VERSION "HNPBNNNYNNNNNNNNNNNNNNNNNNNNNNNNYNYYYYYYYY>4>%%%/4>'%**4YYY///"

NS_ :

BS_:

BU_: TESTER TCU BMU2 CSM CMU_TEST CMU_12 CMU_11 CMU_10 CMU_09 CMU_08 CMU_07 CMU_06 CMU_05 CMU_04 CMU_03 CMU_02 CMU_01 CMU_00 BMU

BO_ 1151 NM_TCU: 8 TCU
 SG_ NM_TCU : 7|64@0+ (1,0) [0|0] "" Vector__XXX

BO_ 1847 D_RS_DAS_TCU: 8 TCU
 SG_ D_RS_DAS_TCU : 7|64@0+ (1,0) [0|0] ""  TESTER

BO_ 1846 D_RQ_DAS_TCU: 8 TESTER
 SG_ D_RQ_DAS_TCU : 7|64@0+ (1,0) [0|0] ""  TCU

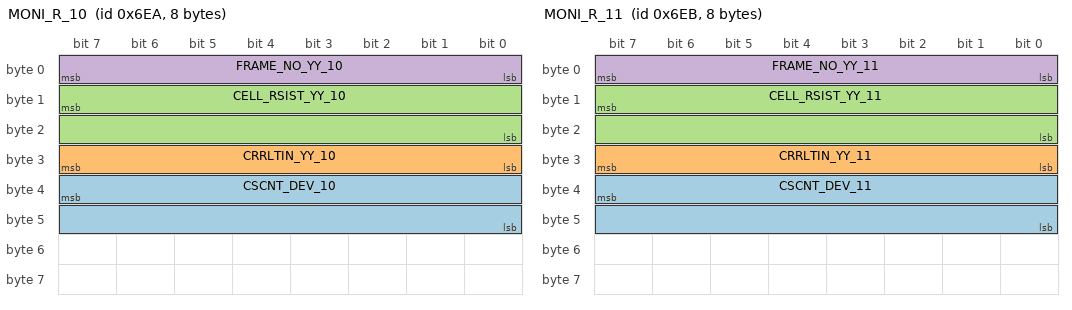
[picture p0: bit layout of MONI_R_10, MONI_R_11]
BO_ 1770 MONI_R_10: 8 BMU2
 SG_ CSCNT_DEV_10 : 39|16@0+ (0.1,0) [0|800] "A"  TCU,CMU_TEST
 SG_ CRRLTIN_YY_10 : 24|8@1+ (0.01,-1) [-1|1] ""  TCU,CMU_TEST
 SG_ CELL_RSIST_YY_10 : 15|16@0+ (0.01,0) [0|655.34] "mohm"  TCU,CMU_TEST
 SG_ FRAME_NO_YY_10 : 0|8@1+ (1,0) [0|8] ""  CMU_TEST

BO_ 1771 MONI_R_11: 8 BMU2
 SG_ CSCNT_DEV_11 : 39|16@0+ (0.1,0) [0|800] "A"  TCU,CMU_TEST
 SG_ CRRLTIN_YY_11 : 24|8@1+ (0.01,-1) [-1|1] ""  TCU,CMU_TEST
 SG_ CELL_RSIST_YY_11 : 15|16@0+ (0.01,0) [0|655.34] "mohm"  TCU,CMU_TEST
 SG_ FRAME_NO_YY_11 : 0|8@1+ (1,0) [0|8] ""  CMU_TEST

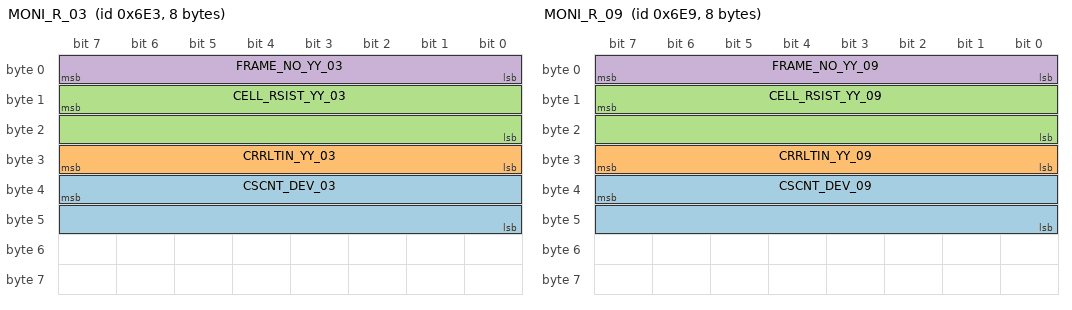
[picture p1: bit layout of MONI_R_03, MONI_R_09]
BO_ 1763 MONI_R_03: 8 BMU2
 SG_ CSCNT_DEV_03 : 39|16@0+ (0.1,0) [0|800] "A"  TCU,CMU_TEST
 SG_ CRRLTIN_YY_03 : 24|8@1+ (0.01,-1) [-1|1] ""  TCU,CMU_TEST
 SG_ CELL_RSIST_YY_03 : 15|16@0+ (0.01,0) [0|655.34] "mohm"  TCU,CMU_TEST
 SG_ FRAME_NO_YY_03 : 0|8@1+ (1,0) [0|8] ""  CMU_TEST

BO_ 1769 MONI_R_09: 8 BMU2
 SG_ CSCNT_DEV_09 : 39|16@0+ (0.1,0) [0|800] "A"  TCU,CMU_TEST
 SG_ CRRLTIN_YY_09 : 24|8@1+ (0.01,-1) [-1|1] ""  TCU,CMU_TEST
 SG_ CELL_RSIST_YY_09 : 15|16@0+ (0.01,0) [0|655.34] "mohm"  TCU,CMU_TEST
 SG_ FRAME_NO_YY_09 : 0|8@1+ (1,0) [0|8] ""  CMU_TEST

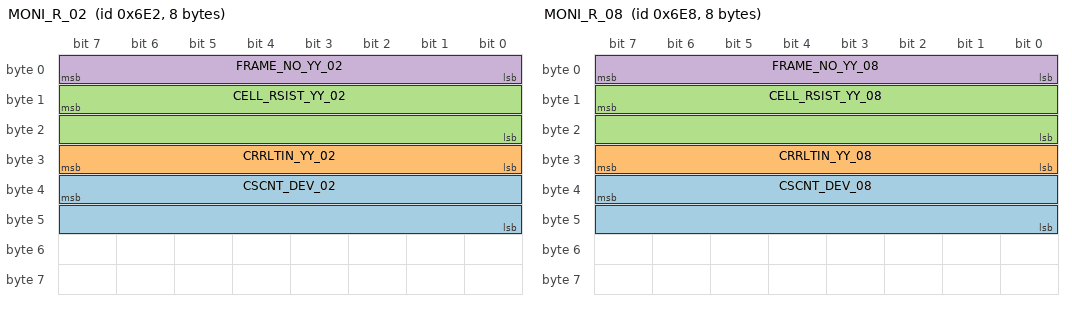
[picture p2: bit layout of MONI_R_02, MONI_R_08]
BO_ 1762 MONI_R_02: 8 BMU2
 SG_ CSCNT_DEV_02 : 39|16@0+ (0.1,0) [0|800] "A"  TCU,CMU_TEST
 SG_ CRRLTIN_YY_02 : 24|8@1+ (0.01,-1) [-1|1] ""  TCU,CMU_TEST
 SG_ CELL_RSIST_YY_02 : 15|16@0+ (0.01,0) [0|655.34] "mohm"  TCU,CMU_TEST
 SG_ FRAME_NO_YY_02 : 0|8@1+ (1,0) [0|8] ""  CMU_TEST

BO_ 1768 MONI_R_08: 8 BMU2
 SG_ CSCNT_DEV_08 : 39|16@0+ (0.1,0) [0|800] "A"  TCU,CMU_TEST
 SG_ CRRLTIN_YY_08 : 24|8@1+ (0.01,-1) [-1|1] ""  TCU,CMU_TEST
 SG_ CELL_RSIST_YY_08 : 15|16@0+ (0.01,0) [0|655.34] "mohm"  TCU,CMU_TEST
 SG_ FRAME_NO_YY_08 : 0|8@1+ (1,0) [0|8] ""  CMU_TEST

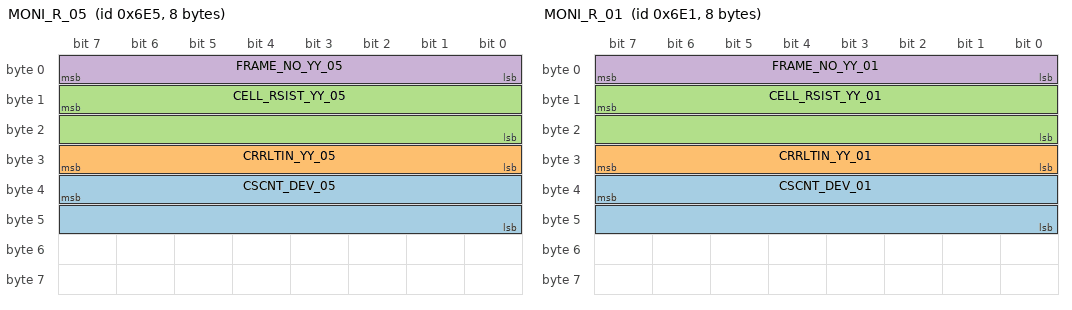
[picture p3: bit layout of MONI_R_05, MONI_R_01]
BO_ 1765 MONI_R_05: 8 BMU2
 SG_ CSCNT_DEV_05 : 39|16@0+ (0.1,0) [0|800] "A"  TCU,CMU_TEST
 SG_ CRRLTIN_YY_05 : 24|8@1+ (0.01,-1) [-1|1] ""  TCU,CMU_TEST
 SG_ CELL_RSIST_YY_05 : 15|16@0+ (0.01,0) [0|655.34] "mohm"  TCU,CMU_TEST
 SG_ FRAME_NO_YY_05 : 0|8@1+ (1,0) [0|8] ""  CMU_TEST

BO_ 1761 MONI_R_01: 8 BMU2
 SG_ CSCNT_DEV_01 : 39|16@0+ (0.1,0) [0|800] "A"  TCU,CMU_TEST
 SG_ CRRLTIN_YY_01 : 24|8@1+ (0.01,-1) [-1|1] ""  TCU,CMU_TEST
 SG_ CELL_RSIST_YY_01 : 15|16@0+ (0.01,0) [0|655.34] "mohm"  TCU,CMU_TEST
 SG_ FRAME_NO_YY_01 : 0|8@1+ (1,0) [0|8] ""  CMU_TEST

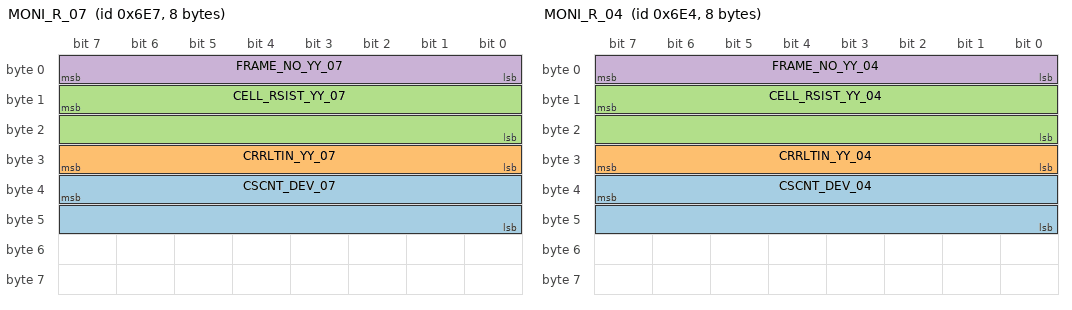
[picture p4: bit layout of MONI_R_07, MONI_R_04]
BO_ 1767 MONI_R_07: 8 BMU2
 SG_ CSCNT_DEV_07 : 39|16@0+ (0.1,0) [0|800] "A"  TCU,CMU_TEST
 SG_ CRRLTIN_YY_07 : 24|8@1+ (0.01,-1) [-1|1] ""  TCU,CMU_TEST
 SG_ CELL_RSIST_YY_07 : 15|16@0+ (0.01,0) [0|655.34] "mohm"  TCU,CMU_TEST
 SG_ FRAME_NO_YY_07 : 0|8@1+ (1,0) [0|8] ""  CMU_TEST

BO_ 1764 MONI_R_04: 8 BMU2
 SG_ CSCNT_DEV_04 : 39|16@0+ (0.1,0) [0|800] "A"  TCU,CMU_TEST
 SG_ CRRLTIN_YY_04 : 24|8@1+ (0.01,-1) [-1|1] ""  TCU,CMU_TEST
 SG_ CELL_RSIST_YY_04 : 15|16@0+ (0.01,0) [0|655.34] "mohm"  TCU,CMU_TEST
 SG_ FRAME_NO_YY_04 : 0|8@1+ (1,0) [0|8] ""  CMU_TEST

BO_ 962 CSM_OUT1: 8 CSM
 SG_ CSM_FAIL : 32|1@1+ (1,0) [0|0] ""  TCU,BMU2,BMU
 SG_ CSM_BATT_CURRENT : 7|32@0+ (0.001,-2147483.648) [-400|400] "A"  TCU,BMU2,BMU

BO_ 1733 CMU_RS5_12: 8 CMU_12
 SG_ BLC_DSTAT_HARN_12 : 0|1@1+ (1,0) [0|0] ""  TCU,BMU

BO_ 1717 CMU_RS5_11: 8 CMU_11
 SG_ BLC_DSTAT_HARN_11 : 0|1@1+ (1,0) [0|0] ""  TCU,BMU

BO_ 1701 CMU_RS5_10: 8 CMU_10
 SG_ BLC_DSTAT_HARN_10 : 0|1@1+ (1,0) [0|0] ""  TCU,BMU

BO_ 1685 CMU_RS5_09: 8 CMU_09
 SG_ BLC_DSTAT_HARN_09 : 0|1@1+ (1,0) [0|0] ""  TCU,BMU

BO_ 1669 CMU_RS5_08: 8 CMU_08
 SG_ BLC_DSTAT_HARN_08 : 0|1@1+ (1,0) [0|0] ""  TCU,BMU

BO_ 1653 CMU_RS5_07: 8 CMU_07
 SG_ BLC_DSTAT_HARN_07 : 0|1@1+ (1,0) [0|0] ""  TCU,BMU

BO_ 1637 CMU_RS5_06: 8 CMU_06
 SG_ BLC_DSTAT_HARN_06 : 0|1@1+ (1,0) [0|0] ""  TCU,BMU

BO_ 1621 CMU_RS5_05: 8 CMU_05
 SG_ BLC_DSTAT_HARN_05 : 0|1@1+ (1,0) [0|0] ""  TCU,BMU

BO_ 1605 CMU_RS5_04: 8 CMU_04
 SG_ BLC_DSTAT_HARN_04 : 0|1@1+ (1,0) [0|0] ""  TCU,BMU

BO_ 1589 CMU_RS5_03: 8 CMU_03
 SG_ BLC_DSTAT_HARN_03 : 0|1@1+ (1,0) [0|0] ""  TCU,BMU

BO_ 1573 CMU_RS5_02: 8 CMU_02
 SG_ BLC_DSTAT_HARN_02 : 0|1@1+ (1,0) [0|0] ""  TCU,BMU

BO_ 1557 CMU_RS5_01: 8 CMU_01
 SG_ BLC_DSTAT_HARN_01 : 0|1@1+ (1,0) [0|0] ""  TCU,BMU

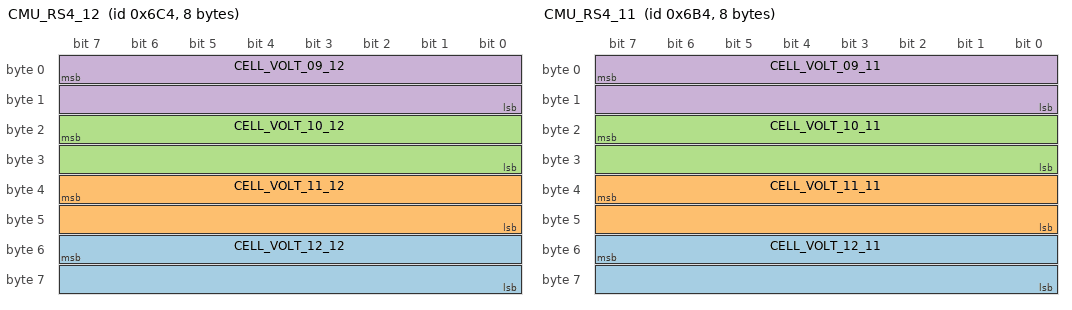
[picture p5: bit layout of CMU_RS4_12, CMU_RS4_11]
BO_ 1732 CMU_RS4_12: 8 CMU_12
 SG_ CELL_VOLT_12_12 : 55|16@0+ (0.001,0) [0|5] "V"  TCU,BMU
 SG_ CELL_VOLT_11_12 : 39|16@0+ (0.001,0) [0|5] "V"  TCU,BMU
 SG_ CELL_VOLT_10_12 : 23|16@0+ (0.001,0) [0|5] "V"  TCU,BMU
 SG_ CELL_VOLT_09_12 : 7|16@0+ (0.001,0) [0|5] "V"  TCU,BMU

BO_ 1716 CMU_RS4_11: 8 CMU_11
 SG_ CELL_VOLT_12_11 : 55|16@0+ (0.001,0) [0|5] "V"  TCU,BMU
 SG_ CELL_VOLT_11_11 : 39|16@0+ (0.001,0) [0|5] "V"  TCU,BMU
 SG_ CELL_VOLT_10_11 : 23|16@0+ (0.001,0) [0|5] "V"  TCU,BMU
 SG_ CELL_VOLT_09_11 : 7|16@0+ (0.001,0) [0|5] "V"  TCU,BMU

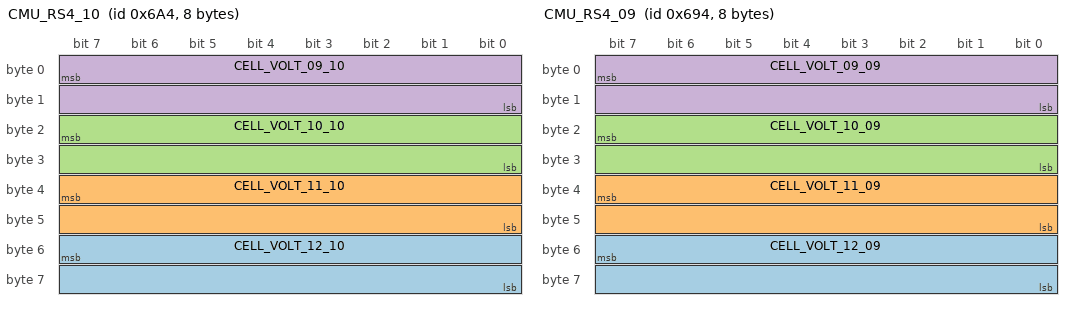
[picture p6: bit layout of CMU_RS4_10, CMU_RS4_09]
BO_ 1700 CMU_RS4_10: 8 CMU_10
 SG_ CELL_VOLT_12_10 : 55|16@0+ (0.001,0) [0|5] "V"  TCU,BMU
 SG_ CELL_VOLT_11_10 : 39|16@0+ (0.001,0) [0|5] "V"  TCU,BMU
 SG_ CELL_VOLT_10_10 : 23|16@0+ (0.001,0) [0|5] "V"  TCU,BMU
 SG_ CELL_VOLT_09_10 : 7|16@0+ (0.001,0) [0|5] "V"  TCU,BMU

BO_ 1684 CMU_RS4_09: 8 CMU_09
 SG_ CELL_VOLT_12_09 : 55|16@0+ (0.001,0) [0|5] "V"  TCU,BMU
 SG_ CELL_VOLT_11_09 : 39|16@0+ (0.001,0) [0|5] "V"  TCU,BMU
 SG_ CELL_VOLT_10_09 : 23|16@0+ (0.001,0) [0|5] "V"  TCU,BMU
 SG_ CELL_VOLT_09_09 : 7|16@0+ (0.001,0) [0|5] "V"  TCU,BMU

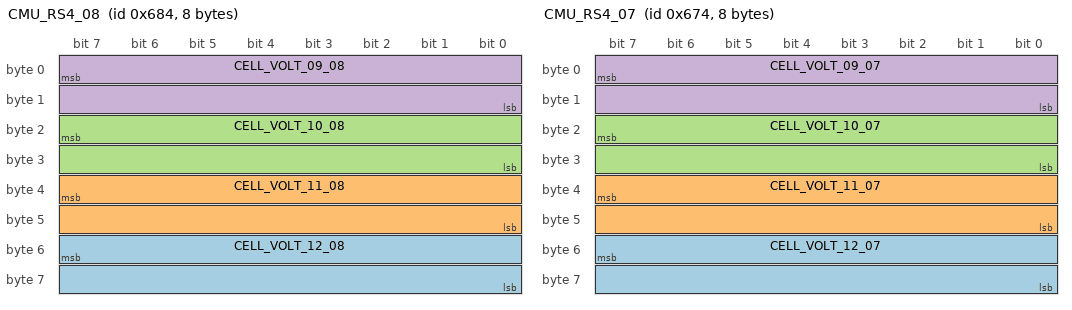
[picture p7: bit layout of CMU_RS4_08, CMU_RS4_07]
BO_ 1668 CMU_RS4_08: 8 CMU_08
 SG_ CELL_VOLT_12_08 : 55|16@0+ (0.001,0) [0|5] "V"  TCU,BMU
 SG_ CELL_VOLT_11_08 : 39|16@0+ (0.001,0) [0|5] "V"  TCU,BMU
 SG_ CELL_VOLT_10_08 : 23|16@0+ (0.001,0) [0|5] "V"  TCU,BMU
 SG_ CELL_VOLT_09_08 : 7|16@0+ (0.001,0) [0|5] "V"  TCU,BMU

BO_ 1652 CMU_RS4_07: 8 CMU_07
 SG_ CELL_VOLT_12_07 : 55|16@0+ (0.001,0) [0|5] "V"  TCU,BMU
 SG_ CELL_VOLT_11_07 : 39|16@0+ (0.001,0) [0|5] "V"  TCU,BMU
 SG_ CELL_VOLT_10_07 : 23|16@0+ (0.001,0) [0|5] "V"  TCU,BMU
 SG_ CELL_VOLT_09_07 : 7|16@0+ (0.001,0) [0|5] "V"  TCU,BMU

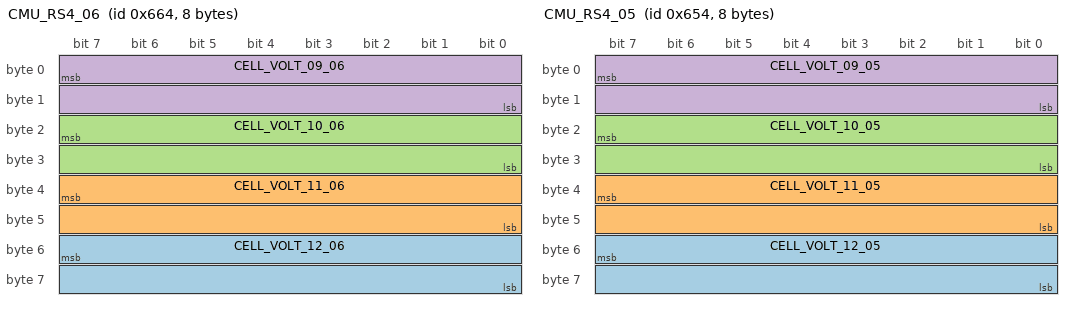
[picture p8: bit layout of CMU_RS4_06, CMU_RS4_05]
BO_ 1636 CMU_RS4_06: 8 CMU_06
 SG_ CELL_VOLT_12_06 : 55|16@0+ (0.001,0) [0|5] "V"  TCU,BMU
 SG_ CELL_VOLT_11_06 : 39|16@0+ (0.001,0) [0|5] "V"  TCU,BMU
 SG_ CELL_VOLT_10_06 : 23|16@0+ (0.001,0) [0|5] "V"  TCU,BMU
 SG_ CELL_VOLT_09_06 : 7|16@0+ (0.001,0) [0|5] "V"  TCU,BMU

BO_ 1620 CMU_RS4_05: 8 CMU_05
 SG_ CELL_VOLT_12_05 : 55|16@0+ (0.001,0) [0|5] "V"  TCU,BMU
 SG_ CELL_VOLT_11_05 : 39|16@0+ (0.001,0) [0|5] "V"  TCU,BMU
 SG_ CELL_VOLT_10_05 : 23|16@0+ (0.001,0) [0|5] "V"  TCU,BMU
 SG_ CELL_VOLT_09_05 : 7|16@0+ (0.001,0) [0|5] "V"  TCU,BMU

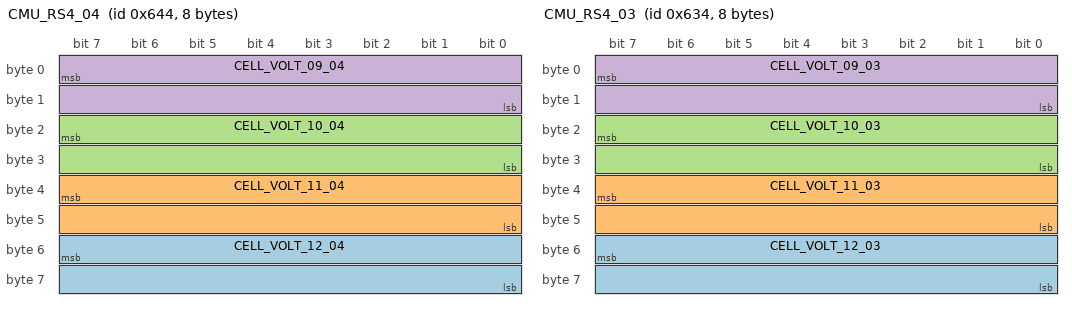
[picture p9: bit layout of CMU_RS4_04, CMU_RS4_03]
BO_ 1604 CMU_RS4_04: 8 CMU_04
 SG_ CELL_VOLT_12_04 : 55|16@0+ (0.001,0) [0|5] "V"  TCU,BMU
 SG_ CELL_VOLT_11_04 : 39|16@0+ (0.001,0) [0|5] "V"  TCU,BMU
 SG_ CELL_VOLT_10_04 : 23|16@0+ (0.001,0) [0|5] "V"  TCU,BMU
 SG_ CELL_VOLT_09_04 : 7|16@0+ (0.001,0) [0|5] "V"  TCU,BMU

BO_ 1588 CMU_RS4_03: 8 CMU_03
 SG_ CELL_VOLT_12_03 : 55|16@0+ (0.001,0) [0|5] "V"  TCU,BMU
 SG_ CELL_VOLT_11_03 : 39|16@0+ (0.001,0) [0|5] "V"  TCU,BMU
 SG_ CELL_VOLT_10_03 : 23|16@0+ (0.001,0) [0|5] "V"  TCU,BMU
 SG_ CELL_VOLT_09_03 : 7|16@0+ (0.001,0) [0|5] "V"  TCU,BMU

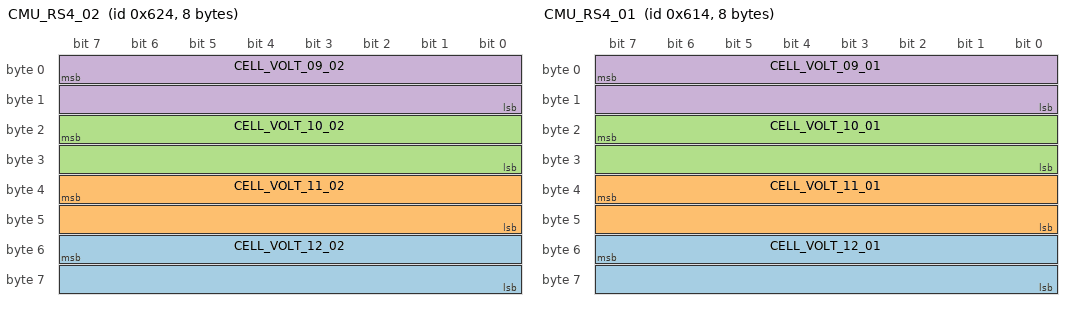
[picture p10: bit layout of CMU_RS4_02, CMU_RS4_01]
BO_ 1572 CMU_RS4_02: 8 CMU_02
 SG_ CELL_VOLT_12_02 : 55|16@0+ (0.001,0) [0|5] "V"  TCU,BMU
 SG_ CELL_VOLT_11_02 : 39|16@0+ (0.001,0) [0|5] "V"  TCU,BMU
 SG_ CELL_VOLT_10_02 : 23|16@0+ (0.001,0) [0|5] "V"  TCU,BMU
 SG_ CELL_VOLT_09_02 : 7|16@0+ (0.001,0) [0|5] "V"  TCU,BMU

BO_ 1556 CMU_RS4_01: 8 CMU_01
 SG_ CELL_VOLT_12_01 : 55|16@0+ (0.001,0) [0|5] "V"  TCU,BMU
 SG_ CELL_VOLT_11_01 : 39|16@0+ (0.001,0) [0|5] "V"  TCU,BMU
 SG_ CELL_VOLT_10_01 : 23|16@0+ (0.001,0) [0|5] "V"  TCU,BMU
 SG_ CELL_VOLT_09_01 : 7|16@0+ (0.001,0) [0|5] "V"  TCU,BMU

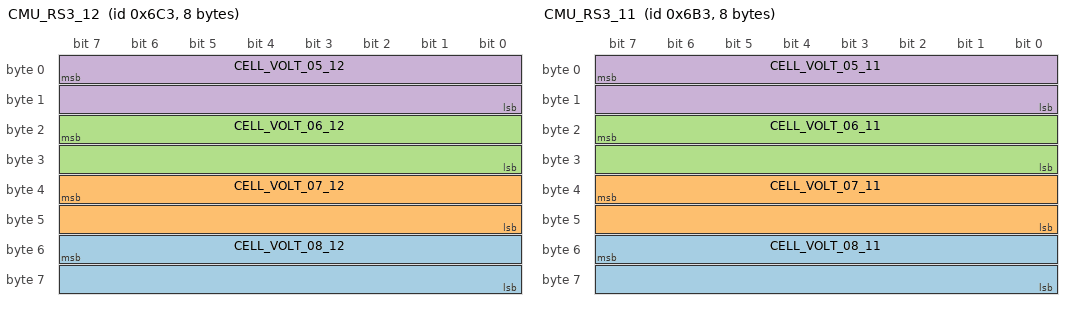
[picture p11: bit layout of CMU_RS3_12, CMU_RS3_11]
BO_ 1731 CMU_RS3_12: 8 CMU_12
 SG_ CELL_VOLT_08_12 : 55|16@0+ (0.001,0) [0|5] "V"  TCU,BMU
 SG_ CELL_VOLT_07_12 : 39|16@0+ (0.001,0) [0|5] "V"  TCU,BMU
 SG_ CELL_VOLT_06_12 : 23|16@0+ (0.001,0) [0|5] "V"  TCU,BMU
 SG_ CELL_VOLT_05_12 : 7|16@0+ (0.001,0) [0|5] "V"  TCU,BMU

BO_ 1715 CMU_RS3_11: 8 CMU_11
 SG_ CELL_VOLT_08_11 : 55|16@0+ (0.001,0) [0|5] "V"  TCU,BMU2,BMU
 SG_ CELL_VOLT_07_11 : 39|16@0+ (0.001,0) [0|5] "V"  TCU,BMU2,BMU
 SG_ CELL_VOLT_06_11 : 23|16@0+ (0.001,0) [0|5] "V"  TCU,BMU2,BMU
 SG_ CELL_VOLT_05_11 : 7|16@0+ (0.001,0) [0|5] "V"  TCU,BMU2,BMU

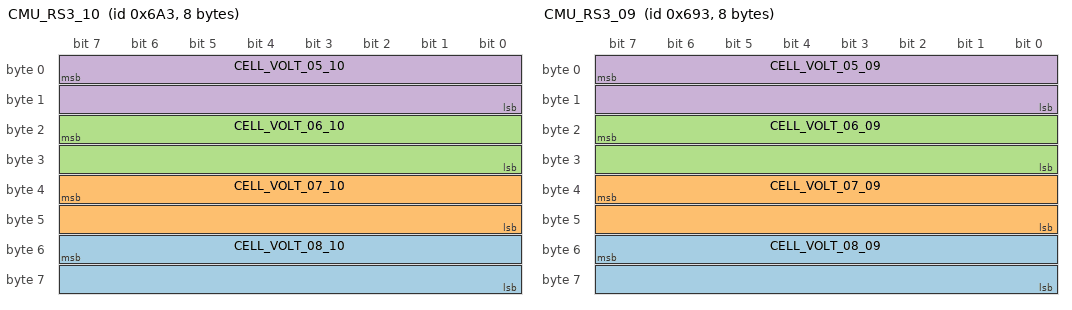
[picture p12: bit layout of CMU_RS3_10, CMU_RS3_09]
BO_ 1699 CMU_RS3_10: 8 CMU_10
 SG_ CELL_VOLT_08_10 : 55|16@0+ (0.001,0) [0|5] "V"  TCU,BMU2,BMU
 SG_ CELL_VOLT_07_10 : 39|16@0+ (0.001,0) [0|5] "V"  TCU,BMU2,BMU
 SG_ CELL_VOLT_06_10 : 23|16@0+ (0.001,0) [0|5] "V"  TCU,BMU2,BMU
 SG_ CELL_VOLT_05_10 : 7|16@0+ (0.001,0) [0|5] "V"  TCU,BMU2,BMU

BO_ 1683 CMU_RS3_09: 8 CMU_09
 SG_ CELL_VOLT_08_09 : 55|16@0+ (0.001,0) [0|5] "V"  TCU,BMU2,BMU
 SG_ CELL_VOLT_07_09 : 39|16@0+ (0.001,0) [0|5] "V"  TCU,BMU2,BMU
 SG_ CELL_VOLT_06_09 : 23|16@0+ (0.001,0) [0|5] "V"  TCU,BMU2,BMU
 SG_ CELL_VOLT_05_09 : 7|16@0+ (0.001,0) [0|5] "V"  TCU,BMU2,BMU

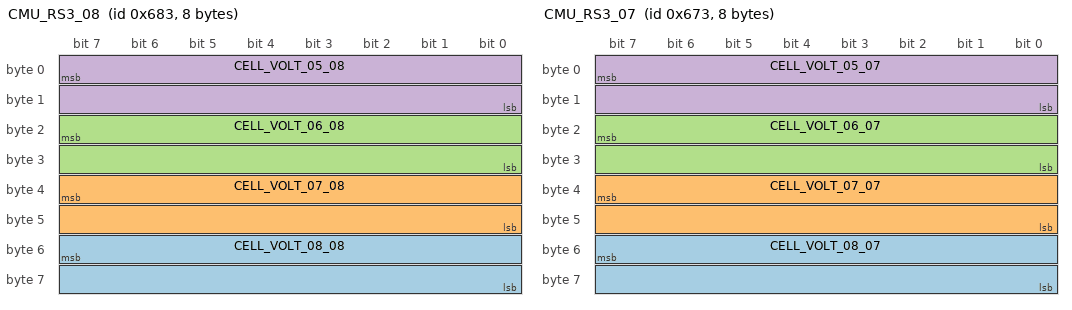
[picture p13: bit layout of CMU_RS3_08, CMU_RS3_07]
BO_ 1667 CMU_RS3_08: 8 CMU_08
 SG_ CELL_VOLT_08_08 : 55|16@0+ (0.001,0) [0|5] "V"  TCU,BMU2,BMU
 SG_ CELL_VOLT_07_08 : 39|16@0+ (0.001,0) [0|5] "V"  TCU,BMU2,BMU
 SG_ CELL_VOLT_06_08 : 23|16@0+ (0.001,0) [0|5] "V"  TCU,BMU2,BMU
 SG_ CELL_VOLT_05_08 : 7|16@0+ (0.001,0) [0|5] "V"  TCU,BMU2,BMU

BO_ 1651 CMU_RS3_07: 8 CMU_07
 SG_ CELL_VOLT_08_07 : 55|16@0+ (0.001,0) [0|5] "V"  TCU,BMU2,BMU
 SG_ CELL_VOLT_07_07 : 39|16@0+ (0.001,0) [0|5] "V"  TCU,BMU2,BMU
 SG_ CELL_VOLT_06_07 : 23|16@0+ (0.001,0) [0|5] "V"  TCU,BMU2,BMU
 SG_ CELL_VOLT_05_07 : 7|16@0+ (0.001,0) [0|5] "V"  TCU,BMU2,BMU

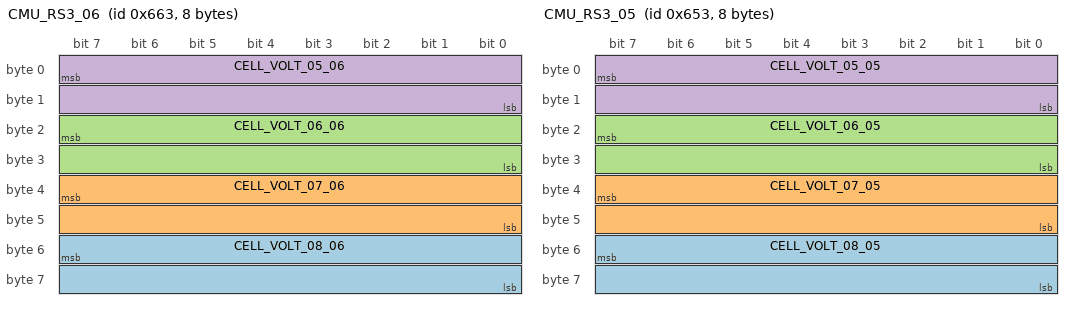
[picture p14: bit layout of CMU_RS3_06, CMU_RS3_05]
BO_ 1635 CMU_RS3_06: 8 CMU_06
 SG_ CELL_VOLT_08_06 : 55|16@0+ (0.001,0) [0|5] "V"  TCU,BMU
 SG_ CELL_VOLT_07_06 : 39|16@0+ (0.001,0) [0|5] "V"  TCU,BMU
 SG_ CELL_VOLT_06_06 : 23|16@0+ (0.001,0) [0|5] "V"  TCU,BMU
 SG_ CELL_VOLT_05_06 : 7|16@0+ (0.001,0) [0|5] "V"  TCU,BMU

BO_ 1619 CMU_RS3_05: 8 CMU_05
 SG_ CELL_VOLT_08_05 : 55|16@0+ (0.001,0) [0|5] "V"  TCU,BMU2,BMU
 SG_ CELL_VOLT_07_05 : 39|16@0+ (0.001,0) [0|5] "V"  TCU,BMU2,BMU
 SG_ CELL_VOLT_06_05 : 23|16@0+ (0.001,0) [0|5] "V"  TCU,BMU2,BMU
 SG_ CELL_VOLT_05_05 : 7|16@0+ (0.001,0) [0|5] "V"  TCU,BMU2,BMU

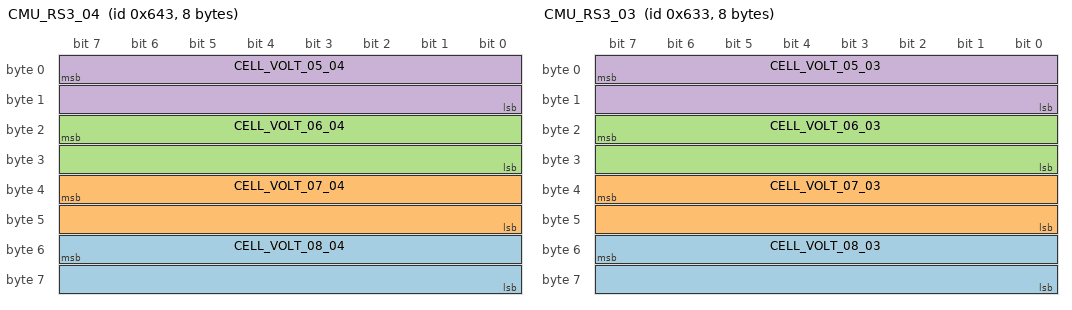
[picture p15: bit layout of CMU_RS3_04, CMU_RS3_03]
BO_ 1603 CMU_RS3_04: 8 CMU_04
 SG_ CELL_VOLT_08_04 : 55|16@0+ (0.001,0) [0|5] "V"  TCU,BMU2,BMU
 SG_ CELL_VOLT_07_04 : 39|16@0+ (0.001,0) [0|5] "V"  TCU,BMU2,BMU
 SG_ CELL_VOLT_06_04 : 23|16@0+ (0.001,0) [0|5] "V"  TCU,BMU2,BMU
 SG_ CELL_VOLT_05_04 : 7|16@0+ (0.001,0) [0|5] "V"  TCU,BMU2,BMU

BO_ 1587 CMU_RS3_03: 8 CMU_03
 SG_ CELL_VOLT_08_03 : 55|16@0+ (0.001,0) [0|5] "V"  TCU,BMU2,BMU
 SG_ CELL_VOLT_07_03 : 39|16@0+ (0.001,0) [0|5] "V"  TCU,BMU2,BMU
 SG_ CELL_VOLT_06_03 : 23|16@0+ (0.001,0) [0|5] "V"  TCU,BMU2,BMU
 SG_ CELL_VOLT_05_03 : 7|16@0+ (0.001,0) [0|5] "V"  TCU,BMU2,BMU

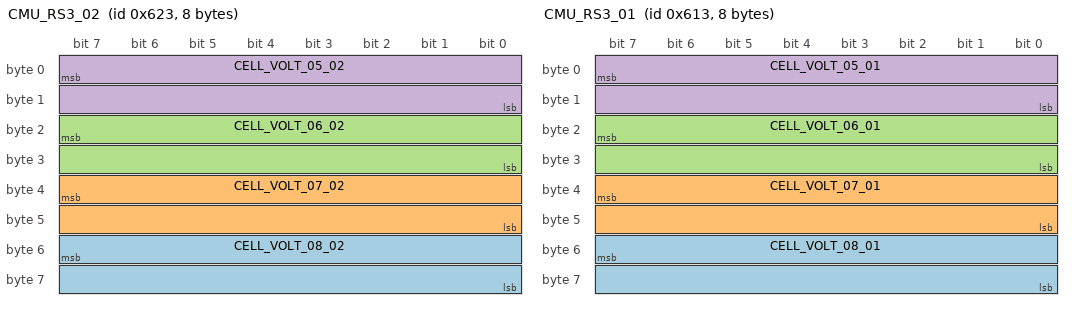
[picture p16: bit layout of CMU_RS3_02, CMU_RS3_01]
BO_ 1571 CMU_RS3_02: 8 CMU_02
 SG_ CELL_VOLT_08_02 : 55|16@0+ (0.001,0) [0|5] "V"  TCU,BMU2,BMU
 SG_ CELL_VOLT_07_02 : 39|16@0+ (0.001,0) [0|5] "V"  TCU,BMU2,BMU
 SG_ CELL_VOLT_06_02 : 23|16@0+ (0.001,0) [0|5] "V"  TCU,BMU2,BMU
 SG_ CELL_VOLT_05_02 : 7|16@0+ (0.001,0) [0|5] "V"  TCU,BMU2,BMU

BO_ 1555 CMU_RS3_01: 8 CMU_01
 SG_ CELL_VOLT_08_01 : 55|16@0+ (0.001,0) [0|5] "V"  TCU,BMU2,BMU
 SG_ CELL_VOLT_07_01 : 39|16@0+ (0.001,0) [0|5] "V"  TCU,BMU2,BMU
 SG_ CELL_VOLT_06_01 : 23|16@0+ (0.001,0) [0|5] "V"  TCU,BMU2,BMU
 SG_ CELL_VOLT_05_01 : 7|16@0+ (0.001,0) [0|5] "V"  TCU,BMU2,BMU

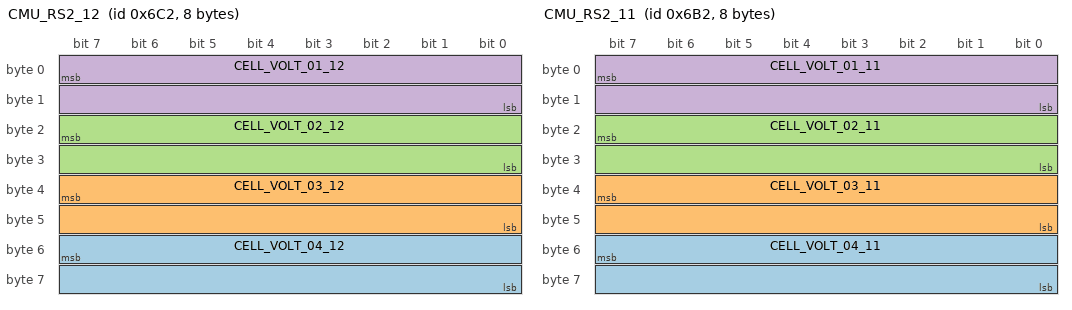
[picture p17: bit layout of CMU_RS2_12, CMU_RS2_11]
BO_ 1730 CMU_RS2_12: 8 CMU_12
 SG_ CELL_VOLT_04_12 : 55|16@0+ (0.001,0) [0|5] "V"  TCU,BMU
 SG_ CELL_VOLT_03_12 : 39|16@0+ (0.001,0) [0|5] "V"  TCU,BMU
 SG_ CELL_VOLT_02_12 : 23|16@0+ (0.001,0) [0|5] "V"  TCU,BMU
 SG_ CELL_VOLT_01_12 : 7|16@0+ (0.001,0) [0|5] "V"  TCU,BMU

BO_ 1714 CMU_RS2_11: 8 CMU_11
 SG_ CELL_VOLT_04_11 : 55|16@0+ (0.001,0) [0|5] "V"  TCU,BMU2,BMU
 SG_ CELL_VOLT_03_11 : 39|16@0+ (0.001,0) [0|5] "V"  TCU,BMU2,BMU
 SG_ CELL_VOLT_02_11 : 23|16@0+ (0.001,0) [0|5] "V"  TCU,BMU2,BMU
 SG_ CELL_VOLT_01_11 : 7|16@0+ (0.001,0) [0|5] "V"  TCU,BMU2,BMU

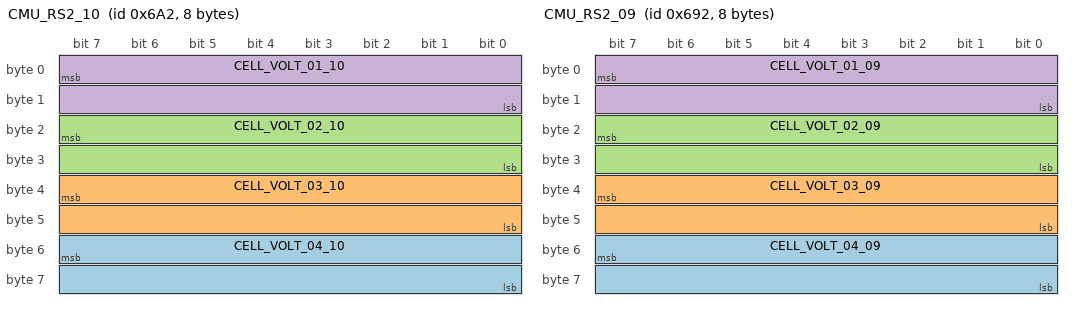
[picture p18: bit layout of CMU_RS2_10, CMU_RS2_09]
BO_ 1698 CMU_RS2_10: 8 CMU_10
 SG_ CELL_VOLT_04_10 : 55|16@0+ (0.001,0) [0|5] "V"  TCU,BMU2,BMU
 SG_ CELL_VOLT_03_10 : 39|16@0+ (0.001,0) [0|5] "V"  TCU,BMU2,BMU
 SG_ CELL_VOLT_02_10 : 23|16@0+ (0.001,0) [0|5] "V"  TCU,BMU2,BMU
 SG_ CELL_VOLT_01_10 : 7|16@0+ (0.001,0) [0|5] "V"  TCU,BMU2,BMU

BO_ 1682 CMU_RS2_09: 8 CMU_09
 SG_ CELL_VOLT_04_09 : 55|16@0+ (0.001,0) [0|5] "V"  TCU,BMU2,BMU
 SG_ CELL_VOLT_03_09 : 39|16@0+ (0.001,0) [0|5] "V"  TCU,BMU2,BMU
 SG_ CELL_VOLT_02_09 : 23|16@0+ (0.001,0) [0|5] "V"  TCU,BMU2,BMU
 SG_ CELL_VOLT_01_09 : 7|16@0+ (0.001,0) [0|5] "V"  TCU,BMU2,BMU

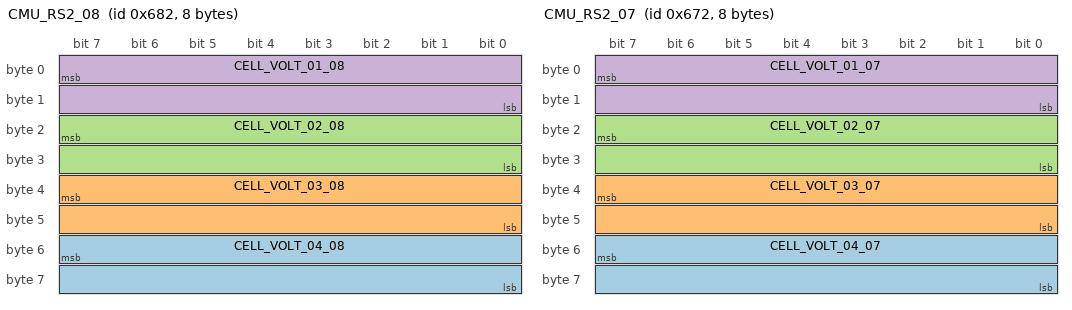
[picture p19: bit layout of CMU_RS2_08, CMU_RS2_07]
BO_ 1666 CMU_RS2_08: 8 CMU_08
 SG_ CELL_VOLT_04_08 : 55|16@0+ (0.001,0) [0|5] "V"  TCU,BMU2,BMU
 SG_ CELL_VOLT_03_08 : 39|16@0+ (0.001,0) [0|5] "V"  TCU,BMU2,BMU
 SG_ CELL_VOLT_02_08 : 23|16@0+ (0.001,0) [0|5] "V"  TCU,BMU2,BMU
 SG_ CELL_VOLT_01_08 : 7|16@0+ (0.001,0) [0|5] "V"  TCU,BMU2,BMU

BO_ 1650 CMU_RS2_07: 8 CMU_07
 SG_ CELL_VOLT_04_07 : 55|16@0+ (0.001,0) [0|5] "V"  TCU,BMU2,BMU
 SG_ CELL_VOLT_03_07 : 39|16@0+ (0.001,0) [0|5] "V"  TCU,BMU2,BMU
 SG_ CELL_VOLT_02_07 : 23|16@0+ (0.001,0) [0|5] "V"  TCU,BMU2,BMU
 SG_ CELL_VOLT_01_07 : 7|16@0+ (0.001,0) [0|5] "V"  TCU,BMU2,BMU

BO_ 1634 CMU_RS2_06: 8 CMU_06
 SG_ CELL_VOLT_04_06 : 55|16@0+ (0.001,0) [0|5] "V"  TCU,BMU
 SG_ CELL_VOLT_03_06 : 39|16@0+ (0.001,0) [0|5] "V"  TCU,BMU
 SG_ CELL_VOLT_02_06 : 23|16@0+ (0.001,0) [0|5] "V"  TCU,BMU
 SG_ CELL_VOLT_01_06 : 7|16@0+ (0.001,0) [0|5] "V"  TCU,BMU

BO_ 1618 CMU_RS2_05: 8 CMU_05
 SG_ CELL_VOLT_04_05 : 55|16@0+ (0.001,0) [0|5] "V"  TCU,BMU2,BMU
 SG_ CELL_VOLT_03_05 : 39|16@0+ (0.001,0) [0|5] "V"  TCU,BMU2,BMU
 SG_ CELL_VOLT_02_05 : 23|16@0+ (0.001,0) [0|5] "V"  TCU,BMU2,BMU
 SG_ CELL_VOLT_01_05 : 7|16@0+ (0.001,0) [0|5] "V"  TCU,BMU2,BMU

BO_ 1602 CMU_RS2_04: 8 CMU_04
 SG_ CELL_VOLT_04_04 : 55|16@0+ (0.001,0) [0|5] "V"  TCU,BMU2,BMU
 SG_ CELL_VOLT_03_04 : 39|16@0+ (0.001,0) [0|5] "V"  TCU,BMU2,BMU
 SG_ CELL_VOLT_02_04 : 23|16@0+ (0.001,0) [0|5] "V"  TCU,BMU2,BMU
 SG_ CELL_VOLT_01_04 : 7|16@0+ (0.001,0) [0|5] "V"  TCU,BMU2,BMU

BO_ 1586 CMU_RS2_03: 8 CMU_03
 SG_ CELL_VOLT_04_03 : 55|16@0+ (0.001,0) [0|5] "V"  TCU,BMU2,BMU
 SG_ CELL_VOLT_03_03 : 39|16@0+ (0.001,0) [0|5] "V"  TCU,BMU2,BMU
 SG_ CELL_VOLT_02_03 : 23|16@0+ (0.001,0) [0|5] "V"  TCU,BMU2,BMU
 SG_ CELL_VOLT_01_03 : 7|16@0+ (0.001,0) [0|5] "V"  TCU,BMU2,BMU

BO_ 1570 CMU_RS2_02: 8 CMU_02
 SG_ CELL_VOLT_04_02 : 55|16@0+ (0.001,0) [0|5] "V"  TCU,BMU2,BMU
 SG_ CELL_VOLT_03_02 : 39|16@0+ (0.001,0) [0|5] "V"  TCU,BMU2,BMU
 SG_ CELL_VOLT_02_02 : 23|16@0+ (0.001,0) [0|5] "V"  TCU,BMU2,BMU
 SG_ CELL_VOLT_01_02 : 7|16@0+ (0.001,0) [0|5] "V"  TCU,BMU2,BMU

BO_ 1554 CMU_RS2_01: 8 CMU_01
 SG_ CELL_VOLT_04_01 : 55|16@0+ (0.001,0) [0|5] "V"  TCU,BMU2,BMU
 SG_ CELL_VOLT_03_01 : 39|16@0+ (0.001,0) [0|5] "V"  TCU,BMU2,BMU
 SG_ CELL_VOLT_02_01 : 23|16@0+ (0.001,0) [0|5] "V"  TCU,BMU2,BMU
 SG_ CELL_VOLT_01_01 : 7|16@0+ (0.001,0) [0|5] "V"  TCU,BMU2,BMU

BO_ 1729 CMU_RS1_12: 8 CMU_12
 SG_ MODULE_TEMP_06_12 : 56|8@1+ (1,-70) [-70|130] "°C"  TCU,BMU
 SG_ MODULE_TEMP_05_12 : 48|8@1+ (1,-70) [-70|130] "°C"  TCU,BMU
 SG_ MODULE_TEMP_04_12 : 40|8@1+ (1,-70) [-70|130] "°C"  TCU,BMU
 SG_ MODULE_TEMP_03_12 : 32|8@1+ (1,-70) [-70|130] "°C"  TCU,BMU
 SG_ MODULE_TEMP_02_12 : 24|8@1+ (1,-70) [-70|130] "°C"  TCU,BMU
 SG_ MODULE_TEMP_01_12 : 16|8@1+ (1,-70) [-70|130] "°C"  TCU,BMU
 SG_ NUM_TABLE_VALUE_12 : 12|4@1+ (1,0) [0|0] ""  BMU
 SG_ BLC_DRV_STAT_12_12 : 11|1@1+ (1,0) [0|0] ""  TCU,BMU
 SG_ BLC_DRV_STAT_11_12 : 10|1@1+ (1,0) [0|0] ""  TCU,BMU
 SG_ BLC_DRV_STAT_10_12 : 9|1@1+ (1,0) [0|0] ""  TCU,BMU
 SG_ BLC_DRV_STAT_09_12 : 8|1@1+ (1,0) [0|0] ""  TCU,BMU
 SG_ BLC_DRV_STAT_08_12 : 7|1@1+ (1,0) [0|0] ""  TCU,BMU
 SG_ BLC_DRV_STAT_07_12 : 6|1@1+ (1,0) [0|0] ""  TCU,BMU
 SG_ BLC_DRV_STAT_06_12 : 5|1@1+ (1,0) [0|0] ""  TCU,BMU
 SG_ BLC_DRV_STAT_05_12 : 4|1@1+ (1,0) [0|0] ""  TCU,BMU
 SG_ BLC_DRV_STAT_04_12 : 3|1@1+ (1,0) [0|0] ""  TCU,BMU
 SG_ BLC_DRV_STAT_03_12 : 2|1@1+ (1,0) [0|0] ""  TCU,BMU
 SG_ BLC_DRV_STAT_02_12 : 1|1@1+ (1,0) [0|0] ""  TCU,BMU
 SG_ BLC_DRV_STAT_01_12 : 0|1@1+ (1,0) [0|0] ""  TCU,BMU

CM_ SG_ 1770 CSCNT_DEV_10 "CMU_10 CSCNT_DEV";
CM_ SG_ 1770 CRRLTIN_YY_10 "CELL_08 CRRLTIN";
CM_ SG_ 1770 CELL_RSIST_YY_10 "CELL_yy INT_RESIST";
CM_ SG_ 1770 FRAME_NO_YY_10 "Automatic numbering table";
CM_ SG_ 1771 CSCNT_DEV_11 "CMU_11 CSCNT_DEV";
CM_ SG_ 1771 CRRLTIN_YY_11 "CELL_08 CRRLTIN";
CM_ SG_ 1771 CELL_RSIST_YY_11 "CELL_yy INT_RESIST";
CM_ SG_ 1771 FRAME_NO_YY_11 "Automatic numbering table";
CM_ SG_ 1763 CSCNT_DEV_03 "CMU_03 CSCNT_DEV";
CM_ SG_ 1763 CRRLTIN_YY_03 "CELL_08 CRRLTIN";
CM_ SG_ 1763 CELL_RSIST_YY_03 "CELL_yy INT_RESIST";
CM_ SG_ 1763 FRAME_NO_YY_03 "Automatic numbering table";
CM_ SG_ 1769 CSCNT_DEV_09 "CMU_09 CSCNT_DEV";
CM_ SG_ 1769 CRRLTIN_YY_09 "CELL_08 CRRLTIN";
CM_ SG_ 1769 CELL_RSIST_YY_09 "CELL_yy INT_RESIST";
CM_ SG_ 1769 FRAME_NO_YY_09 "Automatic numbering table";
CM_ SG_ 1762 CSCNT_DEV_02 "CMU_02 CSCNT_DEV";
CM_ SG_ 1762 CRRLTIN_YY_02 "CELL_08 CRRLTIN";
CM_ SG_ 1762 CELL_RSIST_YY_02 "CELL_yy INT_RESIST";
CM_ SG_ 1762 FRAME_NO_YY_02 "Automatic numbering table";
CM_ SG_ 1768 CSCNT_DEV_08 "CMU_08 CSCNT_DEV";
CM_ SG_ 1768 CRRLTIN_YY_08 "CELL_08 CRRLTIN";
CM_ SG_ 1768 CELL_RSIST_YY_08 "CELL_yy INT_RESIST";
CM_ SG_ 1768 FRAME_NO_YY_08 "Automatic numbering table";
CM_ SG_ 1765 CSCNT_DEV_05 "CMU_05 CSCNT_DEV";
CM_ SG_ 1765 CRRLTIN_YY_05 "CELL_08 CRRLTIN";
CM_ SG_ 1765 CELL_RSIST_YY_05 "CELL_yy INT_RESIST";
CM_ SG_ 1765 FRAME_NO_YY_05 "Automatic numbering table";
CM_ SG_ 1761 CSCNT_DEV_01 "CMU_01 CSCNT_DEV";
CM_ SG_ 1761 CRRLTIN_YY_01 "CELL_08 CRRLTIN";
CM_ SG_ 1761 CELL_RSIST_YY_01 "CELL_yy INT_RESIST";
CM_ SG_ 1761 FRAME_NO_YY_01 "Automatic numbering table";
CM_ SG_ 1767 CSCNT_DEV_07 "CMU_07 CSCNT_DEV";
CM_ SG_ 1767 CRRLTIN_YY_07 "CELL_08 CRRLTIN";
CM_ SG_ 1767 CELL_RSIST_YY_07 "CELL_yy INT_RESIST";
CM_ SG_ 1767 FRAME_NO_YY_07 "Automatic numbering table";
CM_ SG_ 1764 CSCNT_DEV_04 "CMU_04 CSCNT_DEV";
CM_ SG_ 1764 CRRLTIN_YY_04 "CELL_08 CRRLTIN";
CM_ SG_ 1764 CELL_RSIST_YY_04 "CELL_yy INT_RESIST";
CM_ SG_ 1764 FRAME_NO_YY_04 "Automatic numbering table";
CM_ SG_ 962 CSM_FAIL "Current sensor fail  0:normal 1:fail";
CM_ SG_ 962 CSM_BATT_CURRENT "Battery current value detected by current sensor";
CM_ SG_ 1733 BLC_DSTAT_HARN_12 "Balancer drive status to detect open circuit12";
CM_ SG_ 1717 BLC_DSTAT_HARN_11 "Balancer drive status to detect open circuit11";
CM_ SG_ 1701 BLC_DSTAT_HARN_10 "Balancer drive status to detect open circuit10";
CM_ SG_ 1685 BLC_DSTAT_HARN_09 "Balancer drive status to detect open circuit09";
CM_ SG_ 1669 BLC_DSTAT_HARN_08 "Balancer drive status to detect open circuit08";
CM_ SG_ 1653 BLC_DSTAT_HARN_07 "Balancer drive status to detect open circuit07";
CM_ SG_ 1637 BLC_DSTAT_HARN_06 "Balancer drive status to detect open circuit06";
CM_ SG_ 1621 BLC_DSTAT_HARN_05 "Balancer drive status to detect open circuit05";
CM_ SG_ 1605 BLC_DSTAT_HARN_04 "Balancer drive status to detect open circuit04";
CM_ SG_ 1589 BLC_DSTAT_HARN_03 "Balancer drive status to detect open circuit03";
CM_ SG_ 1573 BLC_DSTAT_HARN_02 "Balancer drive status to detect open circuit02";
CM_ SG_ 1557 BLC_DSTAT_HARN_01 "Balancer drive status to detect open circuit01";
CM_ SG_ 1732 CELL_VOLT_12_12 "CELL_12 Voltage";
CM_ SG_ 1732 CELL_VOLT_11_12 "CELL_11 Voltage";
CM_ SG_ 1732 CELL_VOLT_10_12 "CELL_10 Voltage";
CM_ SG_ 1732 CELL_VOLT_09_12 "CELL_09 Voltage";
CM_ SG_ 1716 CELL_VOLT_12_11 "CELL_12 Voltage";
CM_ SG_ 1716 CELL_VOLT_11_11 "CELL_11 Voltage";
CM_ SG_ 1716 CELL_VOLT_10_11 "CELL_10 Voltage";
CM_ SG_ 1716 CELL_VOLT_09_11 "CELL_09 Voltage";
CM_ SG_ 1700 CELL_VOLT_12_10 "CELL_12 Voltage";
CM_ SG_ 1700 CELL_VOLT_11_10 "CELL_11 Voltage";
CM_ SG_ 1700 CELL_VOLT_10_10 "CELL_10 Voltage";
CM_ SG_ 1700 CELL_VOLT_09_10 "CELL_09 Voltage";
CM_ SG_ 1684 CELL_VOLT_12_09 "CELL_12 Voltage";
CM_ SG_ 1684 CELL_VOLT_11_09 "CELL_11 Voltage";
CM_ SG_ 1684 CELL_VOLT_10_09 "CELL_10 Voltage";
CM_ SG_ 1684 CELL_VOLT_09_09 "CELL_09 Voltage";
CM_ SG_ 1668 CELL_VOLT_12_08 "CELL_12 Voltage";
CM_ SG_ 1668 CELL_VOLT_11_08 "CELL_11 Voltage";
CM_ SG_ 1668 CELL_VOLT_10_08 "CELL_10 Voltage";
CM_ SG_ 1668 CELL_VOLT_09_08 "CELL_09 Voltage";
CM_ SG_ 1652 CELL_VOLT_12_07 "CELL_12 Voltage";
CM_ SG_ 1652 CELL_VOLT_11_07 "CELL_11 Voltage";
CM_ SG_ 1652 CELL_VOLT_10_07 "CELL_10 Voltage";
CM_ SG_ 1652 CELL_VOLT_09_07 "CELL_09 Voltage";
CM_ SG_ 1636 CELL_VOLT_12_06 "CELL_12 Voltage";
CM_ SG_ 1636 CELL_VOLT_11_06 "CELL_11 Voltage";
CM_ SG_ 1636 CELL_VOLT_10_06 "CELL_10 Voltage";
CM_ SG_ 1636 CELL_VOLT_09_06 "CELL_09 Voltage";
CM_ SG_ 1620 CELL_VOLT_12_05 "CELL_12 Voltage";
CM_ SG_ 1620 CELL_VOLT_11_05 "CELL_11 Voltage";
CM_ SG_ 1620 CELL_VOLT_10_05 "CELL_10 Voltage";
CM_ SG_ 1620 CELL_VOLT_09_05 "CELL_09 Voltage";
CM_ SG_ 1604 CELL_VOLT_12_04 "CELL_12 Voltage";
CM_ SG_ 1604 CELL_VOLT_11_04 "CELL_11 Voltage";
CM_ SG_ 1604 CELL_VOLT_10_04 "CELL_10 Voltage";
CM_ SG_ 1604 CELL_VOLT_09_04 "CELL_09 Voltage";
CM_ SG_ 1588 CELL_VOLT_12_03 "CELL_12 Voltage";
CM_ SG_ 1588 CELL_VOLT_11_03 "CELL_11 Voltage";
CM_ SG_ 1588 CELL_VOLT_10_03 "CELL_10 Voltage";
CM_ SG_ 1588 CELL_VOLT_09_03 "CELL_09 Voltage";
CM_ SG_ 1572 CELL_VOLT_12_02 "CELL_12 Voltage";
CM_ SG_ 1572 CELL_VOLT_11_02 "CELL_11 Voltage";
CM_ SG_ 1572 CELL_VOLT_10_02 "CELL_10 Voltage";
CM_ SG_ 1572 CELL_VOLT_09_02 "CELL_09 Voltage";
CM_ SG_ 1556 CELL_VOLT_12_01 "CELL_12 Voltage";
CM_ SG_ 1556 CELL_VOLT_11_01 "CELL_11 Voltage";
CM_ SG_ 1556 CELL_VOLT_10_01 "CELL_10 Voltage";
CM_ SG_ 1556 CELL_VOLT_09_01 "CELL_09 Voltage";
CM_ SG_ 1731 CELL_VOLT_08_12 "CELL_08 Voltage";
CM_ SG_ 1731 CELL_VOLT_07_12 "CELL_07 Voltage";
CM_ SG_ 1731 CELL_VOLT_06_12 "CELL_06 Voltage";
CM_ SG_ 1731 CELL_VOLT_05_12 "CELL_05 Voltage";
CM_ SG_ 1715 CELL_VOLT_08_11 "CELL_08 Voltage";
CM_ SG_ 1715 CELL_VOLT_07_11 "CELL_07 Voltage";
CM_ SG_ 1715 CELL_VOLT_06_11 "CELL_06 Voltage";
CM_ SG_ 1715 CELL_VOLT_05_11 "CELL_05 Voltage";
CM_ SG_ 1699 CELL_VOLT_08_10 "CELL_08 Voltage";
CM_ SG_ 1699 CELL_VOLT_07_10 "CELL_07 Voltage";
CM_ SG_ 1699 CELL_VOLT_06_10 "CELL_06 Voltage";
CM_ SG_ 1699 CELL_VOLT_05_10 "CELL_05 Voltage";
CM_ SG_ 1683 CELL_VOLT_08_09 "CELL_08 Voltage";
CM_ SG_ 1683 CELL_VOLT_07_09 "CELL_07 Voltage";
CM_ SG_ 1683 CELL_VOLT_06_09 "CELL_06 Voltage";
CM_ SG_ 1683 CELL_VOLT_05_09 "CELL_05 Voltage";
CM_ SG_ 1667 CELL_VOLT_08_08 "CELL_08 Voltage";
CM_ SG_ 1667 CELL_VOLT_07_08 "CELL_07 Voltage";
CM_ SG_ 1667 CELL_VOLT_06_08 "CELL_06 Voltage";
CM_ SG_ 1667 CELL_VOLT_05_08 "CELL_05 Voltage";
CM_ SG_ 1651 CELL_VOLT_08_07 "CELL_08 Voltage";
CM_ SG_ 1651 CELL_VOLT_07_07 "CELL_07 Voltage";
CM_ SG_ 1651 CELL_VOLT_06_07 "CELL_06 Voltage";
CM_ SG_ 1651 CELL_VOLT_05_07 "CELL_05 Voltage";
CM_ SG_ 1635 CELL_VOLT_08_06 "CELL_08 Voltage";
CM_ SG_ 1635 CELL_VOLT_07_06 "CELL_07 Voltage";
CM_ SG_ 1635 CELL_VOLT_06_06 "CELL_06 Voltage";
CM_ SG_ 1635 CELL_VOLT_05_06 "CELL_05 Voltage";
CM_ SG_ 1619 CELL_VOLT_08_05 "CELL_08 Voltage";
CM_ SG_ 1619 CELL_VOLT_07_05 "CELL_07 Voltage";
CM_ SG_ 1619 CELL_VOLT_06_05 "CELL_06 Voltage";
CM_ SG_ 1619 CELL_VOLT_05_05 "CELL_05 Voltage";
CM_ SG_ 1603 CELL_VOLT_08_04 "CELL_08 Voltage";
CM_ SG_ 1603 CELL_VOLT_07_04 "CELL_07 Voltage";
CM_ SG_ 1603 CELL_VOLT_06_04 "CELL_06 Voltage";
CM_ SG_ 1603 CELL_VOLT_05_04 "CELL_05 Voltage";
CM_ SG_ 1587 CELL_VOLT_08_03 "CELL_08 Voltage";
CM_ SG_ 1587 CELL_VOLT_07_03 "CELL_07 Voltage";
CM_ SG_ 1587 CELL_VOLT_06_03 "CELL_06 Voltage";
CM_ SG_ 1587 CELL_VOLT_05_03 "CELL_05 Voltage";
CM_ SG_ 1571 CELL_VOLT_08_02 "CELL_08 Voltage";
CM_ SG_ 1571 CELL_VOLT_07_02 "CELL_07 Voltage";
CM_ SG_ 1571 CELL_VOLT_06_02 "CELL_06 Voltage";
CM_ SG_ 1571 CELL_VOLT_05_02 "CELL_05 Voltage";
CM_ SG_ 1555 CELL_VOLT_08_01 "CELL_08 Voltage";
CM_ SG_ 1555 CELL_VOLT_07_01 "CELL_07 Voltage";
CM_ SG_ 1555 CELL_VOLT_06_01 "CELL_06 Voltage";
CM_ SG_ 1555 CELL_VOLT_05_01 "CELL_05 Voltage";
CM_ SG_ 1730 CELL_VOLT_04_12 "CELL_04 Voltage";
CM_ SG_ 1730 CELL_VOLT_03_12 "CELL_03 Voltage";
CM_ SG_ 1730 CELL_VOLT_02_12 "CELL_02 Voltage";
CM_ SG_ 1730 CELL_VOLT_01_12 "CELL_01 Voltage";
CM_ SG_ 1714 CELL_VOLT_04_11 "CELL_04 Voltage";
CM_ SG_ 1714 CELL_VOLT_03_11 "CELL_03 Voltage";
CM_ SG_ 1714 CELL_VOLT_02_11 "CELL_02 Voltage";
CM_ SG_ 1714 CELL_VOLT_01_11 "CELL_01 Voltage";
CM_ SG_ 1698 CELL_VOLT_04_10 "CELL_04 Voltage";
CM_ SG_ 1698 CELL_VOLT_03_10 "CELL_03 Voltage";
CM_ SG_ 1698 CELL_VOLT_02_10 "CELL_02 Voltage";
CM_ SG_ 1698 CELL_VOLT_01_10 "CELL_01 Voltage";
CM_ SG_ 1682 CELL_VOLT_04_09 "CELL_04 Voltage";
CM_ SG_ 1682 CELL_VOLT_03_09 "CELL_03 Voltage";
CM_ SG_ 1682 CELL_VOLT_02_09 "CELL_02 Voltage";
CM_ SG_ 1682 CELL_VOLT_01_09 "CELL_01 Voltage";
CM_ SG_ 1666 CELL_VOLT_04_08 "CELL_04 Voltage";
CM_ SG_ 1666 CELL_VOLT_03_08 "CELL_03 Voltage";
CM_ SG_ 1666 CELL_VOLT_02_08 "CELL_02 Voltage";
CM_ SG_ 1666 CELL_VOLT_01_08 "CELL_01 Voltage";
CM_ SG_ 1650 CELL_VOLT_04_07 "CELL_04 Voltage";
CM_ SG_ 1650 CELL_VOLT_03_07 "CELL_03 Voltage";
CM_ SG_ 1650 CELL_VOLT_02_07 "CELL_02 Voltage";
CM_ SG_ 1650 CELL_VOLT_01_07 "CELL_01 Voltage";
CM_ SG_ 1634 CELL_VOLT_04_06 "CELL_04 Voltage";
CM_ SG_ 1634 CELL_VOLT_03_06 "CELL_03 Voltage";
CM_ SG_ 1634 CELL_VOLT_02_06 "CELL_02 Voltage";
CM_ SG_ 1634 CELL_VOLT_01_06 "CELL_01 Voltage";
CM_ SG_ 1618 CELL_VOLT_04_05 "CELL_04 Voltage";
CM_ SG_ 1618 CELL_VOLT_03_05 "CELL_03 Voltage";
CM_ SG_ 1618 CELL_VOLT_02_05 "CELL_02 Voltage";
CM_ SG_ 1618 CELL_VOLT_01_05 "CELL_01 Voltage";
CM_ SG_ 1602 CELL_VOLT_04_04 "CELL_04 Voltage";
CM_ SG_ 1602 CELL_VOLT_03_04 "CELL_03 Voltage";
CM_ SG_ 1602 CELL_VOLT_02_04 "CELL_02 Voltage";
CM_ SG_ 1602 CELL_VOLT_01_04 "CELL_01 Voltage";
CM_ SG_ 1586 CELL_VOLT_04_03 "CELL_04 Voltage";
CM_ SG_ 1586 CELL_VOLT_03_03 "CELL_03 Voltage";
CM_ SG_ 1586 CELL_VOLT_02_03 "CELL_02 Voltage";
CM_ SG_ 1586 CELL_VOLT_01_03 "CELL_01 Voltage";
CM_ SG_ 1570 CELL_VOLT_04_02 "CELL_04 Voltage";
CM_ SG_ 1570 CELL_VOLT_03_02 "CELL_03 Voltage";
CM_ SG_ 1570 CELL_VOLT_02_02 "CELL_02 Voltage";
CM_ SG_ 1570 CELL_VOLT_01_02 "CELL_01 Voltage";
CM_ SG_ 1554 CELL_VOLT_04_01 "CELL_04 Voltage";
CM_ SG_ 1554 CELL_VOLT_03_01 "CELL_03 Voltage";
CM_ SG_ 1554 CELL_VOLT_02_01 "CELL_02 Voltage";
CM_ SG_ 1554 CELL_VOLT_01_01 "CELL_01 Voltage";
CM_ SG_ 1729 MODULE_TEMP_06_12 "Module temperature06";
CM_ SG_ 1729 MODULE_TEMP_05_12 "Module temperature05";
CM_ SG_ 1729 MODULE_TEMP_04_12 "Module temperature04";
CM_ SG_ 1729 MODULE_TEMP_03_12 "Module temperature03";
CM_ SG_ 1729 MODULE_TEMP_02_12 "Module temperature02";
CM_ SG_ 1729 MODULE_TEMP_01_12 "Module temperature01";
CM_ SG_ 1729 NUM_TABLE_VALUE_12 "Stored Automatic numbering table";
CM_ SG_ 1729 BLC_DRV_STAT_12_12 "CELL_12 Balancer drive status";
CM_ SG_ 1729 BLC_DRV_STAT_11_12 "CELL_11 Balancer drive status";
CM_ SG_ 1729 BLC_DRV_STAT_10_12 "CELL_10 Balancer drive status";
CM_ SG_ 1729 BLC_DRV_STAT_09_12 "CELL_09 Balancer drive status";
CM_ SG_ 1729 BLC_DRV_STAT_08_12 "CELL_08 Balancer drive status";
CM_ SG_ 1729 BLC_DRV_STAT_07_12 "CELL_07 Balancer drive status";
CM_ SG_ 1729 BLC_DRV_STAT_06_12 "CELL_06 Balancer drive status";
CM_ SG_ 1729 BLC_DRV_STAT_05_12 "CELL_05 Balancer drive status";
CM_ SG_ 1729 BLC_DRV_STAT_04_12 "CELL_04 Balancer drive status";
CM_ SG_ 1729 BLC_DRV_STAT_03_12 "CELL_03 Balancer drive status";
CM_ SG_ 1729 BLC_DRV_STAT_02_12 "CELL_02 Balancer drive status";
CM_ SG_ 1729 BLC_DRV_STAT_01_12 "CELL_01 Balancer drive status";
BA_DEF_ SG_  "GenSigTimeout_CMU_00" INT 0 65535;
BA_DEF_ SG_  "GenSigTimeout_CMU_12" INT 0 65535;
BA_DEF_ SG_  "GenSigTimeout_CMU_11" INT 0 65535;
BA_DEF_ SG_  "GenSigTimeout_CMU_10" INT 0 65535;
BA_DEF_ SG_  "GenSigTimeout_CMU_09" INT 0 65535;
BA_DEF_ SG_  "GenSigTimeout_CMU_08" INT 0 65535;
BA_DEF_ SG_  "GenSigTimeout_CMU_07" INT 0 65535;
BA_DEF_ SG_  "GenSigTimeout_CMU_06" INT 0 65535;
BA_DEF_ SG_  "GenSigTimeout_CMU_05" INT 0 65535;
BA_DEF_ SG_  "GenSigTimeout_CMU_04" INT 0 65535;
BA_DEF_ SG_  "GenSigTimeout_CMU_03" INT 0 65535;
BA_DEF_ SG_  "GenSigTimeout_CMU_02" INT 0 65535;
BA_DEF_ SG_  "GenSigTimeout_CMU_01" INT 0 65535;
BA_DEF_ SG_  "GenSigTimeout_BMU" INT 0 65535;
BA_DEF_  "NWID" HEX 0 255;
BA_DEF_  "NBTMax" INT 0 255;
BA_DEF_  "NBTMin" INT 0 255;
BA_DEF_  "SamplePointMax" FLOAT 0 100;
BA_DEF_  "SamplePointMin" FLOAT 0 100;
BA_DEF_  "NWM-Basisadresse" HEX 0 536870911;
BA_DEF_  "NWM-Typ" ENUM  "zentral (MB-W210)","dezentral (MB-OSAN)","keines","VAG-OSEK","BMW-OSEK","PAG-OSEK","DBAG-OSEK";
BA_DEF_ BU_  "NWM-Knoten" ENUM  "nein","ja";
BA_DEF_ BU_  "NWM-Stationsadresse" HEX 0 63;
BA_DEF_ SG_  "FlexKomIsMotorola" ENUM  "nein","ja";
BA_DEF_ SG_  "FlexKomSigLaenge" INT 0 64;
BA_DEF_ SG_  "FlexKomSigStartPos" INT 0 63;
BA_DEF_ SG_  "FlexKomComment" STRING ;
BA_DEF_ SG_  "FlexKomSigName" STRING ;
BA_DEF_ SG_  "FlexKomSID" INT 0 65535;
BA_DEF_ SG_  "GenSigStartValue" HEX 0 4294967295;
BA_DEF_ SG_  "FlexKomSigStartValue" STRING ;
BA_DEF_ SG_  "GenSigCycleTime" INT 0 65535;
BA_DEF_ SG_  "GenSigSendType" ENUM  "cyclicX","spontanX","cyclicIfActiveX","spontanWithDelay","cyclicAndSpontanX","cyclicAndSpontanWithDelay","spontanWithRepitition","cyclicIfActiveAndSpontanWD","cyclicIfActiveFast","cyclicWithRepeatOnDemand","none";
BA_DEF_ BO_  "GenMsgNrOfRepetitions" INT 0 65535;
BA_DEF_ BO_  "GenMsgDelayTime" INT 0 65535;
BA_DEF_ BO_  "GenMsgCycleTime" INT 0 65535;
BA_DEF_ BO_  "GenMsgSendType" ENUM  "cyclicX","spontanX","cyclicIfActiveX","spontanWithDelay","cyclicAndSpontanX","cyclicAndSpontanWithDelay","spontanWithRepitition","cyclicIfActiveAndSpontanWD","cyclicIfActiveFast","cyclicWithRepeatOnDemand","none";
BA_DEF_  "Baudrate" INT 0 1000000;
BA_DEF_  "VersionWeek" INT 0 53;
BA_DEF_  "VersionYear" INT 0 99;
BA_DEF_ BO_  "DiagResponse" ENUM  "nein","ja";
BA_DEF_ BO_  "DiagRequest" ENUM  "nein","ja";
BA_DEF_ BO_  "DiagState" ENUM  "nein","ja";
BA_DEF_ BO_  "App-Botschaft" ENUM  "nein","ja";
BA_DEF_ BO_  "NWM-Botschaft" ENUM  "nein","ja";
BA_DEF_  "Manufacturer" STRING ;
BA_DEF_DEF_  "GenSigTimeout_CMU_00" 0;
BA_DEF_DEF_  "GenSigTimeout_CMU_12" 0;
BA_DEF_DEF_  "GenSigTimeout_CMU_11" 0;
BA_DEF_DEF_  "GenSigTimeout_CMU_10" 0;
BA_DEF_DEF_  "GenSigTimeout_CMU_09" 0;
BA_DEF_DEF_  "GenSigTimeout_CMU_08" 0;
BA_DEF_DEF_  "GenSigTimeout_CMU_07" 0;
BA_DEF_DEF_  "GenSigTimeout_CMU_06" 0;
BA_DEF_DEF_  "GenSigTimeout_CMU_05" 0;
BA_DEF_DEF_  "GenSigTimeout_CMU_04" 0;
BA_DEF_DEF_  "GenSigTimeout_CMU_03" 0;
BA_DEF_DEF_  "GenSigTimeout_CMU_02" 0;
BA_DEF_DEF_  "GenSigTimeout_CMU_01" 0;
BA_DEF_DEF_  "GenSigTimeout_BMU" 0;
BA_DEF_DEF_  "NWID" 0;
BA_DEF_DEF_  "NBTMax" 20;
BA_DEF_DEF_  "NBTMin" 10;
BA_DEF_DEF_  "SamplePointMax" 81.25;
BA_DEF_DEF_  "SamplePointMin" 75;
BA_DEF_DEF_  "NWM-Basisadresse" 0;
BA_DEF_DEF_  "NWM-Typ" "";
BA_DEF_DEF_  "NWM-Knoten" "";
BA_DEF_DEF_  "NWM-Stationsadresse" 0;
BA_DEF_DEF_  "FlexKomIsMotorola" "";
BA_DEF_DEF_  "FlexKomSigLaenge" 0;
BA_DEF_DEF_  "FlexKomSigStartPos" 0;
BA_DEF_DEF_  "FlexKomComment" "";
BA_DEF_DEF_  "FlexKomSigName" "";
BA_DEF_DEF_  "FlexKomSID" 0;
BA_DEF_DEF_  "GenSigStartValue" 0;
BA_DEF_DEF_  "FlexKomSigStartValue" "";
BA_DEF_DEF_  "GenSigCycleTime" 0;
BA_DEF_DEF_  "GenSigSendType" "";
BA_DEF_DEF_  "GenMsgNrOfRepetitions" 0;
BA_DEF_DEF_  "GenMsgDelayTime" 0;
BA_DEF_DEF_  "GenMsgCycleTime" 0;
BA_DEF_DEF_  "GenMsgSendType" "";
BA_DEF_DEF_  "Baudrate" 500000;
BA_DEF_DEF_  "VersionWeek" 22;
BA_DEF_DEF_  "VersionYear" 12;
BA_DEF_DEF_  "DiagResponse" "";
BA_DEF_DEF_  "DiagRequest" "";
BA_DEF_DEF_  "DiagState" "";
BA_DEF_DEF_  "App-Botschaft" "";
BA_DEF_DEF_  "NWM-Botschaft" "";
BA_DEF_DEF_  "Manufacturer" "MMC";
BA_ "NWM-Typ" 6;
BA_ "NWM-Basisadresse" 1088;
BA_ "NWID" 1;
BA_ "NWM-Knoten" BU_ TESTER 0;
BA_ "NWM-Knoten" BU_ TCU 1;
BA_ "NWM-Stationsadresse" BU_ TCU 63;
BA_ "NWM-Knoten" BU_ BMU2 0;
BA_ "NWM-Knoten" BU_ CSM 0;
BA_ "NWM-Knoten" BU_ CMU_TEST 0;
BA_ "NWM-Knoten" BU_ CMU_12 0;
BA_ "NWM-Knoten" BU_ CMU_11 0;
BA_ "NWM-Knoten" BU_ CMU_10 0;
BA_ "NWM-Knoten" BU_ CMU_09 0;
BA_ "NWM-Knoten" BU_ CMU_08 0;
BA_ "NWM-Knoten" BU_ CMU_07 0;
BA_ "NWM-Knoten" BU_ CMU_06 0;
BA_ "NWM-Knoten" BU_ CMU_05 0;
BA_ "NWM-Knoten" BU_ CMU_04 0;
BA_ "NWM-Knoten" BU_ CMU_03 0;
BA_ "NWM-Knoten" BU_ CMU_02 0;
BA_ "NWM-Knoten" BU_ CMU_01 0;
BA_ "NWM-Knoten" BU_ CMU_00 0;
BA_ "NWM-Knoten" BU_ BMU 0;
BA_ "GenMsgNrOfRepetitions" BO_ 1151 1;
BA_ "GenMsgDelayTime" BO_ 1151 5;
BA_ "GenMsgSendType" BO_ 1151 1;
BA_ "DiagResponse" BO_ 1151 0;
BA_ "DiagRequest" BO_ 1151 0;
BA_ "DiagState" BO_ 1151 0;
BA_ "App-Botschaft" BO_ 1151 0;
BA_ "NWM-Botschaft" BO_ 1151 1;
BA_ "GenMsgDelayTime" BO_ 1847 5;
BA_ "GenMsgSendType" BO_ 1847 1;
BA_ "DiagResponse" BO_ 1847 1;
BA_ "DiagRequest" BO_ 1847 0;
BA_ "DiagState" BO_ 1847 0;
BA_ "App-Botschaft" BO_ 1847 0;
BA_ "NWM-Botschaft" BO_ 1847 0;
BA_ "GenMsgDelayTime" BO_ 1846 5;
BA_ "GenMsgSendType" BO_ 1846 1;
BA_ "DiagResponse" BO_ 1846 0;
BA_ "DiagRequest" BO_ 1846 1;
BA_ "DiagState" BO_ 1846 0;
BA_ "App-Botschaft" BO_ 1846 0;
BA_ "NWM-Botschaft" BO_ 1846 0;
BA_ "NWM-Botschaft" BO_ 1770 0;
BA_ "App-Botschaft" BO_ 1770 0;
BA_ "DiagState" BO_ 1770 0;
BA_ "DiagRequest" BO_ 1770 0;
BA_ "DiagResponse" BO_ 1770 0;
BA_ "GenMsgSendType" BO_ 1770 0;
BA_ "GenMsgCycleTime" BO_ 1770 100;
BA_ "GenMsgDelayTime" BO_ 1770 20;
BA_ "NWM-Botschaft" BO_ 1771 0;
BA_ "App-Botschaft" BO_ 1771 0;
BA_ "DiagState" BO_ 1771 0;
BA_ "DiagRequest" BO_ 1771 0;
BA_ "DiagResponse" BO_ 1771 0;
BA_ "GenMsgSendType" BO_ 1771 0;
BA_ "GenMsgCycleTime" BO_ 1771 100;
BA_ "GenMsgDelayTime" BO_ 1771 20;
BA_ "NWM-Botschaft" BO_ 1763 0;
BA_ "App-Botschaft" BO_ 1763 0;
BA_ "DiagState" BO_ 1763 0;
BA_ "DiagRequest" BO_ 1763 0;
BA_ "DiagResponse" BO_ 1763 0;
BA_ "GenMsgSendType" BO_ 1763 0;
BA_ "GenMsgCycleTime" BO_ 1763 100;
BA_ "GenMsgDelayTime" BO_ 1763 20;
BA_ "NWM-Botschaft" BO_ 1769 0;
BA_ "App-Botschaft" BO_ 1769 0;
BA_ "DiagState" BO_ 1769 0;
BA_ "DiagRequest" BO_ 1769 0;
BA_ "DiagResponse" BO_ 1769 0;
BA_ "GenMsgSendType" BO_ 1769 0;
BA_ "GenMsgCycleTime" BO_ 1769 100;
BA_ "GenMsgDelayTime" BO_ 1769 20;
BA_ "NWM-Botschaft" BO_ 1762 0;
BA_ "App-Botschaft" BO_ 1762 0;
BA_ "DiagState" BO_ 1762 0;
BA_ "DiagRequest" BO_ 1762 0;
BA_ "DiagResponse" BO_ 1762 0;
BA_ "GenMsgSendType" BO_ 1762 0;
BA_ "GenMsgCycleTime" BO_ 1762 100;
BA_ "GenMsgDelayTime" BO_ 1762 20;
BA_ "NWM-Botschaft" BO_ 1768 0;
BA_ "App-Botschaft" BO_ 1768 0;
BA_ "DiagState" BO_ 1768 0;
BA_ "DiagRequest" BO_ 1768 0;
BA_ "DiagResponse" BO_ 1768 0;
BA_ "GenMsgSendType" BO_ 1768 0;
BA_ "GenMsgCycleTime" BO_ 1768 100;
BA_ "GenMsgDelayTime" BO_ 1768 20;
BA_ "NWM-Botschaft" BO_ 1765 0;
BA_ "App-Botschaft" BO_ 1765 0;
BA_ "DiagState" BO_ 1765 0;
BA_ "DiagRequest" BO_ 1765 0;
BA_ "DiagResponse" BO_ 1765 0;
BA_ "GenMsgSendType" BO_ 1765 0;
BA_ "GenMsgCycleTime" BO_ 1765 100;
BA_ "GenMsgDelayTime" BO_ 1765 20;
BA_ "NWM-Botschaft" BO_ 1761 0;
BA_ "App-Botschaft" BO_ 1761 0;
BA_ "DiagState" BO_ 1761 0;
BA_ "DiagRequest" BO_ 1761 0;
BA_ "DiagResponse" BO_ 1761 0;
BA_ "GenMsgSendType" BO_ 1761 0;
BA_ "GenMsgCycleTime" BO_ 1761 100;
BA_ "GenMsgDelayTime" BO_ 1761 20;
BA_ "NWM-Botschaft" BO_ 1767 0;
BA_ "App-Botschaft" BO_ 1767 0;
BA_ "DiagState" BO_ 1767 0;
BA_ "DiagRequest" BO_ 1767 0;
BA_ "DiagResponse" BO_ 1767 0;
BA_ "GenMsgSendType" BO_ 1767 0;
BA_ "GenMsgCycleTime" BO_ 1767 100;
BA_ "GenMsgDelayTime" BO_ 1767 20;
BA_ "NWM-Botschaft" BO_ 1764 0;
BA_ "App-Botschaft" BO_ 1764 0;
BA_ "DiagState" BO_ 1764 0;
BA_ "DiagRequest" BO_ 1764 0;
BA_ "DiagResponse" BO_ 1764 0;
BA_ "GenMsgSendType" BO_ 1764 0;
BA_ "GenMsgCycleTime" BO_ 1764 100;
BA_ "GenMsgDelayTime" BO_ 1764 20;
BA_ "NWM-Botschaft" BO_ 962 0;
BA_ "App-Botschaft" BO_ 962 0;
BA_ "DiagState" BO_ 962 0;
BA_ "DiagRequest" BO_ 962 0;
BA_ "DiagResponse" BO_ 962 0;
BA_ "GenMsgSendType" BO_ 962 0;
BA_ "GenMsgCycleTime" BO_ 962 10;
BA_ "GenMsgDelayTime" BO_ 962 20;
BA_ "NWM-Botschaft" BO_ 1733 0;
BA_ "App-Botschaft" BO_ 1733 0;
BA_ "DiagState" BO_ 1733 0;
BA_ "DiagRequest" BO_ 1733 0;
BA_ "DiagResponse" BO_ 1733 0;
BA_ "GenMsgSendType" BO_ 1733 0;
BA_ "GenMsgCycleTime" BO_ 1733 40;
BA_ "GenMsgDelayTime" BO_ 1733 20;
BA_ "NWM-Botschaft" BO_ 1717 0;
BA_ "App-Botschaft" BO_ 1717 0;
BA_ "DiagState" BO_ 1717 0;
BA_ "DiagRequest" BO_ 1717 0;
BA_ "DiagResponse" BO_ 1717 0;
BA_ "GenMsgSendType" BO_ 1717 0;
BA_ "GenMsgCycleTime" BO_ 1717 40;
BA_ "GenMsgDelayTime" BO_ 1717 20;
BA_ "NWM-Botschaft" BO_ 1701 0;
BA_ "App-Botschaft" BO_ 1701 0;
BA_ "DiagState" BO_ 1701 0;
BA_ "DiagRequest" BO_ 1701 0;
BA_ "DiagResponse" BO_ 1701 0;
BA_ "GenMsgSendType" BO_ 1701 0;
BA_ "GenMsgCycleTime" BO_ 1701 40;
BA_ "GenMsgDelayTime" BO_ 1701 20;
BA_ "NWM-Botschaft" BO_ 1685 0;
BA_ "App-Botschaft" BO_ 1685 0;
BA_ "DiagState" BO_ 1685 0;
BA_ "DiagRequest" BO_ 1685 0;
BA_ "DiagResponse" BO_ 1685 0;
BA_ "GenMsgSendType" BO_ 1685 0;
BA_ "GenMsgCycleTime" BO_ 1685 40;
BA_ "GenMsgDelayTime" BO_ 1685 20;
BA_ "NWM-Botschaft" BO_ 1669 0;
BA_ "App-Botschaft" BO_ 1669 0;
BA_ "DiagState" BO_ 1669 0;
BA_ "DiagRequest" BO_ 1669 0;
BA_ "DiagResponse" BO_ 1669 0;
BA_ "GenMsgSendType" BO_ 1669 0;
BA_ "GenMsgCycleTime" BO_ 1669 40;
BA_ "GenMsgDelayTime" BO_ 1669 20;
BA_ "NWM-Botschaft" BO_ 1653 0;
BA_ "App-Botschaft" BO_ 1653 0;
BA_ "DiagState" BO_ 1653 0;
BA_ "DiagRequest" BO_ 1653 0;
BA_ "DiagResponse" BO_ 1653 0;
BA_ "GenMsgSendType" BO_ 1653 0;
BA_ "GenMsgCycleTime" BO_ 1653 40;
BA_ "GenMsgDelayTime" BO_ 1653 20;
BA_ "NWM-Botschaft" BO_ 1637 0;
BA_ "App-Botschaft" BO_ 1637 0;
BA_ "DiagState" BO_ 1637 0;
BA_ "DiagRequest" BO_ 1637 0;
BA_ "DiagResponse" BO_ 1637 0;
BA_ "GenMsgSendType" BO_ 1637 0;
BA_ "GenMsgCycleTime" BO_ 1637 40;
BA_ "GenMsgDelayTime" BO_ 1637 20;
BA_ "NWM-Botschaft" BO_ 1621 0;
BA_ "App-Botschaft" BO_ 1621 0;
BA_ "DiagState" BO_ 1621 0;
BA_ "DiagRequest" BO_ 1621 0;
BA_ "DiagResponse" BO_ 1621 0;
BA_ "GenMsgSendType" BO_ 1621 0;
BA_ "GenMsgCycleTime" BO_ 1621 40;
BA_ "GenMsgDelayTime" BO_ 1621 20;
BA_ "NWM-Botschaft" BO_ 1605 0;
BA_ "App-Botschaft" BO_ 1605 0;
BA_ "DiagState" BO_ 1605 0;
BA_ "DiagRequest" BO_ 1605 0;
BA_ "DiagResponse" BO_ 1605 0;
BA_ "GenMsgSendType" BO_ 1605 0;
BA_ "GenMsgCycleTime" BO_ 1605 40;
BA_ "GenMsgDelayTime" BO_ 1605 20;
BA_ "NWM-Botschaft" BO_ 1589 0;
BA_ "App-Botschaft" BO_ 1589 0;
BA_ "DiagState" BO_ 1589 0;
BA_ "DiagRequest" BO_ 1589 0;
BA_ "DiagResponse" BO_ 1589 0;
BA_ "GenMsgSendType" BO_ 1589 0;
BA_ "GenMsgCycleTime" BO_ 1589 40;
BA_ "GenMsgDelayTime" BO_ 1589 20;
BA_ "NWM-Botschaft" BO_ 1573 0;
BA_ "App-Botschaft" BO_ 1573 0;
BA_ "DiagState" BO_ 1573 0;
BA_ "DiagRequest" BO_ 1573 0;
BA_ "DiagResponse" BO_ 1573 0;
BA_ "GenMsgSendType" BO_ 1573 0;
BA_ "GenMsgCycleTime" BO_ 1573 40;
BA_ "GenMsgDelayTime" BO_ 1573 20;
BA_ "NWM-Botschaft" BO_ 1557 0;
BA_ "App-Botschaft" BO_ 1557 0;
BA_ "DiagState" BO_ 1557 0;
BA_ "DiagRequest" BO_ 1557 0;
BA_ "DiagResponse" BO_ 1557 0;
BA_ "GenMsgSendType" BO_ 1557 0;
BA_ "GenMsgCycleTime" BO_ 1557 40;
BA_ "GenMsgDelayTime" BO_ 1557 20;
BA_ "NWM-Botschaft" BO_ 1732 0;
BA_ "App-Botschaft" BO_ 1732 0;
BA_ "DiagState" BO_ 1732 0;
BA_ "DiagRequest" BO_ 1732 0;
BA_ "DiagResponse" BO_ 1732 0;
BA_ "GenMsgSendType" BO_ 1732 0;
BA_ "GenMsgCycleTime" BO_ 1732 40;
BA_ "GenMsgDelayTime" BO_ 1732 20;
BA_ "NWM-Botschaft" BO_ 1716 0;
BA_ "App-Botschaft" BO_ 1716 0;
BA_ "DiagState" BO_ 1716 0;
BA_ "DiagRequest" BO_ 1716 0;
BA_ "DiagResponse" BO_ 1716 0;
BA_ "GenMsgSendType" BO_ 1716 0;
BA_ "GenMsgCycleTime" BO_ 1716 40;
BA_ "GenMsgDelayTime" BO_ 1716 20;
BA_ "NWM-Botschaft" BO_ 1700 0;
BA_ "App-Botschaft" BO_ 1700 0;
BA_ "DiagState" BO_ 1700 0;
BA_ "DiagRequest" BO_ 1700 0;
BA_ "DiagResponse" BO_ 1700 0;
BA_ "GenMsgSendType" BO_ 1700 0;
BA_ "GenMsgCycleTime" BO_ 1700 40;
BA_ "GenMsgDelayTime" BO_ 1700 20;
BA_ "NWM-Botschaft" BO_ 1684 0;
BA_ "App-Botschaft" BO_ 1684 0;
BA_ "DiagState" BO_ 1684 0;
BA_ "DiagRequest" BO_ 1684 0;
BA_ "DiagResponse" BO_ 1684 0;
BA_ "GenMsgSendType" BO_ 1684 0;
BA_ "GenMsgCycleTime" BO_ 1684 40;
BA_ "GenMsgDelayTime" BO_ 1684 20;
BA_ "NWM-Botschaft" BO_ 1668 0;
BA_ "App-Botschaft" BO_ 1668 0;
BA_ "DiagState" BO_ 1668 0;
BA_ "DiagRequest" BO_ 1668 0;
BA_ "DiagResponse" BO_ 1668 0;
BA_ "GenMsgSendType" BO_ 1668 0;
BA_ "GenMsgCycleTime" BO_ 1668 40;
BA_ "GenMsgDelayTime" BO_ 1668 20;
BA_ "NWM-Botschaft" BO_ 1652 0;
BA_ "App-Botschaft" BO_ 1652 0;
BA_ "DiagState" BO_ 1652 0;
BA_ "DiagRequest" BO_ 1652 0;
BA_ "DiagResponse" BO_ 1652 0;
BA_ "GenMsgSendType" BO_ 1652 0;
BA_ "GenMsgCycleTime" BO_ 1652 40;
BA_ "GenMsgDelayTime" BO_ 1652 20;
BA_ "NWM-Botschaft" BO_ 1636 0;
BA_ "App-Botschaft" BO_ 1636 0;
BA_ "DiagState" BO_ 1636 0;
BA_ "DiagRequest" BO_ 1636 0;
BA_ "DiagResponse" BO_ 1636 0;
BA_ "GenMsgSendType" BO_ 1636 0;
BA_ "GenMsgCycleTime" BO_ 1636 40;
BA_ "GenMsgDelayTime" BO_ 1636 20;
BA_ "NWM-Botschaft" BO_ 1620 0;
BA_ "App-Botschaft" BO_ 1620 0;
BA_ "DiagState" BO_ 1620 0;
BA_ "DiagRequest" BO_ 1620 0;
BA_ "DiagResponse" BO_ 1620 0;
BA_ "GenMsgSendType" BO_ 1620 0;
BA_ "GenMsgCycleTime" BO_ 1620 40;
BA_ "GenMsgDelayTime" BO_ 1620 20;
BA_ "NWM-Botschaft" BO_ 1604 0;
BA_ "App-Botschaft" BO_ 1604 0;
BA_ "DiagState" BO_ 1604 0;
BA_ "DiagRequest" BO_ 1604 0;
BA_ "DiagResponse" BO_ 1604 0;
BA_ "GenMsgSendType" BO_ 1604 0;
BA_ "GenMsgCycleTime" BO_ 1604 40;
BA_ "GenMsgDelayTime" BO_ 1604 20;
BA_ "NWM-Botschaft" BO_ 1588 0;
BA_ "App-Botschaft" BO_ 1588 0;
BA_ "DiagState" BO_ 1588 0;
BA_ "DiagRequest" BO_ 1588 0;
BA_ "DiagResponse" BO_ 1588 0;
BA_ "GenMsgSendType" BO_ 1588 0;
BA_ "GenMsgCycleTime" BO_ 1588 40;
BA_ "GenMsgDelayTime" BO_ 1588 20;
BA_ "NWM-Botschaft" BO_ 1572 0;
BA_ "App-Botschaft" BO_ 1572 0;
BA_ "DiagState" BO_ 1572 0;
BA_ "DiagRequest" BO_ 1572 0;
BA_ "DiagResponse" BO_ 1572 0;
BA_ "GenMsgSendType" BO_ 1572 0;
BA_ "GenMsgCycleTime" BO_ 1572 40;
BA_ "GenMsgDelayTime" BO_ 1572 20;
BA_ "NWM-Botschaft" BO_ 1556 0;
BA_ "App-Botschaft" BO_ 1556 0;
BA_ "DiagState" BO_ 1556 0;
BA_ "DiagRequest" BO_ 1556 0;
BA_ "DiagResponse" BO_ 1556 0;
BA_ "GenMsgSendType" BO_ 1556 0;
BA_ "GenMsgCycleTime" BO_ 1556 40;
BA_ "GenMsgDelayTime" BO_ 1556 20;
BA_ "NWM-Botschaft" BO_ 1731 0;
BA_ "App-Botschaft" BO_ 1731 0;
BA_ "DiagState" BO_ 1731 0;
BA_ "DiagRequest" BO_ 1731 0;
BA_ "DiagResponse" BO_ 1731 0;
BA_ "GenMsgSendType" BO_ 1731 0;
BA_ "GenMsgCycleTime" BO_ 1731 40;
BA_ "GenMsgDelayTime" BO_ 1731 20;
BA_ "NWM-Botschaft" BO_ 1715 0;
BA_ "App-Botschaft" BO_ 1715 0;
BA_ "DiagState" BO_ 1715 0;
BA_ "DiagRequest" BO_ 1715 0;
BA_ "DiagResponse" BO_ 1715 0;
BA_ "GenMsgSendType" BO_ 1715 0;
BA_ "GenMsgCycleTime" BO_ 1715 40;
BA_ "GenMsgDelayTime" BO_ 1715 20;
BA_ "NWM-Botschaft" BO_ 1699 0;
BA_ "App-Botschaft" BO_ 1699 0;
BA_ "DiagState" BO_ 1699 0;
BA_ "DiagRequest" BO_ 1699 0;
BA_ "DiagResponse" BO_ 1699 0;
BA_ "GenMsgSendType" BO_ 1699 0;
BA_ "GenMsgCycleTime" BO_ 1699 40;
BA_ "GenMsgDelayTime" BO_ 1699 20;
BA_ "NWM-Botschaft" BO_ 1683 0;
BA_ "App-Botschaft" BO_ 1683 0;
BA_ "DiagState" BO_ 1683 0;
BA_ "DiagRequest" BO_ 1683 0;
BA_ "DiagResponse" BO_ 1683 0;
BA_ "GenMsgSendType" BO_ 1683 0;
BA_ "GenMsgCycleTime" BO_ 1683 40;
BA_ "GenMsgDelayTime" BO_ 1683 20;
BA_ "NWM-Botschaft" BO_ 1667 0;
BA_ "App-Botschaft" BO_ 1667 0;
BA_ "DiagState" BO_ 1667 0;
BA_ "DiagRequest" BO_ 1667 0;
BA_ "DiagResponse" BO_ 1667 0;
BA_ "GenMsgSendType" BO_ 1667 0;
BA_ "GenMsgCycleTime" BO_ 1667 40;
BA_ "GenMsgDelayTime" BO_ 1667 20;
BA_ "NWM-Botschaft" BO_ 1651 0;
BA_ "App-Botschaft" BO_ 1651 0;
BA_ "DiagState" BO_ 1651 0;
BA_ "DiagRequest" BO_ 1651 0;
BA_ "DiagResponse" BO_ 1651 0;
BA_ "GenMsgSendType" BO_ 1651 0;
BA_ "GenMsgCycleTime" BO_ 1651 40;
BA_ "GenMsgDelayTime" BO_ 1651 20;
BA_ "NWM-Botschaft" BO_ 1635 0;
BA_ "App-Botschaft" BO_ 1635 0;
BA_ "DiagState" BO_ 1635 0;
BA_ "DiagRequest" BO_ 1635 0;
BA_ "DiagResponse" BO_ 1635 0;
BA_ "GenMsgSendType" BO_ 1635 0;
BA_ "GenMsgCycleTime" BO_ 1635 40;
BA_ "GenMsgDelayTime" BO_ 1635 20;
BA_ "NWM-Botschaft" BO_ 1619 0;
BA_ "App-Botschaft" BO_ 1619 0;
BA_ "DiagState" BO_ 1619 0;
BA_ "DiagRequest" BO_ 1619 0;
BA_ "DiagResponse" BO_ 1619 0;
BA_ "GenMsgSendType" BO_ 1619 0;
BA_ "GenMsgCycleTime" BO_ 1619 40;
BA_ "GenMsgDelayTime" BO_ 1619 20;
BA_ "NWM-Botschaft" BO_ 1603 0;
BA_ "App-Botschaft" BO_ 1603 0;
BA_ "DiagState" BO_ 1603 0;
BA_ "DiagRequest" BO_ 1603 0;
BA_ "DiagResponse" BO_ 1603 0;
BA_ "GenMsgSendType" BO_ 1603 0;
BA_ "GenMsgCycleTime" BO_ 1603 40;
BA_ "GenMsgDelayTime" BO_ 1603 20;
BA_ "NWM-Botschaft" BO_ 1587 0;
BA_ "App-Botschaft" BO_ 1587 0;
BA_ "DiagState" BO_ 1587 0;
BA_ "DiagRequest" BO_ 1587 0;
BA_ "DiagResponse" BO_ 1587 0;
BA_ "GenMsgSendType" BO_ 1587 0;
BA_ "GenMsgCycleTime" BO_ 1587 40;
BA_ "GenMsgDelayTime" BO_ 1587 20;
BA_ "NWM-Botschaft" BO_ 1571 0;
BA_ "App-Botschaft" BO_ 1571 0;
BA_ "DiagState" BO_ 1571 0;
BA_ "DiagRequest" BO_ 1571 0;
BA_ "DiagResponse" BO_ 1571 0;
BA_ "GenMsgSendType" BO_ 1571 0;
BA_ "GenMsgCycleTime" BO_ 1571 40;
BA_ "GenMsgDelayTime" BO_ 1571 20;
BA_ "NWM-Botschaft" BO_ 1555 0;
BA_ "App-Botschaft" BO_ 1555 0;
BA_ "DiagState" BO_ 1555 0;
BA_ "DiagRequest" BO_ 1555 0;
BA_ "DiagResponse" BO_ 1555 0;
BA_ "GenMsgSendType" BO_ 1555 0;
BA_ "GenMsgCycleTime" BO_ 1555 40;
BA_ "GenMsgDelayTime" BO_ 1555 20;
BA_ "NWM-Botschaft" BO_ 1730 0;
BA_ "App-Botschaft" BO_ 1730 0;
BA_ "DiagState" BO_ 1730 0;
BA_ "DiagRequest" BO_ 1730 0;
BA_ "DiagResponse" BO_ 1730 0;
BA_ "GenMsgSendType" BO_ 1730 0;
BA_ "GenMsgCycleTime" BO_ 1730 40;
BA_ "GenMsgDelayTime" BO_ 1730 20;
BA_ "NWM-Botschaft" BO_ 1714 0;
BA_ "App-Botschaft" BO_ 1714 0;
BA_ "DiagState" BO_ 1714 0;
BA_ "DiagRequest" BO_ 1714 0;
BA_ "DiagResponse" BO_ 1714 0;
BA_ "GenMsgSendType" BO_ 1714 0;
BA_ "GenMsgCycleTime" BO_ 1714 40;
BA_ "GenMsgDelayTime" BO_ 1714 20;
BA_ "NWM-Botschaft" BO_ 1698 0;
BA_ "App-Botschaft" BO_ 1698 0;
BA_ "DiagState" BO_ 1698 0;
BA_ "DiagRequest" BO_ 1698 0;
BA_ "DiagResponse" BO_ 1698 0;
BA_ "GenMsgSendType" BO_ 1698 0;
BA_ "GenMsgCycleTime" BO_ 1698 40;
BA_ "GenMsgDelayTime" BO_ 1698 20;
BA_ "NWM-Botschaft" BO_ 1682 0;
BA_ "App-Botschaft" BO_ 1682 0;
BA_ "DiagState" BO_ 1682 0;
BA_ "DiagRequest" BO_ 1682 0;
BA_ "DiagResponse" BO_ 1682 0;
BA_ "GenMsgSendType" BO_ 1682 0;
BA_ "GenMsgCycleTime" BO_ 1682 40;
BA_ "GenMsgDelayTime" BO_ 1682 20;
BA_ "NWM-Botschaft" BO_ 1666 0;
BA_ "App-Botschaft" BO_ 1666 0;
BA_ "DiagState" BO_ 1666 0;
BA_ "DiagRequest" BO_ 1666 0;
BA_ "DiagResponse" BO_ 1666 0;
BA_ "GenMsgSendType" BO_ 1666 0;
BA_ "GenMsgCycleTime" BO_ 1666 40;
BA_ "GenMsgDelayTime" BO_ 1666 20;
BA_ "NWM-Botschaft" BO_ 1650 0;
BA_ "App-Botschaft" BO_ 1650 0;
BA_ "DiagState" BO_ 1650 0;
BA_ "DiagRequest" BO_ 1650 0;
BA_ "DiagResponse" BO_ 1650 0;
BA_ "GenMsgSendType" BO_ 1650 0;
BA_ "GenMsgCycleTime" BO_ 1650 40;
BA_ "GenMsgDelayTime" BO_ 1650 20;
BA_ "NWM-Botschaft" BO_ 1634 0;
BA_ "App-Botschaft" BO_ 1634 0;
BA_ "DiagState" BO_ 1634 0;
BA_ "DiagRequest" BO_ 1634 0;
BA_ "DiagResponse" BO_ 1634 0;
BA_ "GenMsgSendType" BO_ 1634 0;
BA_ "GenMsgCycleTime" BO_ 1634 40;
BA_ "GenMsgDelayTime" BO_ 1634 20;
BA_ "NWM-Botschaft" BO_ 1618 0;
BA_ "App-Botschaft" BO_ 1618 0;
BA_ "DiagState" BO_ 1618 0;
BA_ "DiagRequest" BO_ 1618 0;
BA_ "DiagResponse" BO_ 1618 0;
BA_ "GenMsgSendType" BO_ 1618 0;
BA_ "GenMsgCycleTime" BO_ 1618 40;
BA_ "GenMsgDelayTime" BO_ 1618 20;
BA_ "NWM-Botschaft" BO_ 1602 0;
BA_ "App-Botschaft" BO_ 1602 0;
BA_ "DiagState" BO_ 1602 0;
BA_ "DiagRequest" BO_ 1602 0;
BA_ "DiagResponse" BO_ 1602 0;
BA_ "GenMsgSendType" BO_ 1602 0;
BA_ "GenMsgCycleTime" BO_ 1602 40;
BA_ "GenMsgDelayTime" BO_ 1602 20;
BA_ "NWM-Botschaft" BO_ 1586 0;
BA_ "App-Botschaft" BO_ 1586 0;
BA_ "DiagState" BO_ 1586 0;
BA_ "DiagRequest" BO_ 1586 0;
BA_ "DiagResponse" BO_ 1586 0;
BA_ "GenMsgSendType" BO_ 1586 0;
BA_ "GenMsgCycleTime" BO_ 1586 40;
BA_ "GenMsgDelayTime" BO_ 1586 20;
BA_ "NWM-Botschaft" BO_ 1570 0;
BA_ "App-Botschaft" BO_ 1570 0;
BA_ "DiagState" BO_ 1570 0;
BA_ "DiagRequest" BO_ 1570 0;
BA_ "DiagResponse" BO_ 1570 0;
BA_ "GenMsgSendType" BO_ 1570 0;
BA_ "GenMsgCycleTime" BO_ 1570 40;
BA_ "GenMsgDelayTime" BO_ 1570 20;
BA_ "NWM-Botschaft" BO_ 1554 0;
BA_ "App-Botschaft" BO_ 1554 0;
BA_ "DiagState" BO_ 1554 0;
BA_ "DiagRequest" BO_ 1554 0;
BA_ "DiagResponse" BO_ 1554 0;
BA_ "GenMsgSendType" BO_ 1554 0;
BA_ "GenMsgCycleTime" BO_ 1554 40;
BA_ "GenMsgDelayTime" BO_ 1554 20;
BA_ "NWM-Botschaft" BO_ 1729 0;
BA_ "App-Botschaft" BO_ 1729 0;
BA_ "DiagState" BO_ 1729 0;
BA_ "DiagRequest" BO_ 1729 0;
BA_ "DiagResponse" BO_ 1729 0;
BA_ "GenMsgSendType" BO_ 1729 0;
BA_ "GenMsgCycleTime" BO_ 1729 40;
BA_ "GenMsgDelayTime" BO_ 1729 20;
BA_ "FlexKomIsMotorola" SG_ 1151 NM_TCU 1;
BA_ "FlexKomSigLaenge" SG_ 1151 NM_TCU 64;
BA_ "FlexKomComment" SG_ 1151 NM_TCU "Network Management";
BA_ "FlexKomSigName" SG_ 1151 NM_TCU "NM_TCU";
BA_ "GenSigSendType" SG_ 1151 NM_TCU 1;
BA_ "FlexKomIsMotorola" SG_ 1847 D_RS_DAS_TCU 1;
BA_ "FlexKomSigLaenge" SG_ 1847 D_RS_DAS_TCU 64;
BA_ "FlexKomSigStartPos" SG_ 1847 D_RS_DAS_TCU 7;
BA_ "FlexKomComment" SG_ 1847 D_RS_DAS_TCU "Diagnostic response";
BA_ "FlexKomSigName" SG_ 1847 D_RS_DAS_TCU "D_RS_DAS_TCU";
BA_ "FlexKomSigStartValue" SG_ 1847 D_RS_DAS_TCU "0000000000000000h";
BA_ "GenSigSendType" SG_ 1847 D_RS_DAS_TCU 1;
BA_ "FlexKomIsMotorola" SG_ 1846 D_RQ_DAS_TCU 1;
BA_ "FlexKomSigLaenge" SG_ 1846 D_RQ_DAS_TCU 64;
BA_ "FlexKomSigStartPos" SG_ 1846 D_RQ_DAS_TCU 7;
BA_ "FlexKomComment" SG_ 1846 D_RQ_DAS_TCU "Diagnostic request";
BA_ "FlexKomSigName" SG_ 1846 D_RQ_DAS_TCU "D_RQ_DAS_TCU";
BA_ "FlexKomSigStartValue" SG_ 1846 D_RQ_DAS_TCU "0000000000000000h";
BA_ "GenSigSendType" SG_ 1846 D_RQ_DAS_TCU 1;
BA_ "FlexKomSID" SG_ 1846 D_RQ_DAS_TCU 1677;
BA_ "GenSigSendType" SG_ 1770 CSCNT_DEV_10 0;
BA_ "GenSigCycleTime" SG_ 1770 CSCNT_DEV_10 100;
BA_ "FlexKomSigStartValue" SG_ 1770 CSCNT_DEV_10 "0000h";
BA_ "FlexKomSID" SG_ 1770 CSCNT_DEV_10 1448;
BA_ "FlexKomSigName" SG_ 1770 CSCNT_DEV_10 "CSCNT_DEV_10";
BA_ "FlexKomComment" SG_ 1770 CSCNT_DEV_10 "CMU_10 Current Variation";
BA_ "FlexKomSigStartPos" SG_ 1770 CSCNT_DEV_10 39;
BA_ "FlexKomSigLaenge" SG_ 1770 CSCNT_DEV_10 16;
BA_ "FlexKomIsMotorola" SG_ 1770 CSCNT_DEV_10 1;
BA_ "FlexKomIsMotorola" SG_ 1770 CRRLTIN_YY_10 1;
BA_ "FlexKomSigLaenge" SG_ 1770 CRRLTIN_YY_10 8;
BA_ "FlexKomSigStartPos" SG_ 1770 CRRLTIN_YY_10 31;
BA_ "FlexKomComment" SG_ 1770 CRRLTIN_YY_10 "CELL_08 Correlation Coefficient";
BA_ "FlexKomSigName" SG_ 1770 CRRLTIN_YY_10 "CRRLTIN_08_10";
BA_ "FlexKomSID" SG_ 1770 CRRLTIN_YY_10 1439;
BA_ "GenSigStartValue" SG_ 1770 CRRLTIN_YY_10 100;
BA_ "FlexKomSigStartValue" SG_ 1770 CRRLTIN_YY_10 "64h";
BA_ "GenSigCycleTime" SG_ 1770 CRRLTIN_YY_10 100;
BA_ "GenSigSendType" SG_ 1770 CRRLTIN_YY_10 0;
BA_ "FlexKomIsMotorola" SG_ 1770 CELL_RSIST_YY_10 1;
BA_ "FlexKomSigLaenge" SG_ 1770 CELL_RSIST_YY_10 16;
BA_ "FlexKomSigStartPos" SG_ 1770 CELL_RSIST_YY_10 15;
BA_ "FlexKomComment" SG_ 1770 CELL_RSIST_YY_10 "CELL_08 Internal Resistance";
BA_ "FlexKomSigName" SG_ 1770 CELL_RSIST_YY_10 "CELL_RSIST_08_10";
BA_ "FlexKomSID" SG_ 1770 CELL_RSIST_YY_10 1359;
BA_ "FlexKomSigStartValue" SG_ 1770 CELL_RSIST_YY_10 "0000h";
BA_ "GenSigCycleTime" SG_ 1770 CELL_RSIST_YY_10 100;
BA_ "GenSigSendType" SG_ 1770 CELL_RSIST_YY_10 0;
BA_ "FlexKomIsMotorola" SG_ 1770 FRAME_NO_YY_10 1;
BA_ "FlexKomSigLaenge" SG_ 1770 FRAME_NO_YY_10 4;
BA_ "FlexKomSigStartPos" SG_ 1770 FRAME_NO_YY_10 7;
BA_ "FlexKomComment" SG_ 1770 FRAME_NO_YY_10 "Automatic numbering table";
BA_ "FlexKomSigName" SG_ 1770 FRAME_NO_YY_10 "NUM_TABLE";
BA_ "FlexKomSID" SG_ 1770 FRAME_NO_YY_10 1014;
BA_ "FlexKomSigStartValue" SG_ 1770 FRAME_NO_YY_10 "0Fh";
BA_ "GenSigCycleTime" SG_ 1770 FRAME_NO_YY_10 100;
BA_ "GenSigSendType" SG_ 1770 FRAME_NO_YY_10 0;
BA_ "GenSigSendType" SG_ 1771 CSCNT_DEV_11 0;
BA_ "GenSigCycleTime" SG_ 1771 CSCNT_DEV_11 100;
BA_ "FlexKomSigStartValue" SG_ 1771 CSCNT_DEV_11 "0000h";
BA_ "FlexKomSID" SG_ 1771 CSCNT_DEV_11 1449;
BA_ "FlexKomSigName" SG_ 1771 CSCNT_DEV_11 "CSCNT_DEV_11";
BA_ "FlexKomComment" SG_ 1771 CSCNT_DEV_11 "CMU_11 Current Variation";
BA_ "FlexKomSigStartPos" SG_ 1771 CSCNT_DEV_11 39;
BA_ "FlexKomSigLaenge" SG_ 1771 CSCNT_DEV_11 16;
BA_ "FlexKomIsMotorola" SG_ 1771 CSCNT_DEV_11 1;
BA_ "FlexKomIsMotorola" SG_ 1771 CRRLTIN_YY_11 1;
BA_ "FlexKomSigLaenge" SG_ 1771 CRRLTIN_YY_11 8;
BA_ "FlexKomSigStartPos" SG_ 1771 CRRLTIN_YY_11 31;
BA_ "FlexKomComment" SG_ 1771 CRRLTIN_YY_11 "CELL_08 Correlation Coefficient";
BA_ "FlexKomSigName" SG_ 1771 CRRLTIN_YY_11 "CRRLTIN_08_11";
BA_ "FlexKomSID" SG_ 1771 CRRLTIN_YY_11 1439;
BA_ "GenSigStartValue" SG_ 1771 CRRLTIN_YY_11 100;
BA_ "FlexKomSigStartValue" SG_ 1771 CRRLTIN_YY_11 "64h";
BA_ "GenSigCycleTime" SG_ 1771 CRRLTIN_YY_11 100;
BA_ "GenSigSendType" SG_ 1771 CRRLTIN_YY_11 0;
BA_ "FlexKomIsMotorola" SG_ 1771 CELL_RSIST_YY_11 1;
BA_ "FlexKomSigLaenge" SG_ 1771 CELL_RSIST_YY_11 16;
BA_ "FlexKomSigStartPos" SG_ 1771 CELL_RSIST_YY_11 15;
BA_ "FlexKomComment" SG_ 1771 CELL_RSIST_YY_11 "CELL_08 Internal Resistance";
BA_ "FlexKomSigName" SG_ 1771 CELL_RSIST_YY_11 "CELL_RSIST_08_11";
BA_ "FlexKomSID" SG_ 1771 CELL_RSIST_YY_11 1359;
BA_ "FlexKomSigStartValue" SG_ 1771 CELL_RSIST_YY_11 "0000h";
BA_ "GenSigCycleTime" SG_ 1771 CELL_RSIST_YY_11 100;
BA_ "GenSigSendType" SG_ 1771 CELL_RSIST_YY_11 0;
BA_ "FlexKomIsMotorola" SG_ 1771 FRAME_NO_YY_11 1;
BA_ "FlexKomSigLaenge" SG_ 1771 FRAME_NO_YY_11 4;
BA_ "FlexKomSigStartPos" SG_ 1771 FRAME_NO_YY_11 7;
BA_ "FlexKomComment" SG_ 1771 FRAME_NO_YY_11 "Automatic numbering table";
BA_ "FlexKomSigName" SG_ 1771 FRAME_NO_YY_11 "NUM_TABLE";
BA_ "FlexKomSID" SG_ 1771 FRAME_NO_YY_11 1014;
BA_ "FlexKomSigStartValue" SG_ 1771 FRAME_NO_YY_11 "0Fh";
BA_ "GenSigCycleTime" SG_ 1771 FRAME_NO_YY_11 100;
BA_ "GenSigSendType" SG_ 1771 FRAME_NO_YY_11 0;
BA_ "GenSigSendType" SG_ 1763 CSCNT_DEV_03 0;
BA_ "GenSigCycleTime" SG_ 1763 CSCNT_DEV_03 100;
BA_ "FlexKomSigStartValue" SG_ 1763 CSCNT_DEV_03 "0000h";
BA_ "FlexKomSID" SG_ 1763 CSCNT_DEV_03 1442;
BA_ "FlexKomSigName" SG_ 1763 CSCNT_DEV_03 "CSCNT_DEV_03";
BA_ "FlexKomComment" SG_ 1763 CSCNT_DEV_03 "CMU_03 Current Variation";
BA_ "FlexKomSigStartPos" SG_ 1763 CSCNT_DEV_03 39;
BA_ "FlexKomSigLaenge" SG_ 1763 CSCNT_DEV_03 16;
BA_ "FlexKomIsMotorola" SG_ 1763 CSCNT_DEV_03 1;
BA_ "FlexKomIsMotorola" SG_ 1763 CRRLTIN_YY_03 1;
BA_ "FlexKomSigLaenge" SG_ 1763 CRRLTIN_YY_03 8;
BA_ "FlexKomSigStartPos" SG_ 1763 CRRLTIN_YY_03 31;
BA_ "FlexKomComment" SG_ 1763 CRRLTIN_YY_03 "CELL_08 Correlation Coefficient";
BA_ "FlexKomSigName" SG_ 1763 CRRLTIN_YY_03 "CRRLTIN_08_03";
BA_ "FlexKomSID" SG_ 1763 CRRLTIN_YY_03 1439;
BA_ "GenSigStartValue" SG_ 1763 CRRLTIN_YY_03 100;
BA_ "FlexKomSigStartValue" SG_ 1763 CRRLTIN_YY_03 "64h";
BA_ "GenSigCycleTime" SG_ 1763 CRRLTIN_YY_03 100;
BA_ "GenSigSendType" SG_ 1763 CRRLTIN_YY_03 0;
BA_ "FlexKomIsMotorola" SG_ 1763 CELL_RSIST_YY_03 1;
BA_ "FlexKomSigLaenge" SG_ 1763 CELL_RSIST_YY_03 16;
BA_ "FlexKomSigStartPos" SG_ 1763 CELL_RSIST_YY_03 15;
BA_ "FlexKomComment" SG_ 1763 CELL_RSIST_YY_03 "CELL_08 Internal Resistance";
BA_ "FlexKomSigName" SG_ 1763 CELL_RSIST_YY_03 "CELL_RSIST_08_03";
BA_ "FlexKomSID" SG_ 1763 CELL_RSIST_YY_03 1359;
BA_ "FlexKomSigStartValue" SG_ 1763 CELL_RSIST_YY_03 "0000h";
BA_ "GenSigCycleTime" SG_ 1763 CELL_RSIST_YY_03 100;
BA_ "GenSigSendType" SG_ 1763 CELL_RSIST_YY_03 0;
BA_ "FlexKomIsMotorola" SG_ 1763 FRAME_NO_YY_03 1;
BA_ "FlexKomSigLaenge" SG_ 1763 FRAME_NO_YY_03 4;
BA_ "FlexKomSigStartPos" SG_ 1763 FRAME_NO_YY_03 7;
BA_ "FlexKomComment" SG_ 1763 FRAME_NO_YY_03 "Automatic numbering table";
BA_ "FlexKomSigName" SG_ 1763 FRAME_NO_YY_03 "NUM_TABLE";
BA_ "FlexKomSID" SG_ 1763 FRAME_NO_YY_03 1014;
BA_ "FlexKomSigStartValue" SG_ 1763 FRAME_NO_YY_03 "0Fh";
BA_ "GenSigCycleTime" SG_ 1763 FRAME_NO_YY_03 100;
BA_ "GenSigSendType" SG_ 1763 FRAME_NO_YY_03 0;
BA_ "GenSigSendType" SG_ 1769 CSCNT_DEV_09 0;
BA_ "GenSigCycleTime" SG_ 1769 CSCNT_DEV_09 100;
BA_ "FlexKomSigStartValue" SG_ 1769 CSCNT_DEV_09 "0000h";
BA_ "FlexKomSID" SG_ 1769 CSCNT_DEV_09 1447;
BA_ "FlexKomSigName" SG_ 1769 CSCNT_DEV_09 "CSCNT_DEV_09";
BA_ "FlexKomComment" SG_ 1769 CSCNT_DEV_09 "CMU_09 Current Variation";
BA_ "FlexKomSigStartPos" SG_ 1769 CSCNT_DEV_09 39;
BA_ "FlexKomSigLaenge" SG_ 1769 CSCNT_DEV_09 16;
BA_ "FlexKomIsMotorola" SG_ 1769 CSCNT_DEV_09 1;
BA_ "FlexKomIsMotorola" SG_ 1769 CRRLTIN_YY_09 1;
BA_ "FlexKomSigLaenge" SG_ 1769 CRRLTIN_YY_09 8;
BA_ "FlexKomSigStartPos" SG_ 1769 CRRLTIN_YY_09 31;
BA_ "FlexKomComment" SG_ 1769 CRRLTIN_YY_09 "CELL_08 Correlation Coefficient";
BA_ "FlexKomSigName" SG_ 1769 CRRLTIN_YY_09 "CRRLTIN_08_09";
BA_ "FlexKomSID" SG_ 1769 CRRLTIN_YY_09 1439;
BA_ "GenSigStartValue" SG_ 1769 CRRLTIN_YY_09 100;
BA_ "FlexKomSigStartValue" SG_ 1769 CRRLTIN_YY_09 "64h";
BA_ "GenSigCycleTime" SG_ 1769 CRRLTIN_YY_09 100;
BA_ "GenSigSendType" SG_ 1769 CRRLTIN_YY_09 0;
BA_ "FlexKomIsMotorola" SG_ 1769 CELL_RSIST_YY_09 1;
BA_ "FlexKomSigLaenge" SG_ 1769 CELL_RSIST_YY_09 16;
BA_ "FlexKomSigStartPos" SG_ 1769 CELL_RSIST_YY_09 15;
BA_ "FlexKomComment" SG_ 1769 CELL_RSIST_YY_09 "CELL_08 Internal Resistance";
BA_ "FlexKomSigName" SG_ 1769 CELL_RSIST_YY_09 "CELL_RSIST_08_09";
BA_ "FlexKomSID" SG_ 1769 CELL_RSIST_YY_09 1359;
BA_ "FlexKomSigStartValue" SG_ 1769 CELL_RSIST_YY_09 "0000h";
BA_ "GenSigCycleTime" SG_ 1769 CELL_RSIST_YY_09 100;
BA_ "GenSigSendType" SG_ 1769 CELL_RSIST_YY_09 0;
BA_ "FlexKomIsMotorola" SG_ 1769 FRAME_NO_YY_09 1;
BA_ "FlexKomSigLaenge" SG_ 1769 FRAME_NO_YY_09 4;
BA_ "FlexKomSigStartPos" SG_ 1769 FRAME_NO_YY_09 7;
BA_ "FlexKomComment" SG_ 1769 FRAME_NO_YY_09 "Automatic numbering table";
BA_ "FlexKomSigName" SG_ 1769 FRAME_NO_YY_09 "NUM_TABLE";
BA_ "FlexKomSID" SG_ 1769 FRAME_NO_YY_09 1014;
BA_ "FlexKomSigStartValue" SG_ 1769 FRAME_NO_YY_09 "0Fh";
BA_ "GenSigCycleTime" SG_ 1769 FRAME_NO_YY_09 100;
BA_ "GenSigSendType" SG_ 1769 FRAME_NO_YY_09 0;
BA_ "GenSigSendType" SG_ 1762 CSCNT_DEV_02 0;
BA_ "GenSigCycleTime" SG_ 1762 CSCNT_DEV_02 100;
BA_ "FlexKomSigStartValue" SG_ 1762 CSCNT_DEV_02 "0000h";
BA_ "FlexKomSID" SG_ 1762 CSCNT_DEV_02 1441;
BA_ "FlexKomSigName" SG_ 1762 CSCNT_DEV_02 "CSCNT_DEV_02";
BA_ "FlexKomComment" SG_ 1762 CSCNT_DEV_02 "CMU_02 Current Variation";
BA_ "FlexKomSigStartPos" SG_ 1762 CSCNT_DEV_02 39;
BA_ "FlexKomSigLaenge" SG_ 1762 CSCNT_DEV_02 16;
BA_ "FlexKomIsMotorola" SG_ 1762 CSCNT_DEV_02 1;
BA_ "FlexKomIsMotorola" SG_ 1762 CRRLTIN_YY_02 1;
BA_ "FlexKomSigLaenge" SG_ 1762 CRRLTIN_YY_02 8;
BA_ "FlexKomSigStartPos" SG_ 1762 CRRLTIN_YY_02 31;
BA_ "FlexKomComment" SG_ 1762 CRRLTIN_YY_02 "CELL_08 Correlation Coefficient";
BA_ "FlexKomSigName" SG_ 1762 CRRLTIN_YY_02 "CRRLTIN_08_02";
BA_ "FlexKomSID" SG_ 1762 CRRLTIN_YY_02 1439;
BA_ "GenSigStartValue" SG_ 1762 CRRLTIN_YY_02 100;
BA_ "FlexKomSigStartValue" SG_ 1762 CRRLTIN_YY_02 "64h";
BA_ "GenSigCycleTime" SG_ 1762 CRRLTIN_YY_02 100;
BA_ "GenSigSendType" SG_ 1762 CRRLTIN_YY_02 0;
BA_ "FlexKomIsMotorola" SG_ 1762 CELL_RSIST_YY_02 1;
BA_ "FlexKomSigLaenge" SG_ 1762 CELL_RSIST_YY_02 16;
BA_ "FlexKomSigStartPos" SG_ 1762 CELL_RSIST_YY_02 15;
BA_ "FlexKomComment" SG_ 1762 CELL_RSIST_YY_02 "CELL_08 Internal Resistance";
BA_ "FlexKomSigName" SG_ 1762 CELL_RSIST_YY_02 "CELL_RSIST_08_02";
BA_ "FlexKomSID" SG_ 1762 CELL_RSIST_YY_02 1359;
BA_ "FlexKomSigStartValue" SG_ 1762 CELL_RSIST_YY_02 "0000h";
BA_ "GenSigCycleTime" SG_ 1762 CELL_RSIST_YY_02 100;
BA_ "GenSigSendType" SG_ 1762 CELL_RSIST_YY_02 0;
BA_ "FlexKomIsMotorola" SG_ 1762 FRAME_NO_YY_02 1;
BA_ "FlexKomSigLaenge" SG_ 1762 FRAME_NO_YY_02 4;
BA_ "FlexKomSigStartPos" SG_ 1762 FRAME_NO_YY_02 7;
BA_ "FlexKomComment" SG_ 1762 FRAME_NO_YY_02 "Automatic numbering table";
BA_ "FlexKomSigName" SG_ 1762 FRAME_NO_YY_02 "NUM_TABLE";
BA_ "FlexKomSID" SG_ 1762 FRAME_NO_YY_02 1014;
BA_ "FlexKomSigStartValue" SG_ 1762 FRAME_NO_YY_02 "0Fh";
BA_ "GenSigCycleTime" SG_ 1762 FRAME_NO_YY_02 100;
BA_ "GenSigSendType" SG_ 1762 FRAME_NO_YY_02 0;
BA_ "GenSigSendType" SG_ 1768 CSCNT_DEV_08 0;
BA_ "GenSigCycleTime" SG_ 1768 CSCNT_DEV_08 100;
BA_ "FlexKomSigStartValue" SG_ 1768 CSCNT_DEV_08 "0000h";
BA_ "FlexKomSID" SG_ 1768 CSCNT_DEV_08 1446;
BA_ "FlexKomSigName" SG_ 1768 CSCNT_DEV_08 "CSCNT_DEV_08";
BA_ "FlexKomComment" SG_ 1768 CSCNT_DEV_08 "CMU_08 Current Variation";
BA_ "FlexKomSigStartPos" SG_ 1768 CSCNT_DEV_08 39;
BA_ "FlexKomSigLaenge" SG_ 1768 CSCNT_DEV_08 16;
BA_ "FlexKomIsMotorola" SG_ 1768 CSCNT_DEV_08 1;
BA_ "FlexKomIsMotorola" SG_ 1768 CRRLTIN_YY_08 1;
BA_ "FlexKomSigLaenge" SG_ 1768 CRRLTIN_YY_08 8;
BA_ "FlexKomSigStartPos" SG_ 1768 CRRLTIN_YY_08 31;
BA_ "FlexKomComment" SG_ 1768 CRRLTIN_YY_08 "CELL_08 Correlation Coefficient";
BA_ "FlexKomSigName" SG_ 1768 CRRLTIN_YY_08 "CRRLTIN_08_08";
BA_ "FlexKomSID" SG_ 1768 CRRLTIN_YY_08 1439;
BA_ "GenSigStartValue" SG_ 1768 CRRLTIN_YY_08 100;
BA_ "FlexKomSigStartValue" SG_ 1768 CRRLTIN_YY_08 "64h";
BA_ "GenSigCycleTime" SG_ 1768 CRRLTIN_YY_08 100;
BA_ "GenSigSendType" SG_ 1768 CRRLTIN_YY_08 0;
BA_ "FlexKomIsMotorola" SG_ 1768 CELL_RSIST_YY_08 1;
BA_ "FlexKomSigLaenge" SG_ 1768 CELL_RSIST_YY_08 16;
BA_ "FlexKomSigStartPos" SG_ 1768 CELL_RSIST_YY_08 15;
BA_ "FlexKomComment" SG_ 1768 CELL_RSIST_YY_08 "CELL_08 Internal Resistance";
BA_ "FlexKomSigName" SG_ 1768 CELL_RSIST_YY_08 "CELL_RSIST_08_08";
BA_ "FlexKomSID" SG_ 1768 CELL_RSIST_YY_08 1359;
BA_ "FlexKomSigStartValue" SG_ 1768 CELL_RSIST_YY_08 "0000h";
BA_ "GenSigCycleTime" SG_ 1768 CELL_RSIST_YY_08 100;
BA_ "GenSigSendType" SG_ 1768 CELL_RSIST_YY_08 0;
BA_ "FlexKomIsMotorola" SG_ 1768 FRAME_NO_YY_08 1;
BA_ "FlexKomSigLaenge" SG_ 1768 FRAME_NO_YY_08 4;
BA_ "FlexKomSigStartPos" SG_ 1768 FRAME_NO_YY_08 7;
BA_ "FlexKomComment" SG_ 1768 FRAME_NO_YY_08 "Automatic numbering table";
BA_ "FlexKomSigName" SG_ 1768 FRAME_NO_YY_08 "NUM_TABLE";
BA_ "FlexKomSID" SG_ 1768 FRAME_NO_YY_08 1014;
BA_ "FlexKomSigStartValue" SG_ 1768 FRAME_NO_YY_08 "0Fh";
BA_ "GenSigCycleTime" SG_ 1768 FRAME_NO_YY_08 100;
BA_ "GenSigSendType" SG_ 1768 FRAME_NO_YY_08 0;
BA_ "GenSigSendType" SG_ 1765 CSCNT_DEV_05 0;
BA_ "GenSigCycleTime" SG_ 1765 CSCNT_DEV_05 100;
BA_ "FlexKomSigStartValue" SG_ 1765 CSCNT_DEV_05 "0000h";
BA_ "FlexKomSID" SG_ 1765 CSCNT_DEV_05 1444;
BA_ "FlexKomSigName" SG_ 1765 CSCNT_DEV_05 "CSCNT_DEV_05";
BA_ "FlexKomComment" SG_ 1765 CSCNT_DEV_05 "CMU_05 Current Variation";
BA_ "FlexKomSigStartPos" SG_ 1765 CSCNT_DEV_05 39;
BA_ "FlexKomSigLaenge" SG_ 1765 CSCNT_DEV_05 16;
BA_ "FlexKomIsMotorola" SG_ 1765 CSCNT_DEV_05 1;
BA_ "FlexKomIsMotorola" SG_ 1765 CRRLTIN_YY_05 1;
BA_ "FlexKomSigLaenge" SG_ 1765 CRRLTIN_YY_05 8;
BA_ "FlexKomSigStartPos" SG_ 1765 CRRLTIN_YY_05 31;
BA_ "FlexKomComment" SG_ 1765 CRRLTIN_YY_05 "CELL_08 Correlation Coefficient";
BA_ "FlexKomSigName" SG_ 1765 CRRLTIN_YY_05 "CRRLTIN_08_05";
BA_ "FlexKomSID" SG_ 1765 CRRLTIN_YY_05 1439;
BA_ "GenSigStartValue" SG_ 1765 CRRLTIN_YY_05 100;
BA_ "FlexKomSigStartValue" SG_ 1765 CRRLTIN_YY_05 "64h";
BA_ "GenSigCycleTime" SG_ 1765 CRRLTIN_YY_05 100;
BA_ "GenSigSendType" SG_ 1765 CRRLTIN_YY_05 0;
BA_ "FlexKomIsMotorola" SG_ 1765 CELL_RSIST_YY_05 1;
BA_ "FlexKomSigLaenge" SG_ 1765 CELL_RSIST_YY_05 16;
BA_ "FlexKomSigStartPos" SG_ 1765 CELL_RSIST_YY_05 15;
BA_ "FlexKomComment" SG_ 1765 CELL_RSIST_YY_05 "CELL_08 Internal Resistance";
BA_ "FlexKomSigName" SG_ 1765 CELL_RSIST_YY_05 "CELL_RSIST_08_05";
BA_ "FlexKomSID" SG_ 1765 CELL_RSIST_YY_05 1359;
BA_ "FlexKomSigStartValue" SG_ 1765 CELL_RSIST_YY_05 "0000h";
BA_ "GenSigCycleTime" SG_ 1765 CELL_RSIST_YY_05 100;
BA_ "GenSigSendType" SG_ 1765 CELL_RSIST_YY_05 0;
BA_ "FlexKomIsMotorola" SG_ 1765 FRAME_NO_YY_05 1;
BA_ "FlexKomSigLaenge" SG_ 1765 FRAME_NO_YY_05 4;
BA_ "FlexKomSigStartPos" SG_ 1765 FRAME_NO_YY_05 7;
BA_ "FlexKomComment" SG_ 1765 FRAME_NO_YY_05 "Automatic numbering table";
BA_ "FlexKomSigName" SG_ 1765 FRAME_NO_YY_05 "NUM_TABLE";
BA_ "FlexKomSID" SG_ 1765 FRAME_NO_YY_05 1014;
BA_ "FlexKomSigStartValue" SG_ 1765 FRAME_NO_YY_05 "0Fh";
BA_ "GenSigCycleTime" SG_ 1765 FRAME_NO_YY_05 100;
BA_ "GenSigSendType" SG_ 1765 FRAME_NO_YY_05 0;
BA_ "GenSigSendType" SG_ 1761 CSCNT_DEV_01 0;
BA_ "GenSigCycleTime" SG_ 1761 CSCNT_DEV_01 100;
BA_ "FlexKomSigStartValue" SG_ 1761 CSCNT_DEV_01 "0000h";
BA_ "FlexKomSID" SG_ 1761 CSCNT_DEV_01 1440;
BA_ "FlexKomSigName" SG_ 1761 CSCNT_DEV_01 "CSCNT_DEV_01";
BA_ "FlexKomComment" SG_ 1761 CSCNT_DEV_01 "CMU_01 Current Variation";
BA_ "FlexKomSigStartPos" SG_ 1761 CSCNT_DEV_01 39;
BA_ "FlexKomSigLaenge" SG_ 1761 CSCNT_DEV_01 16;
BA_ "FlexKomIsMotorola" SG_ 1761 CSCNT_DEV_01 1;
BA_ "FlexKomIsMotorola" SG_ 1761 CRRLTIN_YY_01 1;
BA_ "FlexKomSigLaenge" SG_ 1761 CRRLTIN_YY_01 8;
BA_ "FlexKomSigStartPos" SG_ 1761 CRRLTIN_YY_01 31;
BA_ "FlexKomComment" SG_ 1761 CRRLTIN_YY_01 "CELL_08 Correlation Coefficient";
BA_ "FlexKomSigName" SG_ 1761 CRRLTIN_YY_01 "CRRLTIN_08_01";
BA_ "FlexKomSID" SG_ 1761 CRRLTIN_YY_01 1439;
BA_ "GenSigStartValue" SG_ 1761 CRRLTIN_YY_01 100;
BA_ "FlexKomSigStartValue" SG_ 1761 CRRLTIN_YY_01 "64h";
BA_ "GenSigCycleTime" SG_ 1761 CRRLTIN_YY_01 100;
BA_ "GenSigSendType" SG_ 1761 CRRLTIN_YY_01 0;
BA_ "FlexKomIsMotorola" SG_ 1761 CELL_RSIST_YY_01 1;
BA_ "FlexKomSigLaenge" SG_ 1761 CELL_RSIST_YY_01 16;
BA_ "FlexKomSigStartPos" SG_ 1761 CELL_RSIST_YY_01 15;
BA_ "FlexKomComment" SG_ 1761 CELL_RSIST_YY_01 "CELL_08 Internal Resistance";
BA_ "FlexKomSigName" SG_ 1761 CELL_RSIST_YY_01 "CELL_RSIST_08_01";
BA_ "FlexKomSID" SG_ 1761 CELL_RSIST_YY_01 1359;
BA_ "FlexKomSigStartValue" SG_ 1761 CELL_RSIST_YY_01 "0000h";
BA_ "GenSigCycleTime" SG_ 1761 CELL_RSIST_YY_01 100;
BA_ "GenSigSendType" SG_ 1761 CELL_RSIST_YY_01 0;
BA_ "FlexKomIsMotorola" SG_ 1761 FRAME_NO_YY_01 1;
BA_ "FlexKomSigLaenge" SG_ 1761 FRAME_NO_YY_01 4;
BA_ "FlexKomSigStartPos" SG_ 1761 FRAME_NO_YY_01 7;
BA_ "FlexKomComment" SG_ 1761 FRAME_NO_YY_01 "Automatic numbering table";
BA_ "FlexKomSigName" SG_ 1761 FRAME_NO_YY_01 "NUM_TABLE";
BA_ "FlexKomSID" SG_ 1761 FRAME_NO_YY_01 1014;
BA_ "FlexKomSigStartValue" SG_ 1761 FRAME_NO_YY_01 "0Fh";
BA_ "GenSigCycleTime" SG_ 1761 FRAME_NO_YY_01 100;
BA_ "GenSigSendType" SG_ 1761 FRAME_NO_YY_01 0;
BA_ "GenSigSendType" SG_ 1767 CSCNT_DEV_07 0;
BA_ "GenSigCycleTime" SG_ 1767 CSCNT_DEV_07 100;
BA_ "FlexKomSigStartValue" SG_ 1767 CSCNT_DEV_07 "0000h";
BA_ "FlexKomSID" SG_ 1767 CSCNT_DEV_07 1445;
BA_ "FlexKomSigName" SG_ 1767 CSCNT_DEV_07 "CSCNT_DEV_07";
BA_ "FlexKomComment" SG_ 1767 CSCNT_DEV_07 "CMU_07 Current Variation";
BA_ "FlexKomSigStartPos" SG_ 1767 CSCNT_DEV_07 39;
BA_ "FlexKomSigLaenge" SG_ 1767 CSCNT_DEV_07 16;
BA_ "FlexKomIsMotorola" SG_ 1767 CSCNT_DEV_07 1;
BA_ "FlexKomIsMotorola" SG_ 1767 CRRLTIN_YY_07 1;
BA_ "FlexKomSigLaenge" SG_ 1767 CRRLTIN_YY_07 8;
BA_ "FlexKomSigStartPos" SG_ 1767 CRRLTIN_YY_07 31;
BA_ "FlexKomComment" SG_ 1767 CRRLTIN_YY_07 "CELL_08 Correlation Coefficient";
BA_ "FlexKomSigName" SG_ 1767 CRRLTIN_YY_07 "CRRLTIN_08_07";
BA_ "FlexKomSID" SG_ 1767 CRRLTIN_YY_07 1439;
BA_ "GenSigStartValue" SG_ 1767 CRRLTIN_YY_07 100;
BA_ "FlexKomSigStartValue" SG_ 1767 CRRLTIN_YY_07 "64h";
BA_ "GenSigCycleTime" SG_ 1767 CRRLTIN_YY_07 100;
BA_ "GenSigSendType" SG_ 1767 CRRLTIN_YY_07 0;
BA_ "FlexKomIsMotorola" SG_ 1767 CELL_RSIST_YY_07 1;
BA_ "FlexKomSigLaenge" SG_ 1767 CELL_RSIST_YY_07 16;
BA_ "FlexKomSigStartPos" SG_ 1767 CELL_RSIST_YY_07 15;
BA_ "FlexKomComment" SG_ 1767 CELL_RSIST_YY_07 "CELL_08 Internal Resistance";
BA_ "FlexKomSigName" SG_ 1767 CELL_RSIST_YY_07 "CELL_RSIST_08_07";
BA_ "FlexKomSID" SG_ 1767 CELL_RSIST_YY_07 1359;
BA_ "FlexKomSigStartValue" SG_ 1767 CELL_RSIST_YY_07 "0000h";
BA_ "GenSigCycleTime" SG_ 1767 CELL_RSIST_YY_07 100;
BA_ "GenSigSendType" SG_ 1767 CELL_RSIST_YY_07 0;
BA_ "FlexKomIsMotorola" SG_ 1767 FRAME_NO_YY_07 1;
BA_ "FlexKomSigLaenge" SG_ 1767 FRAME_NO_YY_07 4;
BA_ "FlexKomSigStartPos" SG_ 1767 FRAME_NO_YY_07 7;
BA_ "FlexKomComment" SG_ 1767 FRAME_NO_YY_07 "Automatic numbering table";
BA_ "FlexKomSigName" SG_ 1767 FRAME_NO_YY_07 "NUM_TABLE";
BA_ "FlexKomSID" SG_ 1767 FRAME_NO_YY_07 1014;
BA_ "FlexKomSigStartValue" SG_ 1767 FRAME_NO_YY_07 "0Fh";
BA_ "GenSigCycleTime" SG_ 1767 FRAME_NO_YY_07 100;
BA_ "GenSigSendType" SG_ 1767 FRAME_NO_YY_07 0;
BA_ "GenSigSendType" SG_ 1764 CSCNT_DEV_04 0;
BA_ "GenSigCycleTime" SG_ 1764 CSCNT_DEV_04 100;
BA_ "FlexKomSigStartValue" SG_ 1764 CSCNT_DEV_04 "0000h";
BA_ "FlexKomSID" SG_ 1764 CSCNT_DEV_04 1443;
BA_ "FlexKomSigName" SG_ 1764 CSCNT_DEV_04 "CSCNT_DEV_04";
BA_ "FlexKomComment" SG_ 1764 CSCNT_DEV_04 "CMU_04 Current Variation";
BA_ "FlexKomSigStartPos" SG_ 1764 CSCNT_DEV_04 39;
BA_ "FlexKomSigLaenge" SG_ 1764 CSCNT_DEV_04 16;
BA_ "FlexKomIsMotorola" SG_ 1764 CSCNT_DEV_04 1;
BA_ "FlexKomIsMotorola" SG_ 1764 CRRLTIN_YY_04 1;
BA_ "FlexKomSigLaenge" SG_ 1764 CRRLTIN_YY_04 8;
BA_ "FlexKomSigStartPos" SG_ 1764 CRRLTIN_YY_04 31;
BA_ "FlexKomComment" SG_ 1764 CRRLTIN_YY_04 "CELL_08 Correlation Coefficient";
BA_ "FlexKomSigName" SG_ 1764 CRRLTIN_YY_04 "CRRLTIN_08_04";
BA_ "FlexKomSID" SG_ 1764 CRRLTIN_YY_04 1439;
BA_ "GenSigStartValue" SG_ 1764 CRRLTIN_YY_04 100;
BA_ "FlexKomSigStartValue" SG_ 1764 CRRLTIN_YY_04 "64h";
BA_ "GenSigCycleTime" SG_ 1764 CRRLTIN_YY_04 100;
BA_ "GenSigSendType" SG_ 1764 CRRLTIN_YY_04 0;
BA_ "FlexKomIsMotorola" SG_ 1764 CELL_RSIST_YY_04 1;
BA_ "FlexKomSigLaenge" SG_ 1764 CELL_RSIST_YY_04 16;
BA_ "FlexKomSigStartPos" SG_ 1764 CELL_RSIST_YY_04 15;
BA_ "FlexKomComment" SG_ 1764 CELL_RSIST_YY_04 "CELL_08 Internal Resistance";
BA_ "FlexKomSigName" SG_ 1764 CELL_RSIST_YY_04 "CELL_RSIST_08_04";
BA_ "FlexKomSID" SG_ 1764 CELL_RSIST_YY_04 1359;
BA_ "FlexKomSigStartValue" SG_ 1764 CELL_RSIST_YY_04 "0000h";
BA_ "GenSigCycleTime" SG_ 1764 CELL_RSIST_YY_04 100;
BA_ "GenSigSendType" SG_ 1764 CELL_RSIST_YY_04 0;
BA_ "FlexKomIsMotorola" SG_ 1764 FRAME_NO_YY_04 1;
BA_ "FlexKomSigLaenge" SG_ 1764 FRAME_NO_YY_04 4;
BA_ "FlexKomSigStartPos" SG_ 1764 FRAME_NO_YY_04 7;
BA_ "FlexKomComment" SG_ 1764 FRAME_NO_YY_04 "Automatic numbering table";
BA_ "FlexKomSigName" SG_ 1764 FRAME_NO_YY_04 "NUM_TABLE";
BA_ "FlexKomSID" SG_ 1764 FRAME_NO_YY_04 1014;
BA_ "FlexKomSigStartValue" SG_ 1764 FRAME_NO_YY_04 "0Fh";
BA_ "GenSigCycleTime" SG_ 1764 FRAME_NO_YY_04 100;
BA_ "GenSigSendType" SG_ 1764 FRAME_NO_YY_04 0;
BA_ "GenSigSendType" SG_ 962 CSM_FAIL 0;
BA_ "GenSigCycleTime" SG_ 962 CSM_FAIL 10;
BA_ "FlexKomSigStartValue" SG_ 962 CSM_FAIL "8000000000h";
BA_ "GenSigTimeout_BMU" SG_ 962 CSM_FAIL 55;
BA_ "FlexKomSID" SG_ 962 CSM_FAIL 1255;
BA_ "FlexKomSigStartPos" SG_ 962 CSM_FAIL 7;
BA_ "FlexKomSigLaenge" SG_ 962 CSM_FAIL 40;
BA_ "FlexKomSigName" SG_ 962 CSM_FAIL "CSM_CURRENT_DATA";
BA_ "FlexKomComment" SG_ 962 CSM_FAIL "Battery current data detected by current sensor";
BA_ "FlexKomIsMotorola" SG_ 962 CSM_FAIL 1;
BA_ "GenSigSendType" SG_ 962 CSM_BATT_CURRENT 0;
BA_ "GenSigCycleTime" SG_ 962 CSM_BATT_CURRENT 10;
BA_ "FlexKomSigStartValue" SG_ 962 CSM_BATT_CURRENT "8000000000h";
BA_ "GenSigStartValue" SG_ 962 CSM_BATT_CURRENT 2147483648;
BA_ "GenSigTimeout_BMU" SG_ 962 CSM_BATT_CURRENT 55;
BA_ "FlexKomSID" SG_ 962 CSM_BATT_CURRENT 1255;
BA_ "FlexKomSigStartPos" SG_ 962 CSM_BATT_CURRENT 7;
BA_ "FlexKomSigLaenge" SG_ 962 CSM_BATT_CURRENT 40;
BA_ "FlexKomSigName" SG_ 962 CSM_BATT_CURRENT "CSM_CURRENT_DATA";
BA_ "FlexKomComment" SG_ 962 CSM_BATT_CURRENT "Battery current data detected by current sensor";
BA_ "FlexKomIsMotorola" SG_ 962 CSM_BATT_CURRENT 1;
BA_ "GenSigSendType" SG_ 1733 BLC_DSTAT_HARN_12 0;
BA_ "GenSigCycleTime" SG_ 1733 BLC_DSTAT_HARN_12 40;
BA_ "FlexKomSigStartValue" SG_ 1733 BLC_DSTAT_HARN_12 "00h";
BA_ "GenSigTimeout_BMU" SG_ 1733 BLC_DSTAT_HARN_12 220;
BA_ "FlexKomSID" SG_ 1733 BLC_DSTAT_HARN_12 1267;
BA_ "FlexKomSigLaenge" SG_ 1733 BLC_DSTAT_HARN_12 1;
BA_ "FlexKomSigName" SG_ 1733 BLC_DSTAT_HARN_12 "BLC_DSTAT_HARN_12";
BA_ "FlexKomComment" SG_ 1733 BLC_DSTAT_HARN_12 "Balancer drive status to detect open circuit12";
BA_ "FlexKomIsMotorola" SG_ 1733 BLC_DSTAT_HARN_12 1;
BA_ "GenSigSendType" SG_ 1717 BLC_DSTAT_HARN_11 0;
BA_ "GenSigCycleTime" SG_ 1717 BLC_DSTAT_HARN_11 40;
BA_ "FlexKomSigStartValue" SG_ 1717 BLC_DSTAT_HARN_11 "00h";
BA_ "GenSigTimeout_BMU" SG_ 1717 BLC_DSTAT_HARN_11 220;
BA_ "FlexKomSID" SG_ 1717 BLC_DSTAT_HARN_11 1266;
BA_ "FlexKomSigLaenge" SG_ 1717 BLC_DSTAT_HARN_11 1;
BA_ "FlexKomSigName" SG_ 1717 BLC_DSTAT_HARN_11 "BLC_DSTAT_HARN_11";
BA_ "FlexKomComment" SG_ 1717 BLC_DSTAT_HARN_11 "Balancer drive status to detect open circuit11";
BA_ "FlexKomIsMotorola" SG_ 1717 BLC_DSTAT_HARN_11 1;
BA_ "GenSigSendType" SG_ 1701 BLC_DSTAT_HARN_10 0;
BA_ "GenSigCycleTime" SG_ 1701 BLC_DSTAT_HARN_10 40;
BA_ "FlexKomSigStartValue" SG_ 1701 BLC_DSTAT_HARN_10 "00h";
BA_ "GenSigTimeout_BMU" SG_ 1701 BLC_DSTAT_HARN_10 220;
BA_ "FlexKomSID" SG_ 1701 BLC_DSTAT_HARN_10 1265;
BA_ "FlexKomSigLaenge" SG_ 1701 BLC_DSTAT_HARN_10 1;
BA_ "FlexKomSigName" SG_ 1701 BLC_DSTAT_HARN_10 "BLC_DSTAT_HARN_10";
BA_ "FlexKomComment" SG_ 1701 BLC_DSTAT_HARN_10 "Balancer drive status to detect open circuit10";
BA_ "FlexKomIsMotorola" SG_ 1701 BLC_DSTAT_HARN_10 1;
BA_ "GenSigSendType" SG_ 1685 BLC_DSTAT_HARN_09 0;
BA_ "GenSigCycleTime" SG_ 1685 BLC_DSTAT_HARN_09 40;
BA_ "FlexKomSigStartValue" SG_ 1685 BLC_DSTAT_HARN_09 "00h";
BA_ "GenSigTimeout_BMU" SG_ 1685 BLC_DSTAT_HARN_09 220;
BA_ "FlexKomSID" SG_ 1685 BLC_DSTAT_HARN_09 1264;
BA_ "FlexKomSigLaenge" SG_ 1685 BLC_DSTAT_HARN_09 1;
BA_ "FlexKomSigName" SG_ 1685 BLC_DSTAT_HARN_09 "BLC_DSTAT_HARN_09";
BA_ "FlexKomComment" SG_ 1685 BLC_DSTAT_HARN_09 "Balancer drive status to detect open circuit09";
BA_ "FlexKomIsMotorola" SG_ 1685 BLC_DSTAT_HARN_09 1;
BA_ "GenSigSendType" SG_ 1669 BLC_DSTAT_HARN_08 0;
BA_ "GenSigCycleTime" SG_ 1669 BLC_DSTAT_HARN_08 40;
BA_ "FlexKomSigStartValue" SG_ 1669 BLC_DSTAT_HARN_08 "00h";
BA_ "GenSigTimeout_BMU" SG_ 1669 BLC_DSTAT_HARN_08 220;
BA_ "FlexKomSID" SG_ 1669 BLC_DSTAT_HARN_08 1263;
BA_ "FlexKomSigLaenge" SG_ 1669 BLC_DSTAT_HARN_08 1;
BA_ "FlexKomSigName" SG_ 1669 BLC_DSTAT_HARN_08 "BLC_DSTAT_HARN_08";
BA_ "FlexKomComment" SG_ 1669 BLC_DSTAT_HARN_08 "Balancer drive status to detect open circuit08";
BA_ "FlexKomIsMotorola" SG_ 1669 BLC_DSTAT_HARN_08 1;
BA_ "GenSigSendType" SG_ 1653 BLC_DSTAT_HARN_07 0;
BA_ "GenSigCycleTime" SG_ 1653 BLC_DSTAT_HARN_07 40;
BA_ "FlexKomSigStartValue" SG_ 1653 BLC_DSTAT_HARN_07 "00h";
BA_ "GenSigTimeout_BMU" SG_ 1653 BLC_DSTAT_HARN_07 220;
BA_ "FlexKomSID" SG_ 1653 BLC_DSTAT_HARN_07 1262;
BA_ "FlexKomSigLaenge" SG_ 1653 BLC_DSTAT_HARN_07 1;
BA_ "FlexKomSigName" SG_ 1653 BLC_DSTAT_HARN_07 "BLC_DSTAT_HARN_07";
BA_ "FlexKomComment" SG_ 1653 BLC_DSTAT_HARN_07 "Balancer drive status to detect open circuit07";
BA_ "FlexKomIsMotorola" SG_ 1653 BLC_DSTAT_HARN_07 1;
BA_ "GenSigSendType" SG_ 1637 BLC_DSTAT_HARN_06 0;
BA_ "GenSigCycleTime" SG_ 1637 BLC_DSTAT_HARN_06 40;
BA_ "FlexKomSigStartValue" SG_ 1637 BLC_DSTAT_HARN_06 "00h";
BA_ "GenSigTimeout_BMU" SG_ 1637 BLC_DSTAT_HARN_06 220;
BA_ "FlexKomSID" SG_ 1637 BLC_DSTAT_HARN_06 1261;
BA_ "FlexKomSigLaenge" SG_ 1637 BLC_DSTAT_HARN_06 1;
BA_ "FlexKomSigName" SG_ 1637 BLC_DSTAT_HARN_06 "BLC_DSTAT_HARN_06";
BA_ "FlexKomComment" SG_ 1637 BLC_DSTAT_HARN_06 "Balancer drive status to detect open circuit06";
BA_ "FlexKomIsMotorola" SG_ 1637 BLC_DSTAT_HARN_06 1;
BA_ "GenSigSendType" SG_ 1621 BLC_DSTAT_HARN_05 0;
BA_ "GenSigCycleTime" SG_ 1621 BLC_DSTAT_HARN_05 40;
BA_ "FlexKomSigStartValue" SG_ 1621 BLC_DSTAT_HARN_05 "00h";
BA_ "GenSigTimeout_BMU" SG_ 1621 BLC_DSTAT_HARN_05 220;
BA_ "FlexKomSID" SG_ 1621 BLC_DSTAT_HARN_05 1260;
BA_ "FlexKomSigLaenge" SG_ 1621 BLC_DSTAT_HARN_05 1;
BA_ "FlexKomSigName" SG_ 1621 BLC_DSTAT_HARN_05 "BLC_DSTAT_HARN_05";
BA_ "FlexKomComment" SG_ 1621 BLC_DSTAT_HARN_05 "Balancer drive status to detect open circuit05";
BA_ "FlexKomIsMotorola" SG_ 1621 BLC_DSTAT_HARN_05 1;
BA_ "GenSigSendType" SG_ 1605 BLC_DSTAT_HARN_04 0;
BA_ "GenSigCycleTime" SG_ 1605 BLC_DSTAT_HARN_04 40;
BA_ "FlexKomSigStartValue" SG_ 1605 BLC_DSTAT_HARN_04 "00h";
BA_ "GenSigTimeout_BMU" SG_ 1605 BLC_DSTAT_HARN_04 220;
BA_ "FlexKomSID" SG_ 1605 BLC_DSTAT_HARN_04 1259;
BA_ "FlexKomSigLaenge" SG_ 1605 BLC_DSTAT_HARN_04 1;
BA_ "FlexKomSigName" SG_ 1605 BLC_DSTAT_HARN_04 "BLC_DSTAT_HARN_04";
BA_ "FlexKomComment" SG_ 1605 BLC_DSTAT_HARN_04 "Balancer drive status to detect open circuit04";
BA_ "FlexKomIsMotorola" SG_ 1605 BLC_DSTAT_HARN_04 1;
BA_ "GenSigSendType" SG_ 1589 BLC_DSTAT_HARN_03 0;
BA_ "GenSigCycleTime" SG_ 1589 BLC_DSTAT_HARN_03 40;
BA_ "FlexKomSigStartValue" SG_ 1589 BLC_DSTAT_HARN_03 "00h";
BA_ "GenSigTimeout_BMU" SG_ 1589 BLC_DSTAT_HARN_03 220;
BA_ "FlexKomSID" SG_ 1589 BLC_DSTAT_HARN_03 1258;
BA_ "FlexKomSigLaenge" SG_ 1589 BLC_DSTAT_HARN_03 1;
BA_ "FlexKomSigName" SG_ 1589 BLC_DSTAT_HARN_03 "BLC_DSTAT_HARN_03";
BA_ "FlexKomComment" SG_ 1589 BLC_DSTAT_HARN_03 "Balancer drive status to detect open circuit03";
BA_ "FlexKomIsMotorola" SG_ 1589 BLC_DSTAT_HARN_03 1;
BA_ "GenSigSendType" SG_ 1573 BLC_DSTAT_HARN_02 0;
BA_ "GenSigCycleTime" SG_ 1573 BLC_DSTAT_HARN_02 40;
BA_ "FlexKomSigStartValue" SG_ 1573 BLC_DSTAT_HARN_02 "00h";
BA_ "GenSigTimeout_BMU" SG_ 1573 BLC_DSTAT_HARN_02 220;
BA_ "FlexKomSID" SG_ 1573 BLC_DSTAT_HARN_02 1257;
BA_ "FlexKomSigLaenge" SG_ 1573 BLC_DSTAT_HARN_02 1;
BA_ "FlexKomSigName" SG_ 1573 BLC_DSTAT_HARN_02 "BLC_DSTAT_HARN_02";
BA_ "FlexKomComment" SG_ 1573 BLC_DSTAT_HARN_02 "Balancer drive status to detect open circuit02";
BA_ "FlexKomIsMotorola" SG_ 1573 BLC_DSTAT_HARN_02 1;
BA_ "GenSigSendType" SG_ 1557 BLC_DSTAT_HARN_01 0;
BA_ "GenSigCycleTime" SG_ 1557 BLC_DSTAT_HARN_01 40;
BA_ "FlexKomSigStartValue" SG_ 1557 BLC_DSTAT_HARN_01 "00h";
BA_ "GenSigTimeout_BMU" SG_ 1557 BLC_DSTAT_HARN_01 220;
BA_ "FlexKomSID" SG_ 1557 BLC_DSTAT_HARN_01 1256;
BA_ "FlexKomSigLaenge" SG_ 1557 BLC_DSTAT_HARN_01 1;
BA_ "FlexKomSigName" SG_ 1557 BLC_DSTAT_HARN_01 "BLC_DSTAT_HARN_01";
BA_ "FlexKomComment" SG_ 1557 BLC_DSTAT_HARN_01 "Balancer drive status to detect open circuit01";
BA_ "FlexKomIsMotorola" SG_ 1557 BLC_DSTAT_HARN_01 1;
BA_ "GenSigSendType" SG_ 1732 CELL_VOLT_12_12 0;
BA_ "GenSigCycleTime" SG_ 1732 CELL_VOLT_12_12 40;
BA_ "FlexKomSigStartValue" SG_ 1732 CELL_VOLT_12_12 "0000h";
BA_ "GenSigTimeout_BMU" SG_ 1732 CELL_VOLT_12_12 220;
BA_ "FlexKomSID" SG_ 1732 CELL_VOLT_12_12 1254;
BA_ "FlexKomSigStartPos" SG_ 1732 CELL_VOLT_12_12 55;
BA_ "FlexKomSigLaenge" SG_ 1732 CELL_VOLT_12_12 16;
BA_ "FlexKomSigName" SG_ 1732 CELL_VOLT_12_12 "CELL_VOLT_12_12";
BA_ "FlexKomComment" SG_ 1732 CELL_VOLT_12_12 "CELL_12 Voltage";
BA_ "FlexKomIsMotorola" SG_ 1732 CELL_VOLT_12_12 1;
BA_ "GenSigSendType" SG_ 1732 CELL_VOLT_11_12 0;
BA_ "GenSigCycleTime" SG_ 1732 CELL_VOLT_11_12 40;
BA_ "FlexKomSigStartValue" SG_ 1732 CELL_VOLT_11_12 "0000h";
BA_ "GenSigTimeout_BMU" SG_ 1732 CELL_VOLT_11_12 220;
BA_ "FlexKomSID" SG_ 1732 CELL_VOLT_11_12 1242;
BA_ "FlexKomSigStartPos" SG_ 1732 CELL_VOLT_11_12 39;
BA_ "FlexKomSigLaenge" SG_ 1732 CELL_VOLT_11_12 16;
BA_ "FlexKomSigName" SG_ 1732 CELL_VOLT_11_12 "CELL_VOLT_11_12";
BA_ "FlexKomComment" SG_ 1732 CELL_VOLT_11_12 "CELL_11 Voltage";
BA_ "FlexKomIsMotorola" SG_ 1732 CELL_VOLT_11_12 1;
BA_ "GenSigSendType" SG_ 1732 CELL_VOLT_10_12 0;
BA_ "GenSigCycleTime" SG_ 1732 CELL_VOLT_10_12 40;
BA_ "FlexKomSigStartValue" SG_ 1732 CELL_VOLT_10_12 "0000h";
BA_ "GenSigTimeout_BMU" SG_ 1732 CELL_VOLT_10_12 220;
BA_ "FlexKomSID" SG_ 1732 CELL_VOLT_10_12 1230;
BA_ "FlexKomSigStartPos" SG_ 1732 CELL_VOLT_10_12 23;
BA_ "FlexKomSigLaenge" SG_ 1732 CELL_VOLT_10_12 16;
BA_ "FlexKomSigName" SG_ 1732 CELL_VOLT_10_12 "CELL_VOLT_10_12";
BA_ "FlexKomComment" SG_ 1732 CELL_VOLT_10_12 "CELL_10 Voltage";
BA_ "FlexKomIsMotorola" SG_ 1732 CELL_VOLT_10_12 1;
BA_ "GenSigSendType" SG_ 1732 CELL_VOLT_09_12 0;
BA_ "GenSigCycleTime" SG_ 1732 CELL_VOLT_09_12 40;
BA_ "FlexKomSigStartValue" SG_ 1732 CELL_VOLT_09_12 "0000h";
BA_ "GenSigTimeout_BMU" SG_ 1732 CELL_VOLT_09_12 220;
BA_ "FlexKomSID" SG_ 1732 CELL_VOLT_09_12 1218;
BA_ "FlexKomSigStartPos" SG_ 1732 CELL_VOLT_09_12 7;
BA_ "FlexKomSigLaenge" SG_ 1732 CELL_VOLT_09_12 16;
BA_ "FlexKomSigName" SG_ 1732 CELL_VOLT_09_12 "CELL_VOLT_09_12";
BA_ "FlexKomComment" SG_ 1732 CELL_VOLT_09_12 "CELL_09 Voltage";
BA_ "FlexKomIsMotorola" SG_ 1732 CELL_VOLT_09_12 1;
BA_ "GenSigSendType" SG_ 1716 CELL_VOLT_12_11 0;
BA_ "GenSigCycleTime" SG_ 1716 CELL_VOLT_12_11 40;
BA_ "FlexKomSigStartValue" SG_ 1716 CELL_VOLT_12_11 "0000h";
BA_ "GenSigTimeout_BMU" SG_ 1716 CELL_VOLT_12_11 220;
BA_ "FlexKomSID" SG_ 1716 CELL_VOLT_12_11 1253;
BA_ "FlexKomSigStartPos" SG_ 1716 CELL_VOLT_12_11 55;
BA_ "FlexKomSigLaenge" SG_ 1716 CELL_VOLT_12_11 16;
BA_ "FlexKomSigName" SG_ 1716 CELL_VOLT_12_11 "CELL_VOLT_12_11";
BA_ "FlexKomComment" SG_ 1716 CELL_VOLT_12_11 "CELL_12 Voltage";
BA_ "FlexKomIsMotorola" SG_ 1716 CELL_VOLT_12_11 1;
BA_ "GenSigSendType" SG_ 1716 CELL_VOLT_11_11 0;
BA_ "GenSigCycleTime" SG_ 1716 CELL_VOLT_11_11 40;
BA_ "FlexKomSigStartValue" SG_ 1716 CELL_VOLT_11_11 "0000h";
BA_ "GenSigTimeout_BMU" SG_ 1716 CELL_VOLT_11_11 220;
BA_ "FlexKomSID" SG_ 1716 CELL_VOLT_11_11 1241;
BA_ "FlexKomSigStartPos" SG_ 1716 CELL_VOLT_11_11 39;
BA_ "FlexKomSigLaenge" SG_ 1716 CELL_VOLT_11_11 16;
BA_ "FlexKomSigName" SG_ 1716 CELL_VOLT_11_11 "CELL_VOLT_11_11";
BA_ "FlexKomComment" SG_ 1716 CELL_VOLT_11_11 "CELL_11 Voltage";
BA_ "FlexKomIsMotorola" SG_ 1716 CELL_VOLT_11_11 1;
BA_ "GenSigSendType" SG_ 1716 CELL_VOLT_10_11 0;
BA_ "GenSigCycleTime" SG_ 1716 CELL_VOLT_10_11 40;
BA_ "FlexKomSigStartValue" SG_ 1716 CELL_VOLT_10_11 "0000h";
BA_ "GenSigTimeout_BMU" SG_ 1716 CELL_VOLT_10_11 220;
BA_ "FlexKomSID" SG_ 1716 CELL_VOLT_10_11 1229;
BA_ "FlexKomSigStartPos" SG_ 1716 CELL_VOLT_10_11 23;
BA_ "FlexKomSigLaenge" SG_ 1716 CELL_VOLT_10_11 16;
BA_ "FlexKomSigName" SG_ 1716 CELL_VOLT_10_11 "CELL_VOLT_10_11";
BA_ "FlexKomComment" SG_ 1716 CELL_VOLT_10_11 "CELL_10 Voltage";
BA_ "FlexKomIsMotorola" SG_ 1716 CELL_VOLT_10_11 1;
BA_ "GenSigSendType" SG_ 1716 CELL_VOLT_09_11 0;
BA_ "GenSigCycleTime" SG_ 1716 CELL_VOLT_09_11 40;
BA_ "FlexKomSigStartValue" SG_ 1716 CELL_VOLT_09_11 "0000h";
BA_ "GenSigTimeout_BMU" SG_ 1716 CELL_VOLT_09_11 220;
BA_ "FlexKomSID" SG_ 1716 CELL_VOLT_09_11 1217;
BA_ "FlexKomSigStartPos" SG_ 1716 CELL_VOLT_09_11 7;
BA_ "FlexKomSigLaenge" SG_ 1716 CELL_VOLT_09_11 16;
BA_ "FlexKomSigName" SG_ 1716 CELL_VOLT_09_11 "CELL_VOLT_09_11";
BA_ "FlexKomComment" SG_ 1716 CELL_VOLT_09_11 "CELL_09 Voltage";
BA_ "FlexKomIsMotorola" SG_ 1716 CELL_VOLT_09_11 1;
BA_ "GenSigSendType" SG_ 1700 CELL_VOLT_12_10 0;
BA_ "GenSigCycleTime" SG_ 1700 CELL_VOLT_12_10 40;
BA_ "FlexKomSigStartValue" SG_ 1700 CELL_VOLT_12_10 "0000h";
BA_ "GenSigTimeout_BMU" SG_ 1700 CELL_VOLT_12_10 220;
BA_ "FlexKomSID" SG_ 1700 CELL_VOLT_12_10 1252;
BA_ "FlexKomSigStartPos" SG_ 1700 CELL_VOLT_12_10 55;
BA_ "FlexKomSigLaenge" SG_ 1700 CELL_VOLT_12_10 16;
BA_ "FlexKomSigName" SG_ 1700 CELL_VOLT_12_10 "CELL_VOLT_12_10";
BA_ "FlexKomComment" SG_ 1700 CELL_VOLT_12_10 "CELL_12 Voltage";
BA_ "FlexKomIsMotorola" SG_ 1700 CELL_VOLT_12_10 1;
BA_ "GenSigSendType" SG_ 1700 CELL_VOLT_11_10 0;
BA_ "GenSigCycleTime" SG_ 1700 CELL_VOLT_11_10 40;
BA_ "FlexKomSigStartValue" SG_ 1700 CELL_VOLT_11_10 "0000h";
BA_ "GenSigTimeout_BMU" SG_ 1700 CELL_VOLT_11_10 220;
BA_ "FlexKomSID" SG_ 1700 CELL_VOLT_11_10 1240;
BA_ "FlexKomSigStartPos" SG_ 1700 CELL_VOLT_11_10 39;
BA_ "FlexKomSigLaenge" SG_ 1700 CELL_VOLT_11_10 16;
BA_ "FlexKomSigName" SG_ 1700 CELL_VOLT_11_10 "CELL_VOLT_11_10";
BA_ "FlexKomComment" SG_ 1700 CELL_VOLT_11_10 "CELL_11 Voltage";
BA_ "FlexKomIsMotorola" SG_ 1700 CELL_VOLT_11_10 1;
BA_ "GenSigSendType" SG_ 1700 CELL_VOLT_10_10 0;
BA_ "GenSigCycleTime" SG_ 1700 CELL_VOLT_10_10 40;
BA_ "FlexKomSigStartValue" SG_ 1700 CELL_VOLT_10_10 "0000h";
BA_ "GenSigTimeout_BMU" SG_ 1700 CELL_VOLT_10_10 220;
BA_ "FlexKomSID" SG_ 1700 CELL_VOLT_10_10 1228;
BA_ "FlexKomSigStartPos" SG_ 1700 CELL_VOLT_10_10 23;
BA_ "FlexKomSigLaenge" SG_ 1700 CELL_VOLT_10_10 16;
BA_ "FlexKomSigName" SG_ 1700 CELL_VOLT_10_10 "CELL_VOLT_10_10";
BA_ "FlexKomComment" SG_ 1700 CELL_VOLT_10_10 "CELL_10 Voltage";
BA_ "FlexKomIsMotorola" SG_ 1700 CELL_VOLT_10_10 1;
BA_ "GenSigSendType" SG_ 1700 CELL_VOLT_09_10 0;
BA_ "GenSigCycleTime" SG_ 1700 CELL_VOLT_09_10 40;
BA_ "FlexKomSigStartValue" SG_ 1700 CELL_VOLT_09_10 "0000h";
BA_ "GenSigTimeout_BMU" SG_ 1700 CELL_VOLT_09_10 220;
BA_ "FlexKomSID" SG_ 1700 CELL_VOLT_09_10 1216;
BA_ "FlexKomSigStartPos" SG_ 1700 CELL_VOLT_09_10 7;
BA_ "FlexKomSigLaenge" SG_ 1700 CELL_VOLT_09_10 16;
BA_ "FlexKomSigName" SG_ 1700 CELL_VOLT_09_10 "CELL_VOLT_09_10";
BA_ "FlexKomComment" SG_ 1700 CELL_VOLT_09_10 "CELL_09 Voltage";
BA_ "FlexKomIsMotorola" SG_ 1700 CELL_VOLT_09_10 1;
BA_ "GenSigSendType" SG_ 1684 CELL_VOLT_12_09 0;
BA_ "GenSigCycleTime" SG_ 1684 CELL_VOLT_12_09 40;
BA_ "FlexKomSigStartValue" SG_ 1684 CELL_VOLT_12_09 "0000h";
BA_ "GenSigTimeout_BMU" SG_ 1684 CELL_VOLT_12_09 220;
BA_ "FlexKomSID" SG_ 1684 CELL_VOLT_12_09 1251;
BA_ "FlexKomSigStartPos" SG_ 1684 CELL_VOLT_12_09 55;
BA_ "FlexKomSigLaenge" SG_ 1684 CELL_VOLT_12_09 16;
BA_ "FlexKomSigName" SG_ 1684 CELL_VOLT_12_09 "CELL_VOLT_12_09";
BA_ "FlexKomComment" SG_ 1684 CELL_VOLT_12_09 "CELL_12 Voltage";
BA_ "FlexKomIsMotorola" SG_ 1684 CELL_VOLT_12_09 1;
BA_ "GenSigSendType" SG_ 1684 CELL_VOLT_11_09 0;
BA_ "GenSigCycleTime" SG_ 1684 CELL_VOLT_11_09 40;
BA_ "FlexKomSigStartValue" SG_ 1684 CELL_VOLT_11_09 "0000h";
BA_ "GenSigTimeout_BMU" SG_ 1684 CELL_VOLT_11_09 220;
BA_ "FlexKomSID" SG_ 1684 CELL_VOLT_11_09 1239;
BA_ "FlexKomSigStartPos" SG_ 1684 CELL_VOLT_11_09 39;
BA_ "FlexKomSigLaenge" SG_ 1684 CELL_VOLT_11_09 16;
BA_ "FlexKomSigName" SG_ 1684 CELL_VOLT_11_09 "CELL_VOLT_11_09";
BA_ "FlexKomComment" SG_ 1684 CELL_VOLT_11_09 "CELL_11 Voltage";
BA_ "FlexKomIsMotorola" SG_ 1684 CELL_VOLT_11_09 1;
BA_ "GenSigSendType" SG_ 1684 CELL_VOLT_10_09 0;
BA_ "GenSigCycleTime" SG_ 1684 CELL_VOLT_10_09 40;
BA_ "FlexKomSigStartValue" SG_ 1684 CELL_VOLT_10_09 "0000h";
BA_ "GenSigTimeout_BMU" SG_ 1684 CELL_VOLT_10_09 220;
BA_ "FlexKomSID" SG_ 1684 CELL_VOLT_10_09 1227;
BA_ "FlexKomSigStartPos" SG_ 1684 CELL_VOLT_10_09 23;
BA_ "FlexKomSigLaenge" SG_ 1684 CELL_VOLT_10_09 16;
BA_ "FlexKomSigName" SG_ 1684 CELL_VOLT_10_09 "CELL_VOLT_10_09";
BA_ "FlexKomComment" SG_ 1684 CELL_VOLT_10_09 "CELL_10 Voltage";
BA_ "FlexKomIsMotorola" SG_ 1684 CELL_VOLT_10_09 1;
BA_ "GenSigSendType" SG_ 1684 CELL_VOLT_09_09 0;
BA_ "GenSigCycleTime" SG_ 1684 CELL_VOLT_09_09 40;
BA_ "FlexKomSigStartValue" SG_ 1684 CELL_VOLT_09_09 "0000h";
BA_ "GenSigTimeout_BMU" SG_ 1684 CELL_VOLT_09_09 220;
BA_ "FlexKomSID" SG_ 1684 CELL_VOLT_09_09 1215;
BA_ "FlexKomSigStartPos" SG_ 1684 CELL_VOLT_09_09 7;
BA_ "FlexKomSigLaenge" SG_ 1684 CELL_VOLT_09_09 16;
BA_ "FlexKomSigName" SG_ 1684 CELL_VOLT_09_09 "CELL_VOLT_09_09";
BA_ "FlexKomComment" SG_ 1684 CELL_VOLT_09_09 "CELL_09 Voltage";
BA_ "FlexKomIsMotorola" SG_ 1684 CELL_VOLT_09_09 1;
BA_ "GenSigSendType" SG_ 1668 CELL_VOLT_12_08 0;
BA_ "GenSigCycleTime" SG_ 1668 CELL_VOLT_12_08 40;
BA_ "FlexKomSigStartValue" SG_ 1668 CELL_VOLT_12_08 "0000h";
BA_ "GenSigTimeout_BMU" SG_ 1668 CELL_VOLT_12_08 220;
BA_ "FlexKomSID" SG_ 1668 CELL_VOLT_12_08 1250;
BA_ "FlexKomSigStartPos" SG_ 1668 CELL_VOLT_12_08 55;
BA_ "FlexKomSigLaenge" SG_ 1668 CELL_VOLT_12_08 16;
BA_ "FlexKomSigName" SG_ 1668 CELL_VOLT_12_08 "CELL_VOLT_12_08";
BA_ "FlexKomComment" SG_ 1668 CELL_VOLT_12_08 "CELL_12 Voltage";
BA_ "FlexKomIsMotorola" SG_ 1668 CELL_VOLT_12_08 1;
BA_ "GenSigSendType" SG_ 1668 CELL_VOLT_11_08 0;
BA_ "GenSigCycleTime" SG_ 1668 CELL_VOLT_11_08 40;
BA_ "FlexKomSigStartValue" SG_ 1668 CELL_VOLT_11_08 "0000h";
BA_ "GenSigTimeout_BMU" SG_ 1668 CELL_VOLT_11_08 220;
BA_ "FlexKomSID" SG_ 1668 CELL_VOLT_11_08 1238;
BA_ "FlexKomSigStartPos" SG_ 1668 CELL_VOLT_11_08 39;
BA_ "FlexKomSigLaenge" SG_ 1668 CELL_VOLT_11_08 16;
BA_ "FlexKomSigName" SG_ 1668 CELL_VOLT_11_08 "CELL_VOLT_11_08";
BA_ "FlexKomComment" SG_ 1668 CELL_VOLT_11_08 "CELL_11 Voltage";
BA_ "FlexKomIsMotorola" SG_ 1668 CELL_VOLT_11_08 1;
BA_ "GenSigSendType" SG_ 1668 CELL_VOLT_10_08 0;
BA_ "GenSigCycleTime" SG_ 1668 CELL_VOLT_10_08 40;
BA_ "FlexKomSigStartValue" SG_ 1668 CELL_VOLT_10_08 "0000h";
BA_ "GenSigTimeout_BMU" SG_ 1668 CELL_VOLT_10_08 220;
BA_ "FlexKomSID" SG_ 1668 CELL_VOLT_10_08 1226;
BA_ "FlexKomSigStartPos" SG_ 1668 CELL_VOLT_10_08 23;
BA_ "FlexKomSigLaenge" SG_ 1668 CELL_VOLT_10_08 16;
BA_ "FlexKomSigName" SG_ 1668 CELL_VOLT_10_08 "CELL_VOLT_10_08";
BA_ "FlexKomComment" SG_ 1668 CELL_VOLT_10_08 "CELL_10 Voltage";
BA_ "FlexKomIsMotorola" SG_ 1668 CELL_VOLT_10_08 1;
BA_ "GenSigSendType" SG_ 1668 CELL_VOLT_09_08 0;
BA_ "GenSigCycleTime" SG_ 1668 CELL_VOLT_09_08 40;
BA_ "FlexKomSigStartValue" SG_ 1668 CELL_VOLT_09_08 "0000h";
BA_ "GenSigTimeout_BMU" SG_ 1668 CELL_VOLT_09_08 220;
BA_ "FlexKomSID" SG_ 1668 CELL_VOLT_09_08 1214;
BA_ "FlexKomSigStartPos" SG_ 1668 CELL_VOLT_09_08 7;
BA_ "FlexKomSigLaenge" SG_ 1668 CELL_VOLT_09_08 16;
BA_ "FlexKomSigName" SG_ 1668 CELL_VOLT_09_08 "CELL_VOLT_09_08";
BA_ "FlexKomComment" SG_ 1668 CELL_VOLT_09_08 "CELL_09 Voltage";
BA_ "FlexKomIsMotorola" SG_ 1668 CELL_VOLT_09_08 1;
BA_ "GenSigSendType" SG_ 1652 CELL_VOLT_12_07 0;
BA_ "GenSigCycleTime" SG_ 1652 CELL_VOLT_12_07 40;
BA_ "FlexKomSigStartValue" SG_ 1652 CELL_VOLT_12_07 "0000h";
BA_ "GenSigTimeout_BMU" SG_ 1652 CELL_VOLT_12_07 220;
BA_ "FlexKomSID" SG_ 1652 CELL_VOLT_12_07 1249;
BA_ "FlexKomSigStartPos" SG_ 1652 CELL_VOLT_12_07 55;
BA_ "FlexKomSigLaenge" SG_ 1652 CELL_VOLT_12_07 16;
BA_ "FlexKomSigName" SG_ 1652 CELL_VOLT_12_07 "CELL_VOLT_12_07";
BA_ "FlexKomComment" SG_ 1652 CELL_VOLT_12_07 "CELL_12 Voltage";
BA_ "FlexKomIsMotorola" SG_ 1652 CELL_VOLT_12_07 1;
BA_ "GenSigSendType" SG_ 1652 CELL_VOLT_11_07 0;
BA_ "GenSigCycleTime" SG_ 1652 CELL_VOLT_11_07 40;
BA_ "FlexKomSigStartValue" SG_ 1652 CELL_VOLT_11_07 "0000h";
BA_ "GenSigTimeout_BMU" SG_ 1652 CELL_VOLT_11_07 220;
BA_ "FlexKomSID" SG_ 1652 CELL_VOLT_11_07 1237;
BA_ "FlexKomSigStartPos" SG_ 1652 CELL_VOLT_11_07 39;
BA_ "FlexKomSigLaenge" SG_ 1652 CELL_VOLT_11_07 16;
BA_ "FlexKomSigName" SG_ 1652 CELL_VOLT_11_07 "CELL_VOLT_11_07";
BA_ "FlexKomComment" SG_ 1652 CELL_VOLT_11_07 "CELL_11 Voltage";
BA_ "FlexKomIsMotorola" SG_ 1652 CELL_VOLT_11_07 1;
BA_ "GenSigSendType" SG_ 1652 CELL_VOLT_10_07 0;
BA_ "GenSigCycleTime" SG_ 1652 CELL_VOLT_10_07 40;
BA_ "FlexKomSigStartValue" SG_ 1652 CELL_VOLT_10_07 "0000h";
BA_ "GenSigTimeout_BMU" SG_ 1652 CELL_VOLT_10_07 220;
BA_ "FlexKomSID" SG_ 1652 CELL_VOLT_10_07 1225;
BA_ "FlexKomSigStartPos" SG_ 1652 CELL_VOLT_10_07 23;
BA_ "FlexKomSigLaenge" SG_ 1652 CELL_VOLT_10_07 16;
BA_ "FlexKomSigName" SG_ 1652 CELL_VOLT_10_07 "CELL_VOLT_10_07";
BA_ "FlexKomComment" SG_ 1652 CELL_VOLT_10_07 "CELL_10 Voltage";
BA_ "FlexKomIsMotorola" SG_ 1652 CELL_VOLT_10_07 1;
BA_ "GenSigSendType" SG_ 1652 CELL_VOLT_09_07 0;
BA_ "GenSigCycleTime" SG_ 1652 CELL_VOLT_09_07 40;
BA_ "FlexKomSigStartValue" SG_ 1652 CELL_VOLT_09_07 "0000h";
BA_ "GenSigTimeout_BMU" SG_ 1652 CELL_VOLT_09_07 220;
BA_ "FlexKomSID" SG_ 1652 CELL_VOLT_09_07 1213;
BA_ "FlexKomSigStartPos" SG_ 1652 CELL_VOLT_09_07 7;
BA_ "FlexKomSigLaenge" SG_ 1652 CELL_VOLT_09_07 16;
BA_ "FlexKomSigName" SG_ 1652 CELL_VOLT_09_07 "CELL_VOLT_09_07";
BA_ "FlexKomComment" SG_ 1652 CELL_VOLT_09_07 "CELL_09 Voltage";
BA_ "FlexKomIsMotorola" SG_ 1652 CELL_VOLT_09_07 1;
BA_ "GenSigSendType" SG_ 1636 CELL_VOLT_12_06 0;
BA_ "GenSigCycleTime" SG_ 1636 CELL_VOLT_12_06 40;
BA_ "FlexKomSigStartValue" SG_ 1636 CELL_VOLT_12_06 "0000h";
BA_ "GenSigTimeout_BMU" SG_ 1636 CELL_VOLT_12_06 220;
BA_ "FlexKomSID" SG_ 1636 CELL_VOLT_12_06 1248;
BA_ "FlexKomSigStartPos" SG_ 1636 CELL_VOLT_12_06 55;
BA_ "FlexKomSigLaenge" SG_ 1636 CELL_VOLT_12_06 16;
BA_ "FlexKomSigName" SG_ 1636 CELL_VOLT_12_06 "CELL_VOLT_12_06";
BA_ "FlexKomComment" SG_ 1636 CELL_VOLT_12_06 "CELL_12 Voltage";
BA_ "FlexKomIsMotorola" SG_ 1636 CELL_VOLT_12_06 1;
BA_ "GenSigSendType" SG_ 1636 CELL_VOLT_11_06 0;
BA_ "GenSigCycleTime" SG_ 1636 CELL_VOLT_11_06 40;
BA_ "FlexKomSigStartValue" SG_ 1636 CELL_VOLT_11_06 "0000h";
BA_ "GenSigTimeout_BMU" SG_ 1636 CELL_VOLT_11_06 220;
BA_ "FlexKomSID" SG_ 1636 CELL_VOLT_11_06 1236;
BA_ "FlexKomSigStartPos" SG_ 1636 CELL_VOLT_11_06 39;
BA_ "FlexKomSigLaenge" SG_ 1636 CELL_VOLT_11_06 16;
BA_ "FlexKomSigName" SG_ 1636 CELL_VOLT_11_06 "CELL_VOLT_11_06";
BA_ "FlexKomComment" SG_ 1636 CELL_VOLT_11_06 "CELL_11 Voltage";
BA_ "FlexKomIsMotorola" SG_ 1636 CELL_VOLT_11_06 1;
BA_ "GenSigSendType" SG_ 1636 CELL_VOLT_10_06 0;
BA_ "GenSigCycleTime" SG_ 1636 CELL_VOLT_10_06 40;
BA_ "FlexKomSigStartValue" SG_ 1636 CELL_VOLT_10_06 "0000h";
BA_ "GenSigTimeout_BMU" SG_ 1636 CELL_VOLT_10_06 220;
BA_ "FlexKomSID" SG_ 1636 CELL_VOLT_10_06 1224;
BA_ "FlexKomSigStartPos" SG_ 1636 CELL_VOLT_10_06 23;
BA_ "FlexKomSigLaenge" SG_ 1636 CELL_VOLT_10_06 16;
BA_ "FlexKomSigName" SG_ 1636 CELL_VOLT_10_06 "CELL_VOLT_10_06";
BA_ "FlexKomComment" SG_ 1636 CELL_VOLT_10_06 "CELL_10 Voltage";
BA_ "FlexKomIsMotorola" SG_ 1636 CELL_VOLT_10_06 1;
BA_ "GenSigSendType" SG_ 1636 CELL_VOLT_09_06 0;
BA_ "GenSigCycleTime" SG_ 1636 CELL_VOLT_09_06 40;
BA_ "FlexKomSigStartValue" SG_ 1636 CELL_VOLT_09_06 "0000h";
BA_ "GenSigTimeout_BMU" SG_ 1636 CELL_VOLT_09_06 220;
BA_ "FlexKomSID" SG_ 1636 CELL_VOLT_09_06 1212;
BA_ "FlexKomSigStartPos" SG_ 1636 CELL_VOLT_09_06 7;
BA_ "FlexKomSigLaenge" SG_ 1636 CELL_VOLT_09_06 16;
BA_ "FlexKomSigName" SG_ 1636 CELL_VOLT_09_06 "CELL_VOLT_09_06";
BA_ "FlexKomComment" SG_ 1636 CELL_VOLT_09_06 "CELL_09 Voltage";
BA_ "FlexKomIsMotorola" SG_ 1636 CELL_VOLT_09_06 1;
BA_ "GenSigSendType" SG_ 1620 CELL_VOLT_12_05 0;
BA_ "GenSigCycleTime" SG_ 1620 CELL_VOLT_12_05 40;
BA_ "FlexKomSigStartValue" SG_ 1620 CELL_VOLT_12_05 "0000h";
BA_ "GenSigTimeout_BMU" SG_ 1620 CELL_VOLT_12_05 220;
BA_ "FlexKomSID" SG_ 1620 CELL_VOLT_12_05 1247;
BA_ "FlexKomSigStartPos" SG_ 1620 CELL_VOLT_12_05 55;
BA_ "FlexKomSigLaenge" SG_ 1620 CELL_VOLT_12_05 16;
BA_ "FlexKomSigName" SG_ 1620 CELL_VOLT_12_05 "CELL_VOLT_12_05";
BA_ "FlexKomComment" SG_ 1620 CELL_VOLT_12_05 "CELL_12 Voltage";
BA_ "FlexKomIsMotorola" SG_ 1620 CELL_VOLT_12_05 1;
BA_ "GenSigSendType" SG_ 1620 CELL_VOLT_11_05 0;
BA_ "GenSigCycleTime" SG_ 1620 CELL_VOLT_11_05 40;
BA_ "FlexKomSigStartValue" SG_ 1620 CELL_VOLT_11_05 "0000h";
BA_ "GenSigTimeout_BMU" SG_ 1620 CELL_VOLT_11_05 220;
BA_ "FlexKomSID" SG_ 1620 CELL_VOLT_11_05 1235;
BA_ "FlexKomSigStartPos" SG_ 1620 CELL_VOLT_11_05 39;
BA_ "FlexKomSigLaenge" SG_ 1620 CELL_VOLT_11_05 16;
BA_ "FlexKomSigName" SG_ 1620 CELL_VOLT_11_05 "CELL_VOLT_11_05";
BA_ "FlexKomComment" SG_ 1620 CELL_VOLT_11_05 "CELL_11 Voltage";
BA_ "FlexKomIsMotorola" SG_ 1620 CELL_VOLT_11_05 1;
BA_ "GenSigSendType" SG_ 1620 CELL_VOLT_10_05 0;
BA_ "GenSigCycleTime" SG_ 1620 CELL_VOLT_10_05 40;
BA_ "FlexKomSigStartValue" SG_ 1620 CELL_VOLT_10_05 "0000h";
BA_ "GenSigTimeout_BMU" SG_ 1620 CELL_VOLT_10_05 220;
BA_ "FlexKomSID" SG_ 1620 CELL_VOLT_10_05 1223;
BA_ "FlexKomSigStartPos" SG_ 1620 CELL_VOLT_10_05 23;
BA_ "FlexKomSigLaenge" SG_ 1620 CELL_VOLT_10_05 16;
BA_ "FlexKomSigName" SG_ 1620 CELL_VOLT_10_05 "CELL_VOLT_10_05";
BA_ "FlexKomComment" SG_ 1620 CELL_VOLT_10_05 "CELL_10 Voltage";
BA_ "FlexKomIsMotorola" SG_ 1620 CELL_VOLT_10_05 1;
BA_ "GenSigSendType" SG_ 1620 CELL_VOLT_09_05 0;
BA_ "GenSigCycleTime" SG_ 1620 CELL_VOLT_09_05 40;
BA_ "FlexKomSigStartValue" SG_ 1620 CELL_VOLT_09_05 "0000h";
BA_ "GenSigTimeout_BMU" SG_ 1620 CELL_VOLT_09_05 220;
BA_ "FlexKomSID" SG_ 1620 CELL_VOLT_09_05 1211;
BA_ "FlexKomSigStartPos" SG_ 1620 CELL_VOLT_09_05 7;
BA_ "FlexKomSigLaenge" SG_ 1620 CELL_VOLT_09_05 16;
BA_ "FlexKomSigName" SG_ 1620 CELL_VOLT_09_05 "CELL_VOLT_09_05";
BA_ "FlexKomComment" SG_ 1620 CELL_VOLT_09_05 "CELL_09 Voltage";
BA_ "FlexKomIsMotorola" SG_ 1620 CELL_VOLT_09_05 1;
BA_ "GenSigSendType" SG_ 1604 CELL_VOLT_12_04 0;
BA_ "GenSigCycleTime" SG_ 1604 CELL_VOLT_12_04 40;
BA_ "FlexKomSigStartValue" SG_ 1604 CELL_VOLT_12_04 "0000h";
BA_ "GenSigTimeout_BMU" SG_ 1604 CELL_VOLT_12_04 220;
BA_ "FlexKomSID" SG_ 1604 CELL_VOLT_12_04 1246;
BA_ "FlexKomSigStartPos" SG_ 1604 CELL_VOLT_12_04 55;
BA_ "FlexKomSigLaenge" SG_ 1604 CELL_VOLT_12_04 16;
BA_ "FlexKomSigName" SG_ 1604 CELL_VOLT_12_04 "CELL_VOLT_12_04";
BA_ "FlexKomComment" SG_ 1604 CELL_VOLT_12_04 "CELL_12 Voltage";
BA_ "FlexKomIsMotorola" SG_ 1604 CELL_VOLT_12_04 1;
BA_ "GenSigSendType" SG_ 1604 CELL_VOLT_11_04 0;
BA_ "GenSigCycleTime" SG_ 1604 CELL_VOLT_11_04 40;
BA_ "FlexKomSigStartValue" SG_ 1604 CELL_VOLT_11_04 "0000h";
BA_ "GenSigTimeout_BMU" SG_ 1604 CELL_VOLT_11_04 220;
BA_ "FlexKomSID" SG_ 1604 CELL_VOLT_11_04 1234;
BA_ "FlexKomSigStartPos" SG_ 1604 CELL_VOLT_11_04 39;
BA_ "FlexKomSigLaenge" SG_ 1604 CELL_VOLT_11_04 16;
BA_ "FlexKomSigName" SG_ 1604 CELL_VOLT_11_04 "CELL_VOLT_11_04";
BA_ "FlexKomComment" SG_ 1604 CELL_VOLT_11_04 "CELL_11 Voltage";
BA_ "FlexKomIsMotorola" SG_ 1604 CELL_VOLT_11_04 1;
BA_ "GenSigSendType" SG_ 1604 CELL_VOLT_10_04 0;
BA_ "GenSigCycleTime" SG_ 1604 CELL_VOLT_10_04 40;
BA_ "FlexKomSigStartValue" SG_ 1604 CELL_VOLT_10_04 "0000h";
BA_ "GenSigTimeout_BMU" SG_ 1604 CELL_VOLT_10_04 220;
BA_ "FlexKomSID" SG_ 1604 CELL_VOLT_10_04 1222;
BA_ "FlexKomSigStartPos" SG_ 1604 CELL_VOLT_10_04 23;
BA_ "FlexKomSigLaenge" SG_ 1604 CELL_VOLT_10_04 16;
BA_ "FlexKomSigName" SG_ 1604 CELL_VOLT_10_04 "CELL_VOLT_10_04";
BA_ "FlexKomComment" SG_ 1604 CELL_VOLT_10_04 "CELL_10 Voltage";
BA_ "FlexKomIsMotorola" SG_ 1604 CELL_VOLT_10_04 1;
BA_ "GenSigSendType" SG_ 1604 CELL_VOLT_09_04 0;
BA_ "GenSigCycleTime" SG_ 1604 CELL_VOLT_09_04 40;
BA_ "FlexKomSigStartValue" SG_ 1604 CELL_VOLT_09_04 "0000h";
BA_ "GenSigTimeout_BMU" SG_ 1604 CELL_VOLT_09_04 220;
BA_ "FlexKomSID" SG_ 1604 CELL_VOLT_09_04 1210;
BA_ "FlexKomSigStartPos" SG_ 1604 CELL_VOLT_09_04 7;
BA_ "FlexKomSigLaenge" SG_ 1604 CELL_VOLT_09_04 16;
BA_ "FlexKomSigName" SG_ 1604 CELL_VOLT_09_04 "CELL_VOLT_09_04";
BA_ "FlexKomComment" SG_ 1604 CELL_VOLT_09_04 "CELL_09 Voltage";
BA_ "FlexKomIsMotorola" SG_ 1604 CELL_VOLT_09_04 1;
BA_ "GenSigSendType" SG_ 1588 CELL_VOLT_12_03 0;
BA_ "GenSigCycleTime" SG_ 1588 CELL_VOLT_12_03 40;
BA_ "FlexKomSigStartValue" SG_ 1588 CELL_VOLT_12_03 "0000h";
BA_ "GenSigTimeout_BMU" SG_ 1588 CELL_VOLT_12_03 220;
BA_ "FlexKomSID" SG_ 1588 CELL_VOLT_12_03 1245;
BA_ "FlexKomSigStartPos" SG_ 1588 CELL_VOLT_12_03 55;
BA_ "FlexKomSigLaenge" SG_ 1588 CELL_VOLT_12_03 16;
BA_ "FlexKomSigName" SG_ 1588 CELL_VOLT_12_03 "CELL_VOLT_12_03";
BA_ "FlexKomComment" SG_ 1588 CELL_VOLT_12_03 "CELL_12 Voltage";
BA_ "FlexKomIsMotorola" SG_ 1588 CELL_VOLT_12_03 1;
BA_ "GenSigSendType" SG_ 1588 CELL_VOLT_11_03 0;
BA_ "GenSigCycleTime" SG_ 1588 CELL_VOLT_11_03 40;
BA_ "FlexKomSigStartValue" SG_ 1588 CELL_VOLT_11_03 "0000h";
BA_ "GenSigTimeout_BMU" SG_ 1588 CELL_VOLT_11_03 220;
BA_ "FlexKomSID" SG_ 1588 CELL_VOLT_11_03 1233;
BA_ "FlexKomSigStartPos" SG_ 1588 CELL_VOLT_11_03 39;
BA_ "FlexKomSigLaenge" SG_ 1588 CELL_VOLT_11_03 16;
BA_ "FlexKomSigName" SG_ 1588 CELL_VOLT_11_03 "CELL_VOLT_11_03";
BA_ "FlexKomComment" SG_ 1588 CELL_VOLT_11_03 "CELL_11 Voltage";
BA_ "FlexKomIsMotorola" SG_ 1588 CELL_VOLT_11_03 1;
BA_ "GenSigSendType" SG_ 1588 CELL_VOLT_10_03 0;
BA_ "GenSigCycleTime" SG_ 1588 CELL_VOLT_10_03 40;
BA_ "FlexKomSigStartValue" SG_ 1588 CELL_VOLT_10_03 "0000h";
BA_ "GenSigTimeout_BMU" SG_ 1588 CELL_VOLT_10_03 220;
BA_ "FlexKomSID" SG_ 1588 CELL_VOLT_10_03 1221;
BA_ "FlexKomSigStartPos" SG_ 1588 CELL_VOLT_10_03 23;
BA_ "FlexKomSigLaenge" SG_ 1588 CELL_VOLT_10_03 16;
BA_ "FlexKomSigName" SG_ 1588 CELL_VOLT_10_03 "CELL_VOLT_10_03";
BA_ "FlexKomComment" SG_ 1588 CELL_VOLT_10_03 "CELL_10 Voltage";
BA_ "FlexKomIsMotorola" SG_ 1588 CELL_VOLT_10_03 1;
BA_ "GenSigSendType" SG_ 1588 CELL_VOLT_09_03 0;
BA_ "GenSigCycleTime" SG_ 1588 CELL_VOLT_09_03 40;
BA_ "FlexKomSigStartValue" SG_ 1588 CELL_VOLT_09_03 "0000h";
BA_ "GenSigTimeout_BMU" SG_ 1588 CELL_VOLT_09_03 220;
BA_ "FlexKomSID" SG_ 1588 CELL_VOLT_09_03 1209;
BA_ "FlexKomSigStartPos" SG_ 1588 CELL_VOLT_09_03 7;
BA_ "FlexKomSigLaenge" SG_ 1588 CELL_VOLT_09_03 16;
BA_ "FlexKomSigName" SG_ 1588 CELL_VOLT_09_03 "CELL_VOLT_09_03";
BA_ "FlexKomComment" SG_ 1588 CELL_VOLT_09_03 "CELL_09 Voltage";
BA_ "FlexKomIsMotorola" SG_ 1588 CELL_VOLT_09_03 1;
BA_ "GenSigSendType" SG_ 1572 CELL_VOLT_12_02 0;
BA_ "GenSigCycleTime" SG_ 1572 CELL_VOLT_12_02 40;
BA_ "FlexKomSigStartValue" SG_ 1572 CELL_VOLT_12_02 "0000h";
BA_ "GenSigTimeout_BMU" SG_ 1572 CELL_VOLT_12_02 220;
BA_ "FlexKomSID" SG_ 1572 CELL_VOLT_12_02 1244;
BA_ "FlexKomSigStartPos" SG_ 1572 CELL_VOLT_12_02 55;
BA_ "FlexKomSigLaenge" SG_ 1572 CELL_VOLT_12_02 16;
BA_ "FlexKomSigName" SG_ 1572 CELL_VOLT_12_02 "CELL_VOLT_12_02";
BA_ "FlexKomComment" SG_ 1572 CELL_VOLT_12_02 "CELL_12 Voltage";
BA_ "FlexKomIsMotorola" SG_ 1572 CELL_VOLT_12_02 1;
BA_ "GenSigSendType" SG_ 1572 CELL_VOLT_11_02 0;
BA_ "GenSigCycleTime" SG_ 1572 CELL_VOLT_11_02 40;
BA_ "FlexKomSigStartValue" SG_ 1572 CELL_VOLT_11_02 "0000h";
BA_ "GenSigTimeout_BMU" SG_ 1572 CELL_VOLT_11_02 220;
BA_ "FlexKomSID" SG_ 1572 CELL_VOLT_11_02 1232;
BA_ "FlexKomSigStartPos" SG_ 1572 CELL_VOLT_11_02 39;
BA_ "FlexKomSigLaenge" SG_ 1572 CELL_VOLT_11_02 16;
BA_ "FlexKomSigName" SG_ 1572 CELL_VOLT_11_02 "CELL_VOLT_11_02";
BA_ "FlexKomComment" SG_ 1572 CELL_VOLT_11_02 "CELL_11 Voltage";
BA_ "FlexKomIsMotorola" SG_ 1572 CELL_VOLT_11_02 1;
BA_ "GenSigSendType" SG_ 1572 CELL_VOLT_10_02 0;
BA_ "GenSigCycleTime" SG_ 1572 CELL_VOLT_10_02 40;
BA_ "FlexKomSigStartValue" SG_ 1572 CELL_VOLT_10_02 "0000h";
BA_ "GenSigTimeout_BMU" SG_ 1572 CELL_VOLT_10_02 220;
BA_ "FlexKomSID" SG_ 1572 CELL_VOLT_10_02 1220;
BA_ "FlexKomSigStartPos" SG_ 1572 CELL_VOLT_10_02 23;
BA_ "FlexKomSigLaenge" SG_ 1572 CELL_VOLT_10_02 16;
BA_ "FlexKomSigName" SG_ 1572 CELL_VOLT_10_02 "CELL_VOLT_10_02";
BA_ "FlexKomComment" SG_ 1572 CELL_VOLT_10_02 "CELL_10 Voltage";
BA_ "FlexKomIsMotorola" SG_ 1572 CELL_VOLT_10_02 1;
BA_ "GenSigSendType" SG_ 1572 CELL_VOLT_09_02 0;
BA_ "GenSigCycleTime" SG_ 1572 CELL_VOLT_09_02 40;
BA_ "FlexKomSigStartValue" SG_ 1572 CELL_VOLT_09_02 "0000h";
BA_ "GenSigTimeout_BMU" SG_ 1572 CELL_VOLT_09_02 220;
BA_ "FlexKomSID" SG_ 1572 CELL_VOLT_09_02 1208;
BA_ "FlexKomSigStartPos" SG_ 1572 CELL_VOLT_09_02 7;
BA_ "FlexKomSigLaenge" SG_ 1572 CELL_VOLT_09_02 16;
BA_ "FlexKomSigName" SG_ 1572 CELL_VOLT_09_02 "CELL_VOLT_09_02";
BA_ "FlexKomComment" SG_ 1572 CELL_VOLT_09_02 "CELL_09 Voltage";
BA_ "FlexKomIsMotorola" SG_ 1572 CELL_VOLT_09_02 1;
BA_ "GenSigSendType" SG_ 1556 CELL_VOLT_12_01 0;
BA_ "GenSigCycleTime" SG_ 1556 CELL_VOLT_12_01 40;
BA_ "FlexKomSigStartValue" SG_ 1556 CELL_VOLT_12_01 "0000h";
BA_ "GenSigTimeout_BMU" SG_ 1556 CELL_VOLT_12_01 220;
BA_ "FlexKomSID" SG_ 1556 CELL_VOLT_12_01 1243;
BA_ "FlexKomSigStartPos" SG_ 1556 CELL_VOLT_12_01 55;
BA_ "FlexKomSigLaenge" SG_ 1556 CELL_VOLT_12_01 16;
BA_ "FlexKomSigName" SG_ 1556 CELL_VOLT_12_01 "CELL_VOLT_12_01";
BA_ "FlexKomComment" SG_ 1556 CELL_VOLT_12_01 "CELL_12 Voltage";
BA_ "FlexKomIsMotorola" SG_ 1556 CELL_VOLT_12_01 1;
BA_ "GenSigSendType" SG_ 1556 CELL_VOLT_11_01 0;
BA_ "GenSigCycleTime" SG_ 1556 CELL_VOLT_11_01 40;
BA_ "FlexKomSigStartValue" SG_ 1556 CELL_VOLT_11_01 "0000h";
BA_ "GenSigTimeout_BMU" SG_ 1556 CELL_VOLT_11_01 220;
BA_ "FlexKomSID" SG_ 1556 CELL_VOLT_11_01 1231;
BA_ "FlexKomSigStartPos" SG_ 1556 CELL_VOLT_11_01 39;
BA_ "FlexKomSigLaenge" SG_ 1556 CELL_VOLT_11_01 16;
BA_ "FlexKomSigName" SG_ 1556 CELL_VOLT_11_01 "CELL_VOLT_11_01";
BA_ "FlexKomComment" SG_ 1556 CELL_VOLT_11_01 "CELL_11 Voltage";
BA_ "FlexKomIsMotorola" SG_ 1556 CELL_VOLT_11_01 1;
BA_ "GenSigSendType" SG_ 1556 CELL_VOLT_10_01 0;
BA_ "GenSigCycleTime" SG_ 1556 CELL_VOLT_10_01 40;
BA_ "FlexKomSigStartValue" SG_ 1556 CELL_VOLT_10_01 "0000h";
BA_ "GenSigTimeout_BMU" SG_ 1556 CELL_VOLT_10_01 220;
BA_ "FlexKomSID" SG_ 1556 CELL_VOLT_10_01 1219;
BA_ "FlexKomSigStartPos" SG_ 1556 CELL_VOLT_10_01 23;
BA_ "FlexKomSigLaenge" SG_ 1556 CELL_VOLT_10_01 16;
BA_ "FlexKomSigName" SG_ 1556 CELL_VOLT_10_01 "CELL_VOLT_10_01";
BA_ "FlexKomComment" SG_ 1556 CELL_VOLT_10_01 "CELL_10 Voltage";
BA_ "FlexKomIsMotorola" SG_ 1556 CELL_VOLT_10_01 1;
BA_ "GenSigSendType" SG_ 1556 CELL_VOLT_09_01 0;
BA_ "GenSigCycleTime" SG_ 1556 CELL_VOLT_09_01 40;
BA_ "FlexKomSigStartValue" SG_ 1556 CELL_VOLT_09_01 "0000h";
BA_ "GenSigTimeout_BMU" SG_ 1556 CELL_VOLT_09_01 220;
BA_ "FlexKomSID" SG_ 1556 CELL_VOLT_09_01 1207;
BA_ "FlexKomSigStartPos" SG_ 1556 CELL_VOLT_09_01 7;
BA_ "FlexKomSigLaenge" SG_ 1556 CELL_VOLT_09_01 16;
BA_ "FlexKomSigName" SG_ 1556 CELL_VOLT_09_01 "CELL_VOLT_09_01";
BA_ "FlexKomComment" SG_ 1556 CELL_VOLT_09_01 "CELL_09 Voltage";
BA_ "FlexKomIsMotorola" SG_ 1556 CELL_VOLT_09_01 1;
BA_ "GenSigSendType" SG_ 1731 CELL_VOLT_08_12 0;
BA_ "GenSigCycleTime" SG_ 1731 CELL_VOLT_08_12 40;
BA_ "FlexKomSigStartValue" SG_ 1731 CELL_VOLT_08_12 "0000h";
BA_ "GenSigTimeout_BMU" SG_ 1731 CELL_VOLT_08_12 220;
BA_ "FlexKomSID" SG_ 1731 CELL_VOLT_08_12 1206;
BA_ "FlexKomSigStartPos" SG_ 1731 CELL_VOLT_08_12 55;
BA_ "FlexKomSigLaenge" SG_ 1731 CELL_VOLT_08_12 16;
BA_ "FlexKomSigName" SG_ 1731 CELL_VOLT_08_12 "CELL_VOLT_08_12";
BA_ "FlexKomComment" SG_ 1731 CELL_VOLT_08_12 "CELL_08 Voltage";
BA_ "FlexKomIsMotorola" SG_ 1731 CELL_VOLT_08_12 1;
BA_ "GenSigSendType" SG_ 1731 CELL_VOLT_07_12 0;
BA_ "GenSigCycleTime" SG_ 1731 CELL_VOLT_07_12 40;
BA_ "FlexKomSigStartValue" SG_ 1731 CELL_VOLT_07_12 "0000h";
BA_ "GenSigTimeout_BMU" SG_ 1731 CELL_VOLT_07_12 220;
BA_ "FlexKomSID" SG_ 1731 CELL_VOLT_07_12 1194;
BA_ "FlexKomSigStartPos" SG_ 1731 CELL_VOLT_07_12 39;
BA_ "FlexKomSigLaenge" SG_ 1731 CELL_VOLT_07_12 16;
BA_ "FlexKomSigName" SG_ 1731 CELL_VOLT_07_12 "CELL_VOLT_07_12";
BA_ "FlexKomComment" SG_ 1731 CELL_VOLT_07_12 "CELL_07 Voltage";
BA_ "FlexKomIsMotorola" SG_ 1731 CELL_VOLT_07_12 1;
BA_ "GenSigSendType" SG_ 1731 CELL_VOLT_06_12 0;
BA_ "GenSigCycleTime" SG_ 1731 CELL_VOLT_06_12 40;
BA_ "FlexKomSigStartValue" SG_ 1731 CELL_VOLT_06_12 "0000h";
BA_ "GenSigTimeout_BMU" SG_ 1731 CELL_VOLT_06_12 220;
BA_ "FlexKomSID" SG_ 1731 CELL_VOLT_06_12 1182;
BA_ "FlexKomSigStartPos" SG_ 1731 CELL_VOLT_06_12 23;
BA_ "FlexKomSigLaenge" SG_ 1731 CELL_VOLT_06_12 16;
BA_ "FlexKomSigName" SG_ 1731 CELL_VOLT_06_12 "CELL_VOLT_06_12";
BA_ "FlexKomComment" SG_ 1731 CELL_VOLT_06_12 "CELL_06 Voltage";
BA_ "FlexKomIsMotorola" SG_ 1731 CELL_VOLT_06_12 1;
BA_ "GenSigSendType" SG_ 1731 CELL_VOLT_05_12 0;
BA_ "GenSigCycleTime" SG_ 1731 CELL_VOLT_05_12 40;
BA_ "FlexKomSigStartValue" SG_ 1731 CELL_VOLT_05_12 "0000h";
BA_ "GenSigTimeout_BMU" SG_ 1731 CELL_VOLT_05_12 220;
BA_ "FlexKomSID" SG_ 1731 CELL_VOLT_05_12 1170;
BA_ "FlexKomSigStartPos" SG_ 1731 CELL_VOLT_05_12 7;
BA_ "FlexKomSigLaenge" SG_ 1731 CELL_VOLT_05_12 16;
BA_ "FlexKomSigName" SG_ 1731 CELL_VOLT_05_12 "CELL_VOLT_05_12";
BA_ "FlexKomComment" SG_ 1731 CELL_VOLT_05_12 "CELL_05 Voltage";
BA_ "FlexKomIsMotorola" SG_ 1731 CELL_VOLT_05_12 1;
BA_ "GenSigSendType" SG_ 1715 CELL_VOLT_08_11 0;
BA_ "GenSigCycleTime" SG_ 1715 CELL_VOLT_08_11 40;
BA_ "FlexKomSigStartValue" SG_ 1715 CELL_VOLT_08_11 "0000h";
BA_ "GenSigTimeout_BMU" SG_ 1715 CELL_VOLT_08_11 220;
BA_ "FlexKomSID" SG_ 1715 CELL_VOLT_08_11 1205;
BA_ "FlexKomSigStartPos" SG_ 1715 CELL_VOLT_08_11 55;
BA_ "FlexKomSigLaenge" SG_ 1715 CELL_VOLT_08_11 16;
BA_ "FlexKomSigName" SG_ 1715 CELL_VOLT_08_11 "CELL_VOLT_08_11";
BA_ "FlexKomComment" SG_ 1715 CELL_VOLT_08_11 "CELL_08 Voltage";
BA_ "FlexKomIsMotorola" SG_ 1715 CELL_VOLT_08_11 1;
BA_ "GenSigSendType" SG_ 1715 CELL_VOLT_07_11 0;
BA_ "GenSigCycleTime" SG_ 1715 CELL_VOLT_07_11 40;
BA_ "FlexKomSigStartValue" SG_ 1715 CELL_VOLT_07_11 "0000h";
BA_ "GenSigTimeout_BMU" SG_ 1715 CELL_VOLT_07_11 220;
BA_ "FlexKomSID" SG_ 1715 CELL_VOLT_07_11 1193;
BA_ "FlexKomSigStartPos" SG_ 1715 CELL_VOLT_07_11 39;
BA_ "FlexKomSigLaenge" SG_ 1715 CELL_VOLT_07_11 16;
BA_ "FlexKomSigName" SG_ 1715 CELL_VOLT_07_11 "CELL_VOLT_07_11";
BA_ "FlexKomComment" SG_ 1715 CELL_VOLT_07_11 "CELL_07 Voltage";
BA_ "FlexKomIsMotorola" SG_ 1715 CELL_VOLT_07_11 1;
BA_ "GenSigSendType" SG_ 1715 CELL_VOLT_06_11 0;
BA_ "GenSigCycleTime" SG_ 1715 CELL_VOLT_06_11 40;
BA_ "FlexKomSigStartValue" SG_ 1715 CELL_VOLT_06_11 "0000h";
BA_ "GenSigTimeout_BMU" SG_ 1715 CELL_VOLT_06_11 220;
BA_ "FlexKomSID" SG_ 1715 CELL_VOLT_06_11 1181;
BA_ "FlexKomSigStartPos" SG_ 1715 CELL_VOLT_06_11 23;
BA_ "FlexKomSigLaenge" SG_ 1715 CELL_VOLT_06_11 16;
BA_ "FlexKomSigName" SG_ 1715 CELL_VOLT_06_11 "CELL_VOLT_06_11";
BA_ "FlexKomComment" SG_ 1715 CELL_VOLT_06_11 "CELL_06 Voltage";
BA_ "FlexKomIsMotorola" SG_ 1715 CELL_VOLT_06_11 1;
BA_ "GenSigSendType" SG_ 1715 CELL_VOLT_05_11 0;
BA_ "GenSigCycleTime" SG_ 1715 CELL_VOLT_05_11 40;
BA_ "FlexKomSigStartValue" SG_ 1715 CELL_VOLT_05_11 "0000h";
BA_ "GenSigTimeout_BMU" SG_ 1715 CELL_VOLT_05_11 220;
BA_ "FlexKomSID" SG_ 1715 CELL_VOLT_05_11 1169;
BA_ "FlexKomSigStartPos" SG_ 1715 CELL_VOLT_05_11 7;
BA_ "FlexKomSigLaenge" SG_ 1715 CELL_VOLT_05_11 16;
BA_ "FlexKomSigName" SG_ 1715 CELL_VOLT_05_11 "CELL_VOLT_05_11";
BA_ "FlexKomComment" SG_ 1715 CELL_VOLT_05_11 "CELL_05 Voltage";
BA_ "FlexKomIsMotorola" SG_ 1715 CELL_VOLT_05_11 1;
BA_ "GenSigSendType" SG_ 1699 CELL_VOLT_08_10 0;
BA_ "GenSigCycleTime" SG_ 1699 CELL_VOLT_08_10 40;
BA_ "FlexKomSigStartValue" SG_ 1699 CELL_VOLT_08_10 "0000h";
BA_ "GenSigTimeout_BMU" SG_ 1699 CELL_VOLT_08_10 220;
BA_ "FlexKomSID" SG_ 1699 CELL_VOLT_08_10 1204;
BA_ "FlexKomSigStartPos" SG_ 1699 CELL_VOLT_08_10 55;
BA_ "FlexKomSigLaenge" SG_ 1699 CELL_VOLT_08_10 16;
BA_ "FlexKomSigName" SG_ 1699 CELL_VOLT_08_10 "CELL_VOLT_08_10";
BA_ "FlexKomComment" SG_ 1699 CELL_VOLT_08_10 "CELL_08 Voltage";
BA_ "FlexKomIsMotorola" SG_ 1699 CELL_VOLT_08_10 1;
BA_ "GenSigSendType" SG_ 1699 CELL_VOLT_07_10 0;
BA_ "GenSigCycleTime" SG_ 1699 CELL_VOLT_07_10 40;
BA_ "FlexKomSigStartValue" SG_ 1699 CELL_VOLT_07_10 "0000h";
BA_ "GenSigTimeout_BMU" SG_ 1699 CELL_VOLT_07_10 220;
BA_ "FlexKomSID" SG_ 1699 CELL_VOLT_07_10 1192;
BA_ "FlexKomSigStartPos" SG_ 1699 CELL_VOLT_07_10 39;
BA_ "FlexKomSigLaenge" SG_ 1699 CELL_VOLT_07_10 16;
BA_ "FlexKomSigName" SG_ 1699 CELL_VOLT_07_10 "CELL_VOLT_07_10";
BA_ "FlexKomComment" SG_ 1699 CELL_VOLT_07_10 "CELL_07 Voltage";
BA_ "FlexKomIsMotorola" SG_ 1699 CELL_VOLT_07_10 1;
BA_ "GenSigSendType" SG_ 1699 CELL_VOLT_06_10 0;
BA_ "GenSigCycleTime" SG_ 1699 CELL_VOLT_06_10 40;
BA_ "FlexKomSigStartValue" SG_ 1699 CELL_VOLT_06_10 "0000h";
BA_ "GenSigTimeout_BMU" SG_ 1699 CELL_VOLT_06_10 220;
BA_ "FlexKomSID" SG_ 1699 CELL_VOLT_06_10 1180;
BA_ "FlexKomSigStartPos" SG_ 1699 CELL_VOLT_06_10 23;
BA_ "FlexKomSigLaenge" SG_ 1699 CELL_VOLT_06_10 16;
BA_ "FlexKomSigName" SG_ 1699 CELL_VOLT_06_10 "CELL_VOLT_06_10";
BA_ "FlexKomComment" SG_ 1699 CELL_VOLT_06_10 "CELL_06 Voltage";
BA_ "FlexKomIsMotorola" SG_ 1699 CELL_VOLT_06_10 1;
BA_ "GenSigSendType" SG_ 1699 CELL_VOLT_05_10 0;
BA_ "GenSigCycleTime" SG_ 1699 CELL_VOLT_05_10 40;
BA_ "FlexKomSigStartValue" SG_ 1699 CELL_VOLT_05_10 "0000h";
BA_ "GenSigTimeout_BMU" SG_ 1699 CELL_VOLT_05_10 220;
BA_ "FlexKomSID" SG_ 1699 CELL_VOLT_05_10 1168;
BA_ "FlexKomSigStartPos" SG_ 1699 CELL_VOLT_05_10 7;
BA_ "FlexKomSigLaenge" SG_ 1699 CELL_VOLT_05_10 16;
BA_ "FlexKomSigName" SG_ 1699 CELL_VOLT_05_10 "CELL_VOLT_05_10";
BA_ "FlexKomComment" SG_ 1699 CELL_VOLT_05_10 "CELL_05 Voltage";
BA_ "FlexKomIsMotorola" SG_ 1699 CELL_VOLT_05_10 1;
BA_ "GenSigSendType" SG_ 1683 CELL_VOLT_08_09 0;
BA_ "GenSigCycleTime" SG_ 1683 CELL_VOLT_08_09 40;
BA_ "FlexKomSigStartValue" SG_ 1683 CELL_VOLT_08_09 "0000h";
BA_ "GenSigTimeout_BMU" SG_ 1683 CELL_VOLT_08_09 220;
BA_ "FlexKomSID" SG_ 1683 CELL_VOLT_08_09 1203;
BA_ "FlexKomSigStartPos" SG_ 1683 CELL_VOLT_08_09 55;
BA_ "FlexKomSigLaenge" SG_ 1683 CELL_VOLT_08_09 16;
BA_ "FlexKomSigName" SG_ 1683 CELL_VOLT_08_09 "CELL_VOLT_08_09";
BA_ "FlexKomComment" SG_ 1683 CELL_VOLT_08_09 "CELL_08 Voltage";
BA_ "FlexKomIsMotorola" SG_ 1683 CELL_VOLT_08_09 1;
BA_ "GenSigSendType" SG_ 1683 CELL_VOLT_07_09 0;
BA_ "GenSigCycleTime" SG_ 1683 CELL_VOLT_07_09 40;
BA_ "FlexKomSigStartValue" SG_ 1683 CELL_VOLT_07_09 "0000h";
BA_ "GenSigTimeout_BMU" SG_ 1683 CELL_VOLT_07_09 220;
BA_ "FlexKomSID" SG_ 1683 CELL_VOLT_07_09 1191;
BA_ "FlexKomSigStartPos" SG_ 1683 CELL_VOLT_07_09 39;
BA_ "FlexKomSigLaenge" SG_ 1683 CELL_VOLT_07_09 16;
BA_ "FlexKomSigName" SG_ 1683 CELL_VOLT_07_09 "CELL_VOLT_07_09";
BA_ "FlexKomComment" SG_ 1683 CELL_VOLT_07_09 "CELL_07 Voltage";
BA_ "FlexKomIsMotorola" SG_ 1683 CELL_VOLT_07_09 1;
BA_ "GenSigSendType" SG_ 1683 CELL_VOLT_06_09 0;
BA_ "GenSigCycleTime" SG_ 1683 CELL_VOLT_06_09 40;
BA_ "FlexKomSigStartValue" SG_ 1683 CELL_VOLT_06_09 "0000h";
BA_ "GenSigTimeout_BMU" SG_ 1683 CELL_VOLT_06_09 220;
BA_ "FlexKomSID" SG_ 1683 CELL_VOLT_06_09 1179;
BA_ "FlexKomSigStartPos" SG_ 1683 CELL_VOLT_06_09 23;
BA_ "FlexKomSigLaenge" SG_ 1683 CELL_VOLT_06_09 16;
BA_ "FlexKomSigName" SG_ 1683 CELL_VOLT_06_09 "CELL_VOLT_06_09";
BA_ "FlexKomComment" SG_ 1683 CELL_VOLT_06_09 "CELL_06 Voltage";
BA_ "FlexKomIsMotorola" SG_ 1683 CELL_VOLT_06_09 1;
BA_ "GenSigSendType" SG_ 1683 CELL_VOLT_05_09 0;
BA_ "GenSigCycleTime" SG_ 1683 CELL_VOLT_05_09 40;
BA_ "FlexKomSigStartValue" SG_ 1683 CELL_VOLT_05_09 "0000h";
BA_ "GenSigTimeout_BMU" SG_ 1683 CELL_VOLT_05_09 220;
BA_ "FlexKomSID" SG_ 1683 CELL_VOLT_05_09 1167;
BA_ "FlexKomSigStartPos" SG_ 1683 CELL_VOLT_05_09 7;
BA_ "FlexKomSigLaenge" SG_ 1683 CELL_VOLT_05_09 16;
BA_ "FlexKomSigName" SG_ 1683 CELL_VOLT_05_09 "CELL_VOLT_05_09";
BA_ "FlexKomComment" SG_ 1683 CELL_VOLT_05_09 "CELL_05 Voltage";
BA_ "FlexKomIsMotorola" SG_ 1683 CELL_VOLT_05_09 1;
BA_ "GenSigSendType" SG_ 1667 CELL_VOLT_08_08 0;
BA_ "GenSigCycleTime" SG_ 1667 CELL_VOLT_08_08 40;
BA_ "FlexKomSigStartValue" SG_ 1667 CELL_VOLT_08_08 "0000h";
BA_ "GenSigTimeout_BMU" SG_ 1667 CELL_VOLT_08_08 220;
BA_ "FlexKomSID" SG_ 1667 CELL_VOLT_08_08 1202;
BA_ "FlexKomSigStartPos" SG_ 1667 CELL_VOLT_08_08 55;
BA_ "FlexKomSigLaenge" SG_ 1667 CELL_VOLT_08_08 16;
BA_ "FlexKomSigName" SG_ 1667 CELL_VOLT_08_08 "CELL_VOLT_08_08";
BA_ "FlexKomComment" SG_ 1667 CELL_VOLT_08_08 "CELL_08 Voltage";
BA_ "FlexKomIsMotorola" SG_ 1667 CELL_VOLT_08_08 1;
BA_ "GenSigSendType" SG_ 1667 CELL_VOLT_07_08 0;
BA_ "GenSigCycleTime" SG_ 1667 CELL_VOLT_07_08 40;
BA_ "FlexKomSigStartValue" SG_ 1667 CELL_VOLT_07_08 "0000h";
BA_ "GenSigTimeout_BMU" SG_ 1667 CELL_VOLT_07_08 220;
BA_ "FlexKomSID" SG_ 1667 CELL_VOLT_07_08 1190;
BA_ "FlexKomSigStartPos" SG_ 1667 CELL_VOLT_07_08 39;
BA_ "FlexKomSigLaenge" SG_ 1667 CELL_VOLT_07_08 16;
BA_ "FlexKomSigName" SG_ 1667 CELL_VOLT_07_08 "CELL_VOLT_07_08";
BA_ "FlexKomComment" SG_ 1667 CELL_VOLT_07_08 "CELL_07 Voltage";
BA_ "FlexKomIsMotorola" SG_ 1667 CELL_VOLT_07_08 1;
BA_ "GenSigSendType" SG_ 1667 CELL_VOLT_06_08 0;
BA_ "GenSigCycleTime" SG_ 1667 CELL_VOLT_06_08 40;
BA_ "FlexKomSigStartValue" SG_ 1667 CELL_VOLT_06_08 "0000h";
BA_ "GenSigTimeout_BMU" SG_ 1667 CELL_VOLT_06_08 220;
BA_ "FlexKomSID" SG_ 1667 CELL_VOLT_06_08 1178;
BA_ "FlexKomSigStartPos" SG_ 1667 CELL_VOLT_06_08 23;
BA_ "FlexKomSigLaenge" SG_ 1667 CELL_VOLT_06_08 16;
BA_ "FlexKomSigName" SG_ 1667 CELL_VOLT_06_08 "CELL_VOLT_06_08";
BA_ "FlexKomComment" SG_ 1667 CELL_VOLT_06_08 "CELL_06 Voltage";
BA_ "FlexKomIsMotorola" SG_ 1667 CELL_VOLT_06_08 1;
BA_ "GenSigSendType" SG_ 1667 CELL_VOLT_05_08 0;
BA_ "GenSigCycleTime" SG_ 1667 CELL_VOLT_05_08 40;
BA_ "FlexKomSigStartValue" SG_ 1667 CELL_VOLT_05_08 "0000h";
BA_ "GenSigTimeout_BMU" SG_ 1667 CELL_VOLT_05_08 220;
BA_ "FlexKomSID" SG_ 1667 CELL_VOLT_05_08 1166;
BA_ "FlexKomSigStartPos" SG_ 1667 CELL_VOLT_05_08 7;
BA_ "FlexKomSigLaenge" SG_ 1667 CELL_VOLT_05_08 16;
BA_ "FlexKomSigName" SG_ 1667 CELL_VOLT_05_08 "CELL_VOLT_05_08";
BA_ "FlexKomComment" SG_ 1667 CELL_VOLT_05_08 "CELL_05 Voltage";
BA_ "FlexKomIsMotorola" SG_ 1667 CELL_VOLT_05_08 1;
BA_ "GenSigSendType" SG_ 1651 CELL_VOLT_08_07 0;
BA_ "GenSigCycleTime" SG_ 1651 CELL_VOLT_08_07 40;
BA_ "FlexKomSigStartValue" SG_ 1651 CELL_VOLT_08_07 "0000h";
BA_ "GenSigTimeout_BMU" SG_ 1651 CELL_VOLT_08_07 220;
BA_ "FlexKomSID" SG_ 1651 CELL_VOLT_08_07 1201;
BA_ "FlexKomSigStartPos" SG_ 1651 CELL_VOLT_08_07 55;
BA_ "FlexKomSigLaenge" SG_ 1651 CELL_VOLT_08_07 16;
BA_ "FlexKomSigName" SG_ 1651 CELL_VOLT_08_07 "CELL_VOLT_08_07";
BA_ "FlexKomComment" SG_ 1651 CELL_VOLT_08_07 "CELL_08 Voltage";
BA_ "FlexKomIsMotorola" SG_ 1651 CELL_VOLT_08_07 1;
BA_ "GenSigSendType" SG_ 1651 CELL_VOLT_07_07 0;
BA_ "GenSigCycleTime" SG_ 1651 CELL_VOLT_07_07 40;
BA_ "FlexKomSigStartValue" SG_ 1651 CELL_VOLT_07_07 "0000h";
BA_ "GenSigTimeout_BMU" SG_ 1651 CELL_VOLT_07_07 220;
BA_ "FlexKomSID" SG_ 1651 CELL_VOLT_07_07 1189;
BA_ "FlexKomSigStartPos" SG_ 1651 CELL_VOLT_07_07 39;
BA_ "FlexKomSigLaenge" SG_ 1651 CELL_VOLT_07_07 16;
BA_ "FlexKomSigName" SG_ 1651 CELL_VOLT_07_07 "CELL_VOLT_07_07";
BA_ "FlexKomComment" SG_ 1651 CELL_VOLT_07_07 "CELL_07 Voltage";
BA_ "FlexKomIsMotorola" SG_ 1651 CELL_VOLT_07_07 1;
BA_ "GenSigSendType" SG_ 1651 CELL_VOLT_06_07 0;
BA_ "GenSigCycleTime" SG_ 1651 CELL_VOLT_06_07 40;
BA_ "FlexKomSigStartValue" SG_ 1651 CELL_VOLT_06_07 "0000h";
BA_ "GenSigTimeout_BMU" SG_ 1651 CELL_VOLT_06_07 220;
BA_ "FlexKomSID" SG_ 1651 CELL_VOLT_06_07 1177;
BA_ "FlexKomSigStartPos" SG_ 1651 CELL_VOLT_06_07 23;
BA_ "FlexKomSigLaenge" SG_ 1651 CELL_VOLT_06_07 16;
BA_ "FlexKomSigName" SG_ 1651 CELL_VOLT_06_07 "CELL_VOLT_06_07";
BA_ "FlexKomComment" SG_ 1651 CELL_VOLT_06_07 "CELL_06 Voltage";
BA_ "FlexKomIsMotorola" SG_ 1651 CELL_VOLT_06_07 1;
BA_ "GenSigSendType" SG_ 1651 CELL_VOLT_05_07 0;
BA_ "GenSigCycleTime" SG_ 1651 CELL_VOLT_05_07 40;
BA_ "FlexKomSigStartValue" SG_ 1651 CELL_VOLT_05_07 "0000h";
BA_ "GenSigTimeout_BMU" SG_ 1651 CELL_VOLT_05_07 220;
BA_ "FlexKomSID" SG_ 1651 CELL_VOLT_05_07 1165;
BA_ "FlexKomSigStartPos" SG_ 1651 CELL_VOLT_05_07 7;
BA_ "FlexKomSigLaenge" SG_ 1651 CELL_VOLT_05_07 16;
BA_ "FlexKomSigName" SG_ 1651 CELL_VOLT_05_07 "CELL_VOLT_05_07";
BA_ "FlexKomComment" SG_ 1651 CELL_VOLT_05_07 "CELL_05 Voltage";
BA_ "FlexKomIsMotorola" SG_ 1651 CELL_VOLT_05_07 1;
BA_ "GenSigSendType" SG_ 1635 CELL_VOLT_08_06 0;
BA_ "GenSigCycleTime" SG_ 1635 CELL_VOLT_08_06 40;
BA_ "FlexKomSigStartValue" SG_ 1635 CELL_VOLT_08_06 "0000h";
BA_ "GenSigTimeout_BMU" SG_ 1635 CELL_VOLT_08_06 220;
BA_ "FlexKomSID" SG_ 1635 CELL_VOLT_08_06 1200;
BA_ "FlexKomSigStartPos" SG_ 1635 CELL_VOLT_08_06 55;
BA_ "FlexKomSigLaenge" SG_ 1635 CELL_VOLT_08_06 16;
BA_ "FlexKomSigName" SG_ 1635 CELL_VOLT_08_06 "CELL_VOLT_08_06";
BA_ "FlexKomComment" SG_ 1635 CELL_VOLT_08_06 "CELL_08 Voltage";
BA_ "FlexKomIsMotorola" SG_ 1635 CELL_VOLT_08_06 1;
BA_ "GenSigSendType" SG_ 1635 CELL_VOLT_07_06 0;
BA_ "GenSigCycleTime" SG_ 1635 CELL_VOLT_07_06 40;
BA_ "FlexKomSigStartValue" SG_ 1635 CELL_VOLT_07_06 "0000h";
BA_ "GenSigTimeout_BMU" SG_ 1635 CELL_VOLT_07_06 220;
BA_ "FlexKomSID" SG_ 1635 CELL_VOLT_07_06 1188;
BA_ "FlexKomSigStartPos" SG_ 1635 CELL_VOLT_07_06 39;
BA_ "FlexKomSigLaenge" SG_ 1635 CELL_VOLT_07_06 16;
BA_ "FlexKomSigName" SG_ 1635 CELL_VOLT_07_06 "CELL_VOLT_07_06";
BA_ "FlexKomComment" SG_ 1635 CELL_VOLT_07_06 "CELL_07 Voltage";
BA_ "FlexKomIsMotorola" SG_ 1635 CELL_VOLT_07_06 1;
BA_ "GenSigSendType" SG_ 1635 CELL_VOLT_06_06 0;
BA_ "GenSigCycleTime" SG_ 1635 CELL_VOLT_06_06 40;
BA_ "FlexKomSigStartValue" SG_ 1635 CELL_VOLT_06_06 "0000h";
BA_ "GenSigTimeout_BMU" SG_ 1635 CELL_VOLT_06_06 220;
BA_ "FlexKomSID" SG_ 1635 CELL_VOLT_06_06 1176;
BA_ "FlexKomSigStartPos" SG_ 1635 CELL_VOLT_06_06 23;
BA_ "FlexKomSigLaenge" SG_ 1635 CELL_VOLT_06_06 16;
BA_ "FlexKomSigName" SG_ 1635 CELL_VOLT_06_06 "CELL_VOLT_06_06";
BA_ "FlexKomComment" SG_ 1635 CELL_VOLT_06_06 "CELL_06 Voltage";
BA_ "FlexKomIsMotorola" SG_ 1635 CELL_VOLT_06_06 1;
BA_ "GenSigSendType" SG_ 1635 CELL_VOLT_05_06 0;
BA_ "GenSigCycleTime" SG_ 1635 CELL_VOLT_05_06 40;
BA_ "FlexKomSigStartValue" SG_ 1635 CELL_VOLT_05_06 "0000h";
BA_ "GenSigTimeout_BMU" SG_ 1635 CELL_VOLT_05_06 220;
BA_ "FlexKomSID" SG_ 1635 CELL_VOLT_05_06 1164;
BA_ "FlexKomSigStartPos" SG_ 1635 CELL_VOLT_05_06 7;
BA_ "FlexKomSigLaenge" SG_ 1635 CELL_VOLT_05_06 16;
BA_ "FlexKomSigName" SG_ 1635 CELL_VOLT_05_06 "CELL_VOLT_05_06";
BA_ "FlexKomComment" SG_ 1635 CELL_VOLT_05_06 "CELL_05 Voltage";
BA_ "FlexKomIsMotorola" SG_ 1635 CELL_VOLT_05_06 1;
BA_ "GenSigSendType" SG_ 1619 CELL_VOLT_08_05 0;
BA_ "GenSigCycleTime" SG_ 1619 CELL_VOLT_08_05 40;
BA_ "FlexKomSigStartValue" SG_ 1619 CELL_VOLT_08_05 "0000h";
BA_ "GenSigTimeout_BMU" SG_ 1619 CELL_VOLT_08_05 220;
BA_ "FlexKomSID" SG_ 1619 CELL_VOLT_08_05 1199;
BA_ "FlexKomSigStartPos" SG_ 1619 CELL_VOLT_08_05 55;
BA_ "FlexKomSigLaenge" SG_ 1619 CELL_VOLT_08_05 16;
BA_ "FlexKomSigName" SG_ 1619 CELL_VOLT_08_05 "CELL_VOLT_08_05";
BA_ "FlexKomComment" SG_ 1619 CELL_VOLT_08_05 "CELL_08 Voltage";
BA_ "FlexKomIsMotorola" SG_ 1619 CELL_VOLT_08_05 1;
BA_ "GenSigSendType" SG_ 1619 CELL_VOLT_07_05 0;
BA_ "GenSigCycleTime" SG_ 1619 CELL_VOLT_07_05 40;
BA_ "FlexKomSigStartValue" SG_ 1619 CELL_VOLT_07_05 "0000h";
BA_ "GenSigTimeout_BMU" SG_ 1619 CELL_VOLT_07_05 220;
BA_ "FlexKomSID" SG_ 1619 CELL_VOLT_07_05 1187;
BA_ "FlexKomSigStartPos" SG_ 1619 CELL_VOLT_07_05 39;
BA_ "FlexKomSigLaenge" SG_ 1619 CELL_VOLT_07_05 16;
BA_ "FlexKomSigName" SG_ 1619 CELL_VOLT_07_05 "CELL_VOLT_07_05";
BA_ "FlexKomComment" SG_ 1619 CELL_VOLT_07_05 "CELL_07 Voltage";
BA_ "FlexKomIsMotorola" SG_ 1619 CELL_VOLT_07_05 1;
BA_ "GenSigSendType" SG_ 1619 CELL_VOLT_06_05 0;
BA_ "GenSigCycleTime" SG_ 1619 CELL_VOLT_06_05 40;
BA_ "FlexKomSigStartValue" SG_ 1619 CELL_VOLT_06_05 "0000h";
BA_ "GenSigTimeout_BMU" SG_ 1619 CELL_VOLT_06_05 220;
BA_ "FlexKomSID" SG_ 1619 CELL_VOLT_06_05 1175;
BA_ "FlexKomSigStartPos" SG_ 1619 CELL_VOLT_06_05 23;
BA_ "FlexKomSigLaenge" SG_ 1619 CELL_VOLT_06_05 16;
BA_ "FlexKomSigName" SG_ 1619 CELL_VOLT_06_05 "CELL_VOLT_06_05";
BA_ "FlexKomComment" SG_ 1619 CELL_VOLT_06_05 "CELL_06 Voltage";
BA_ "FlexKomIsMotorola" SG_ 1619 CELL_VOLT_06_05 1;
BA_ "GenSigSendType" SG_ 1619 CELL_VOLT_05_05 0;
BA_ "GenSigCycleTime" SG_ 1619 CELL_VOLT_05_05 40;
BA_ "FlexKomSigStartValue" SG_ 1619 CELL_VOLT_05_05 "0000h";
BA_ "GenSigTimeout_BMU" SG_ 1619 CELL_VOLT_05_05 220;
BA_ "FlexKomSID" SG_ 1619 CELL_VOLT_05_05 1163;
BA_ "FlexKomSigStartPos" SG_ 1619 CELL_VOLT_05_05 7;
BA_ "FlexKomSigLaenge" SG_ 1619 CELL_VOLT_05_05 16;
BA_ "FlexKomSigName" SG_ 1619 CELL_VOLT_05_05 "CELL_VOLT_05_05";
BA_ "FlexKomComment" SG_ 1619 CELL_VOLT_05_05 "CELL_05 Voltage";
BA_ "FlexKomIsMotorola" SG_ 1619 CELL_VOLT_05_05 1;
BA_ "GenSigSendType" SG_ 1603 CELL_VOLT_08_04 0;
BA_ "GenSigCycleTime" SG_ 1603 CELL_VOLT_08_04 40;
BA_ "FlexKomSigStartValue" SG_ 1603 CELL_VOLT_08_04 "0000h";
BA_ "GenSigTimeout_BMU" SG_ 1603 CELL_VOLT_08_04 220;
BA_ "FlexKomSID" SG_ 1603 CELL_VOLT_08_04 1198;
BA_ "FlexKomSigStartPos" SG_ 1603 CELL_VOLT_08_04 55;
BA_ "FlexKomSigLaenge" SG_ 1603 CELL_VOLT_08_04 16;
BA_ "FlexKomSigName" SG_ 1603 CELL_VOLT_08_04 "CELL_VOLT_08_04";
BA_ "FlexKomComment" SG_ 1603 CELL_VOLT_08_04 "CELL_08 Voltage";
BA_ "FlexKomIsMotorola" SG_ 1603 CELL_VOLT_08_04 1;
BA_ "GenSigSendType" SG_ 1603 CELL_VOLT_07_04 0;
BA_ "GenSigCycleTime" SG_ 1603 CELL_VOLT_07_04 40;
BA_ "FlexKomSigStartValue" SG_ 1603 CELL_VOLT_07_04 "0000h";
BA_ "GenSigTimeout_BMU" SG_ 1603 CELL_VOLT_07_04 220;
BA_ "FlexKomSID" SG_ 1603 CELL_VOLT_07_04 1186;
BA_ "FlexKomSigStartPos" SG_ 1603 CELL_VOLT_07_04 39;
BA_ "FlexKomSigLaenge" SG_ 1603 CELL_VOLT_07_04 16;
BA_ "FlexKomSigName" SG_ 1603 CELL_VOLT_07_04 "CELL_VOLT_07_04";
BA_ "FlexKomComment" SG_ 1603 CELL_VOLT_07_04 "CELL_07 Voltage";
BA_ "FlexKomIsMotorola" SG_ 1603 CELL_VOLT_07_04 1;
BA_ "GenSigSendType" SG_ 1603 CELL_VOLT_06_04 0;
BA_ "GenSigCycleTime" SG_ 1603 CELL_VOLT_06_04 40;
BA_ "FlexKomSigStartValue" SG_ 1603 CELL_VOLT_06_04 "0000h";
BA_ "GenSigTimeout_BMU" SG_ 1603 CELL_VOLT_06_04 220;
BA_ "FlexKomSID" SG_ 1603 CELL_VOLT_06_04 1174;
BA_ "FlexKomSigStartPos" SG_ 1603 CELL_VOLT_06_04 23;
BA_ "FlexKomSigLaenge" SG_ 1603 CELL_VOLT_06_04 16;
BA_ "FlexKomSigName" SG_ 1603 CELL_VOLT_06_04 "CELL_VOLT_06_04";
BA_ "FlexKomComment" SG_ 1603 CELL_VOLT_06_04 "CELL_06 Voltage";
BA_ "FlexKomIsMotorola" SG_ 1603 CELL_VOLT_06_04 1;
BA_ "GenSigSendType" SG_ 1603 CELL_VOLT_05_04 0;
BA_ "GenSigCycleTime" SG_ 1603 CELL_VOLT_05_04 40;
BA_ "FlexKomSigStartValue" SG_ 1603 CELL_VOLT_05_04 "0000h";
BA_ "GenSigTimeout_BMU" SG_ 1603 CELL_VOLT_05_04 220;
BA_ "FlexKomSID" SG_ 1603 CELL_VOLT_05_04 1162;
BA_ "FlexKomSigStartPos" SG_ 1603 CELL_VOLT_05_04 7;
BA_ "FlexKomSigLaenge" SG_ 1603 CELL_VOLT_05_04 16;
BA_ "FlexKomSigName" SG_ 1603 CELL_VOLT_05_04 "CELL_VOLT_05_04";
BA_ "FlexKomComment" SG_ 1603 CELL_VOLT_05_04 "CELL_05 Voltage";
BA_ "FlexKomIsMotorola" SG_ 1603 CELL_VOLT_05_04 1;
BA_ "GenSigSendType" SG_ 1587 CELL_VOLT_08_03 0;
BA_ "GenSigCycleTime" SG_ 1587 CELL_VOLT_08_03 40;
BA_ "FlexKomSigStartValue" SG_ 1587 CELL_VOLT_08_03 "0000h";
BA_ "GenSigTimeout_BMU" SG_ 1587 CELL_VOLT_08_03 220;
BA_ "FlexKomSID" SG_ 1587 CELL_VOLT_08_03 1197;
BA_ "FlexKomSigStartPos" SG_ 1587 CELL_VOLT_08_03 55;
BA_ "FlexKomSigLaenge" SG_ 1587 CELL_VOLT_08_03 16;
BA_ "FlexKomSigName" SG_ 1587 CELL_VOLT_08_03 "CELL_VOLT_08_03";
BA_ "FlexKomComment" SG_ 1587 CELL_VOLT_08_03 "CELL_08 Voltage";
BA_ "FlexKomIsMotorola" SG_ 1587 CELL_VOLT_08_03 1;
BA_ "GenSigSendType" SG_ 1587 CELL_VOLT_07_03 0;
BA_ "GenSigCycleTime" SG_ 1587 CELL_VOLT_07_03 40;
BA_ "FlexKomSigStartValue" SG_ 1587 CELL_VOLT_07_03 "0000h";
BA_ "GenSigTimeout_BMU" SG_ 1587 CELL_VOLT_07_03 220;
BA_ "FlexKomSID" SG_ 1587 CELL_VOLT_07_03 1185;
BA_ "FlexKomSigStartPos" SG_ 1587 CELL_VOLT_07_03 39;
BA_ "FlexKomSigLaenge" SG_ 1587 CELL_VOLT_07_03 16;
BA_ "FlexKomSigName" SG_ 1587 CELL_VOLT_07_03 "CELL_VOLT_07_03";
BA_ "FlexKomComment" SG_ 1587 CELL_VOLT_07_03 "CELL_07 Voltage";
BA_ "FlexKomIsMotorola" SG_ 1587 CELL_VOLT_07_03 1;
BA_ "GenSigSendType" SG_ 1587 CELL_VOLT_06_03 0;
BA_ "GenSigCycleTime" SG_ 1587 CELL_VOLT_06_03 40;
BA_ "FlexKomSigStartValue" SG_ 1587 CELL_VOLT_06_03 "0000h";
BA_ "GenSigTimeout_BMU" SG_ 1587 CELL_VOLT_06_03 220;
BA_ "FlexKomSID" SG_ 1587 CELL_VOLT_06_03 1173;
BA_ "FlexKomSigStartPos" SG_ 1587 CELL_VOLT_06_03 23;
BA_ "FlexKomSigLaenge" SG_ 1587 CELL_VOLT_06_03 16;
BA_ "FlexKomSigName" SG_ 1587 CELL_VOLT_06_03 "CELL_VOLT_06_03";
BA_ "FlexKomComment" SG_ 1587 CELL_VOLT_06_03 "CELL_06 Voltage";
BA_ "FlexKomIsMotorola" SG_ 1587 CELL_VOLT_06_03 1;
BA_ "GenSigSendType" SG_ 1587 CELL_VOLT_05_03 0;
BA_ "GenSigCycleTime" SG_ 1587 CELL_VOLT_05_03 40;
BA_ "FlexKomSigStartValue" SG_ 1587 CELL_VOLT_05_03 "0000h";
BA_ "GenSigTimeout_BMU" SG_ 1587 CELL_VOLT_05_03 220;
BA_ "FlexKomSID" SG_ 1587 CELL_VOLT_05_03 1161;
BA_ "FlexKomSigStartPos" SG_ 1587 CELL_VOLT_05_03 7;
BA_ "FlexKomSigLaenge" SG_ 1587 CELL_VOLT_05_03 16;
BA_ "FlexKomSigName" SG_ 1587 CELL_VOLT_05_03 "CELL_VOLT_05_03";
BA_ "FlexKomComment" SG_ 1587 CELL_VOLT_05_03 "CELL_05 Voltage";
BA_ "FlexKomIsMotorola" SG_ 1587 CELL_VOLT_05_03 1;
BA_ "GenSigSendType" SG_ 1571 CELL_VOLT_08_02 0;
BA_ "GenSigCycleTime" SG_ 1571 CELL_VOLT_08_02 40;
BA_ "FlexKomSigStartValue" SG_ 1571 CELL_VOLT_08_02 "0000h";
BA_ "GenSigTimeout_BMU" SG_ 1571 CELL_VOLT_08_02 220;
BA_ "FlexKomSID" SG_ 1571 CELL_VOLT_08_02 1196;
BA_ "FlexKomSigStartPos" SG_ 1571 CELL_VOLT_08_02 55;
BA_ "FlexKomSigLaenge" SG_ 1571 CELL_VOLT_08_02 16;
BA_ "FlexKomSigName" SG_ 1571 CELL_VOLT_08_02 "CELL_VOLT_08_02";
BA_ "FlexKomComment" SG_ 1571 CELL_VOLT_08_02 "CELL_08 Voltage";
BA_ "FlexKomIsMotorola" SG_ 1571 CELL_VOLT_08_02 1;
BA_ "GenSigSendType" SG_ 1571 CELL_VOLT_07_02 0;
BA_ "GenSigCycleTime" SG_ 1571 CELL_VOLT_07_02 40;
BA_ "FlexKomSigStartValue" SG_ 1571 CELL_VOLT_07_02 "0000h";
BA_ "GenSigTimeout_BMU" SG_ 1571 CELL_VOLT_07_02 220;
BA_ "FlexKomSID" SG_ 1571 CELL_VOLT_07_02 1183;
BA_ "FlexKomSigStartPos" SG_ 1571 CELL_VOLT_07_02 39;
BA_ "FlexKomSigLaenge" SG_ 1571 CELL_VOLT_07_02 16;
BA_ "FlexKomSigName" SG_ 1571 CELL_VOLT_07_02 "CELL_VOLT_07_02";
BA_ "FlexKomComment" SG_ 1571 CELL_VOLT_07_02 "CELL_07 Voltage";
BA_ "FlexKomIsMotorola" SG_ 1571 CELL_VOLT_07_02 1;
BA_ "GenSigSendType" SG_ 1571 CELL_VOLT_06_02 0;
BA_ "GenSigCycleTime" SG_ 1571 CELL_VOLT_06_02 40;
BA_ "FlexKomSigStartValue" SG_ 1571 CELL_VOLT_06_02 "0000h";
BA_ "GenSigTimeout_BMU" SG_ 1571 CELL_VOLT_06_02 220;
BA_ "FlexKomSID" SG_ 1571 CELL_VOLT_06_02 1172;
BA_ "FlexKomSigStartPos" SG_ 1571 CELL_VOLT_06_02 23;
BA_ "FlexKomSigLaenge" SG_ 1571 CELL_VOLT_06_02 16;
BA_ "FlexKomSigName" SG_ 1571 CELL_VOLT_06_02 "CELL_VOLT_06_02";
BA_ "FlexKomComment" SG_ 1571 CELL_VOLT_06_02 "CELL_06 Voltage";
BA_ "FlexKomIsMotorola" SG_ 1571 CELL_VOLT_06_02 1;
BA_ "GenSigSendType" SG_ 1571 CELL_VOLT_05_02 0;
BA_ "GenSigCycleTime" SG_ 1571 CELL_VOLT_05_02 40;
BA_ "FlexKomSigStartValue" SG_ 1571 CELL_VOLT_05_02 "0000h";
BA_ "GenSigTimeout_BMU" SG_ 1571 CELL_VOLT_05_02 220;
BA_ "FlexKomSID" SG_ 1571 CELL_VOLT_05_02 1160;
BA_ "FlexKomSigStartPos" SG_ 1571 CELL_VOLT_05_02 7;
BA_ "FlexKomSigLaenge" SG_ 1571 CELL_VOLT_05_02 16;
BA_ "FlexKomSigName" SG_ 1571 CELL_VOLT_05_02 "CELL_VOLT_05_02";
BA_ "FlexKomComment" SG_ 1571 CELL_VOLT_05_02 "CELL_05 Voltage";
BA_ "FlexKomIsMotorola" SG_ 1571 CELL_VOLT_05_02 1;
BA_ "GenSigSendType" SG_ 1555 CELL_VOLT_08_01 0;
BA_ "GenSigCycleTime" SG_ 1555 CELL_VOLT_08_01 40;
BA_ "FlexKomSigStartValue" SG_ 1555 CELL_VOLT_08_01 "0000h";
BA_ "GenSigTimeout_BMU" SG_ 1555 CELL_VOLT_08_01 220;
BA_ "FlexKomSID" SG_ 1555 CELL_VOLT_08_01 1195;
BA_ "FlexKomSigStartPos" SG_ 1555 CELL_VOLT_08_01 55;
BA_ "FlexKomSigLaenge" SG_ 1555 CELL_VOLT_08_01 16;
BA_ "FlexKomSigName" SG_ 1555 CELL_VOLT_08_01 "CELL_VOLT_08_01";
BA_ "FlexKomComment" SG_ 1555 CELL_VOLT_08_01 "CELL_08 Voltage";
BA_ "FlexKomIsMotorola" SG_ 1555 CELL_VOLT_08_01 1;
BA_ "GenSigSendType" SG_ 1555 CELL_VOLT_07_01 0;
BA_ "GenSigCycleTime" SG_ 1555 CELL_VOLT_07_01 40;
BA_ "FlexKomSigStartValue" SG_ 1555 CELL_VOLT_07_01 "0000h";
BA_ "GenSigTimeout_BMU" SG_ 1555 CELL_VOLT_07_01 220;
BA_ "FlexKomSID" SG_ 1555 CELL_VOLT_07_01 1184;
BA_ "FlexKomSigStartPos" SG_ 1555 CELL_VOLT_07_01 39;
BA_ "FlexKomSigLaenge" SG_ 1555 CELL_VOLT_07_01 16;
BA_ "FlexKomSigName" SG_ 1555 CELL_VOLT_07_01 "CELL_VOLT_07_01";
BA_ "FlexKomComment" SG_ 1555 CELL_VOLT_07_01 "CELL_07 Voltage";
BA_ "FlexKomIsMotorola" SG_ 1555 CELL_VOLT_07_01 1;
BA_ "GenSigSendType" SG_ 1555 CELL_VOLT_06_01 0;
BA_ "GenSigCycleTime" SG_ 1555 CELL_VOLT_06_01 40;
BA_ "FlexKomSigStartValue" SG_ 1555 CELL_VOLT_06_01 "0000h";
BA_ "GenSigTimeout_BMU" SG_ 1555 CELL_VOLT_06_01 220;
BA_ "FlexKomSID" SG_ 1555 CELL_VOLT_06_01 1171;
BA_ "FlexKomSigStartPos" SG_ 1555 CELL_VOLT_06_01 23;
BA_ "FlexKomSigLaenge" SG_ 1555 CELL_VOLT_06_01 16;
BA_ "FlexKomSigName" SG_ 1555 CELL_VOLT_06_01 "CELL_VOLT_06_01";
BA_ "FlexKomComment" SG_ 1555 CELL_VOLT_06_01 "CELL_06 Voltage";
BA_ "FlexKomIsMotorola" SG_ 1555 CELL_VOLT_06_01 1;
BA_ "GenSigSendType" SG_ 1555 CELL_VOLT_05_01 0;
BA_ "GenSigCycleTime" SG_ 1555 CELL_VOLT_05_01 40;
BA_ "FlexKomSigStartValue" SG_ 1555 CELL_VOLT_05_01 "0000h";
BA_ "GenSigTimeout_BMU" SG_ 1555 CELL_VOLT_05_01 220;
BA_ "FlexKomSID" SG_ 1555 CELL_VOLT_05_01 1159;
BA_ "FlexKomSigStartPos" SG_ 1555 CELL_VOLT_05_01 7;
BA_ "FlexKomSigLaenge" SG_ 1555 CELL_VOLT_05_01 16;
BA_ "FlexKomSigName" SG_ 1555 CELL_VOLT_05_01 "CELL_VOLT_05_01";
BA_ "FlexKomComment" SG_ 1555 CELL_VOLT_05_01 "CELL_05 Voltage";
BA_ "FlexKomIsMotorola" SG_ 1555 CELL_VOLT_05_01 1;
BA_ "GenSigSendType" SG_ 1730 CELL_VOLT_04_12 0;
BA_ "GenSigCycleTime" SG_ 1730 CELL_VOLT_04_12 40;
BA_ "FlexKomSigStartValue" SG_ 1730 CELL_VOLT_04_12 "0000h";
BA_ "GenSigTimeout_BMU" SG_ 1730 CELL_VOLT_04_12 220;
BA_ "FlexKomSID" SG_ 1730 CELL_VOLT_04_12 1158;
BA_ "FlexKomSigStartPos" SG_ 1730 CELL_VOLT_04_12 55;
BA_ "FlexKomSigLaenge" SG_ 1730 CELL_VOLT_04_12 16;
BA_ "FlexKomSigName" SG_ 1730 CELL_VOLT_04_12 "CELL_VOLT_04_12";
BA_ "FlexKomComment" SG_ 1730 CELL_VOLT_04_12 "CELL_04 Voltage";
BA_ "FlexKomIsMotorola" SG_ 1730 CELL_VOLT_04_12 1;
BA_ "GenSigSendType" SG_ 1730 CELL_VOLT_03_12 0;
BA_ "GenSigCycleTime" SG_ 1730 CELL_VOLT_03_12 40;
BA_ "FlexKomSigStartValue" SG_ 1730 CELL_VOLT_03_12 "0000h";
BA_ "GenSigTimeout_BMU" SG_ 1730 CELL_VOLT_03_12 220;
BA_ "FlexKomSID" SG_ 1730 CELL_VOLT_03_12 1146;
BA_ "FlexKomSigStartPos" SG_ 1730 CELL_VOLT_03_12 39;
BA_ "FlexKomSigLaenge" SG_ 1730 CELL_VOLT_03_12 16;
BA_ "FlexKomSigName" SG_ 1730 CELL_VOLT_03_12 "CELL_VOLT_03_12";
BA_ "FlexKomComment" SG_ 1730 CELL_VOLT_03_12 "CELL_03 Voltage";
BA_ "FlexKomIsMotorola" SG_ 1730 CELL_VOLT_03_12 1;
BA_ "GenSigSendType" SG_ 1730 CELL_VOLT_02_12 0;
BA_ "GenSigCycleTime" SG_ 1730 CELL_VOLT_02_12 40;
BA_ "FlexKomSigStartValue" SG_ 1730 CELL_VOLT_02_12 "0000h";
BA_ "GenSigTimeout_BMU" SG_ 1730 CELL_VOLT_02_12 220;
BA_ "FlexKomSID" SG_ 1730 CELL_VOLT_02_12 1134;
BA_ "FlexKomSigStartPos" SG_ 1730 CELL_VOLT_02_12 23;
BA_ "FlexKomSigLaenge" SG_ 1730 CELL_VOLT_02_12 16;
BA_ "FlexKomSigName" SG_ 1730 CELL_VOLT_02_12 "CELL_VOLT_02_12";
BA_ "FlexKomComment" SG_ 1730 CELL_VOLT_02_12 "CELL_02 Voltage";
BA_ "FlexKomIsMotorola" SG_ 1730 CELL_VOLT_02_12 1;
BA_ "GenSigSendType" SG_ 1730 CELL_VOLT_01_12 0;
BA_ "GenSigCycleTime" SG_ 1730 CELL_VOLT_01_12 40;
BA_ "FlexKomSigStartValue" SG_ 1730 CELL_VOLT_01_12 "0000h";
BA_ "GenSigTimeout_BMU" SG_ 1730 CELL_VOLT_01_12 220;
BA_ "FlexKomSID" SG_ 1730 CELL_VOLT_01_12 1122;
BA_ "FlexKomSigStartPos" SG_ 1730 CELL_VOLT_01_12 7;
BA_ "FlexKomSigLaenge" SG_ 1730 CELL_VOLT_01_12 16;
BA_ "FlexKomSigName" SG_ 1730 CELL_VOLT_01_12 "CELL_VOLT_01_12";
BA_ "FlexKomComment" SG_ 1730 CELL_VOLT_01_12 "CELL_01 Voltage";
BA_ "FlexKomIsMotorola" SG_ 1730 CELL_VOLT_01_12 1;
BA_ "GenSigSendType" SG_ 1714 CELL_VOLT_04_11 0;
BA_ "GenSigCycleTime" SG_ 1714 CELL_VOLT_04_11 40;
BA_ "FlexKomSigStartValue" SG_ 1714 CELL_VOLT_04_11 "0000h";
BA_ "GenSigTimeout_BMU" SG_ 1714 CELL_VOLT_04_11 220;
BA_ "FlexKomSID" SG_ 1714 CELL_VOLT_04_11 1157;
BA_ "FlexKomSigStartPos" SG_ 1714 CELL_VOLT_04_11 55;
BA_ "FlexKomSigLaenge" SG_ 1714 CELL_VOLT_04_11 16;
BA_ "FlexKomSigName" SG_ 1714 CELL_VOLT_04_11 "CELL_VOLT_04_11";
BA_ "FlexKomComment" SG_ 1714 CELL_VOLT_04_11 "CELL_04 Voltage";
BA_ "FlexKomIsMotorola" SG_ 1714 CELL_VOLT_04_11 1;
BA_ "GenSigSendType" SG_ 1714 CELL_VOLT_03_11 0;
BA_ "GenSigCycleTime" SG_ 1714 CELL_VOLT_03_11 40;
BA_ "FlexKomSigStartValue" SG_ 1714 CELL_VOLT_03_11 "0000h";
BA_ "GenSigTimeout_BMU" SG_ 1714 CELL_VOLT_03_11 220;
BA_ "FlexKomSID" SG_ 1714 CELL_VOLT_03_11 1145;
BA_ "FlexKomSigStartPos" SG_ 1714 CELL_VOLT_03_11 39;
BA_ "FlexKomSigLaenge" SG_ 1714 CELL_VOLT_03_11 16;
BA_ "FlexKomSigName" SG_ 1714 CELL_VOLT_03_11 "CELL_VOLT_03_11";
BA_ "FlexKomComment" SG_ 1714 CELL_VOLT_03_11 "CELL_03 Voltage";
BA_ "FlexKomIsMotorola" SG_ 1714 CELL_VOLT_03_11 1;
BA_ "GenSigSendType" SG_ 1714 CELL_VOLT_02_11 0;
BA_ "GenSigCycleTime" SG_ 1714 CELL_VOLT_02_11 40;
BA_ "FlexKomSigStartValue" SG_ 1714 CELL_VOLT_02_11 "0000h";
BA_ "GenSigTimeout_BMU" SG_ 1714 CELL_VOLT_02_11 220;
BA_ "FlexKomSID" SG_ 1714 CELL_VOLT_02_11 1133;
BA_ "FlexKomSigStartPos" SG_ 1714 CELL_VOLT_02_11 23;
BA_ "FlexKomSigLaenge" SG_ 1714 CELL_VOLT_02_11 16;
BA_ "FlexKomSigName" SG_ 1714 CELL_VOLT_02_11 "CELL_VOLT_02_11";
BA_ "FlexKomComment" SG_ 1714 CELL_VOLT_02_11 "CELL_02 Voltage";
BA_ "FlexKomIsMotorola" SG_ 1714 CELL_VOLT_02_11 1;
BA_ "GenSigSendType" SG_ 1714 CELL_VOLT_01_11 0;
BA_ "GenSigCycleTime" SG_ 1714 CELL_VOLT_01_11 40;
BA_ "FlexKomSigStartValue" SG_ 1714 CELL_VOLT_01_11 "0000h";
BA_ "GenSigTimeout_BMU" SG_ 1714 CELL_VOLT_01_11 220;
BA_ "FlexKomSID" SG_ 1714 CELL_VOLT_01_11 1121;
BA_ "FlexKomSigStartPos" SG_ 1714 CELL_VOLT_01_11 7;
BA_ "FlexKomSigLaenge" SG_ 1714 CELL_VOLT_01_11 16;
BA_ "FlexKomSigName" SG_ 1714 CELL_VOLT_01_11 "CELL_VOLT_01_11";
BA_ "FlexKomComment" SG_ 1714 CELL_VOLT_01_11 "CELL_01 Voltage";
BA_ "FlexKomIsMotorola" SG_ 1714 CELL_VOLT_01_11 1;
BA_ "GenSigSendType" SG_ 1698 CELL_VOLT_04_10 0;
BA_ "GenSigCycleTime" SG_ 1698 CELL_VOLT_04_10 40;
BA_ "FlexKomSigStartValue" SG_ 1698 CELL_VOLT_04_10 "0000h";
BA_ "GenSigTimeout_BMU" SG_ 1698 CELL_VOLT_04_10 220;
BA_ "FlexKomSID" SG_ 1698 CELL_VOLT_04_10 1156;
BA_ "FlexKomSigStartPos" SG_ 1698 CELL_VOLT_04_10 55;
BA_ "FlexKomSigLaenge" SG_ 1698 CELL_VOLT_04_10 16;
BA_ "FlexKomSigName" SG_ 1698 CELL_VOLT_04_10 "CELL_VOLT_04_10";
BA_ "FlexKomComment" SG_ 1698 CELL_VOLT_04_10 "CELL_04 Voltage";
BA_ "FlexKomIsMotorola" SG_ 1698 CELL_VOLT_04_10 1;
BA_ "GenSigSendType" SG_ 1698 CELL_VOLT_03_10 0;
BA_ "GenSigCycleTime" SG_ 1698 CELL_VOLT_03_10 40;
BA_ "FlexKomSigStartValue" SG_ 1698 CELL_VOLT_03_10 "0000h";
BA_ "GenSigTimeout_BMU" SG_ 1698 CELL_VOLT_03_10 220;
BA_ "FlexKomSID" SG_ 1698 CELL_VOLT_03_10 1144;
BA_ "FlexKomSigStartPos" SG_ 1698 CELL_VOLT_03_10 39;
BA_ "FlexKomSigLaenge" SG_ 1698 CELL_VOLT_03_10 16;
BA_ "FlexKomSigName" SG_ 1698 CELL_VOLT_03_10 "CELL_VOLT_03_10";
BA_ "FlexKomComment" SG_ 1698 CELL_VOLT_03_10 "CELL_03 Voltage";
BA_ "FlexKomIsMotorola" SG_ 1698 CELL_VOLT_03_10 1;
BA_ "GenSigSendType" SG_ 1698 CELL_VOLT_02_10 0;
BA_ "GenSigCycleTime" SG_ 1698 CELL_VOLT_02_10 40;
BA_ "FlexKomSigStartValue" SG_ 1698 CELL_VOLT_02_10 "0000h";
BA_ "GenSigTimeout_BMU" SG_ 1698 CELL_VOLT_02_10 220;
BA_ "FlexKomSID" SG_ 1698 CELL_VOLT_02_10 1132;
BA_ "FlexKomSigStartPos" SG_ 1698 CELL_VOLT_02_10 23;
BA_ "FlexKomSigLaenge" SG_ 1698 CELL_VOLT_02_10 16;
BA_ "FlexKomSigName" SG_ 1698 CELL_VOLT_02_10 "CELL_VOLT_02_10";
BA_ "FlexKomComment" SG_ 1698 CELL_VOLT_02_10 "CELL_02 Voltage";
BA_ "FlexKomIsMotorola" SG_ 1698 CELL_VOLT_02_10 1;
BA_ "GenSigSendType" SG_ 1698 CELL_VOLT_01_10 0;
BA_ "GenSigCycleTime" SG_ 1698 CELL_VOLT_01_10 40;
BA_ "FlexKomSigStartValue" SG_ 1698 CELL_VOLT_01_10 "0000h";
BA_ "GenSigTimeout_BMU" SG_ 1698 CELL_VOLT_01_10 220;
BA_ "FlexKomSID" SG_ 1698 CELL_VOLT_01_10 1120;
BA_ "FlexKomSigStartPos" SG_ 1698 CELL_VOLT_01_10 7;
BA_ "FlexKomSigLaenge" SG_ 1698 CELL_VOLT_01_10 16;
BA_ "FlexKomSigName" SG_ 1698 CELL_VOLT_01_10 "CELL_VOLT_01_10";
BA_ "FlexKomComment" SG_ 1698 CELL_VOLT_01_10 "CELL_01 Voltage";
BA_ "FlexKomIsMotorola" SG_ 1698 CELL_VOLT_01_10 1;
BA_ "GenSigSendType" SG_ 1682 CELL_VOLT_04_09 0;
BA_ "GenSigCycleTime" SG_ 1682 CELL_VOLT_04_09 40;
BA_ "FlexKomSigStartValue" SG_ 1682 CELL_VOLT_04_09 "0000h";
BA_ "GenSigTimeout_BMU" SG_ 1682 CELL_VOLT_04_09 220;
BA_ "FlexKomSID" SG_ 1682 CELL_VOLT_04_09 1155;
BA_ "FlexKomSigStartPos" SG_ 1682 CELL_VOLT_04_09 55;
BA_ "FlexKomSigLaenge" SG_ 1682 CELL_VOLT_04_09 16;
BA_ "FlexKomSigName" SG_ 1682 CELL_VOLT_04_09 "CELL_VOLT_04_09";
BA_ "FlexKomComment" SG_ 1682 CELL_VOLT_04_09 "CELL_04 Voltage";
BA_ "FlexKomIsMotorola" SG_ 1682 CELL_VOLT_04_09 1;
BA_ "GenSigSendType" SG_ 1682 CELL_VOLT_03_09 0;
BA_ "GenSigCycleTime" SG_ 1682 CELL_VOLT_03_09 40;
BA_ "FlexKomSigStartValue" SG_ 1682 CELL_VOLT_03_09 "0000h";
BA_ "GenSigTimeout_BMU" SG_ 1682 CELL_VOLT_03_09 220;
BA_ "FlexKomSID" SG_ 1682 CELL_VOLT_03_09 1143;
BA_ "FlexKomSigStartPos" SG_ 1682 CELL_VOLT_03_09 39;
BA_ "FlexKomSigLaenge" SG_ 1682 CELL_VOLT_03_09 16;
BA_ "FlexKomSigName" SG_ 1682 CELL_VOLT_03_09 "CELL_VOLT_03_09";
BA_ "FlexKomComment" SG_ 1682 CELL_VOLT_03_09 "CELL_03 Voltage";
BA_ "FlexKomIsMotorola" SG_ 1682 CELL_VOLT_03_09 1;
BA_ "GenSigSendType" SG_ 1682 CELL_VOLT_02_09 0;
BA_ "GenSigCycleTime" SG_ 1682 CELL_VOLT_02_09 40;
BA_ "FlexKomSigStartValue" SG_ 1682 CELL_VOLT_02_09 "0000h";
BA_ "GenSigTimeout_BMU" SG_ 1682 CELL_VOLT_02_09 220;
BA_ "FlexKomSID" SG_ 1682 CELL_VOLT_02_09 1131;
BA_ "FlexKomSigStartPos" SG_ 1682 CELL_VOLT_02_09 23;
BA_ "FlexKomSigLaenge" SG_ 1682 CELL_VOLT_02_09 16;
BA_ "FlexKomSigName" SG_ 1682 CELL_VOLT_02_09 "CELL_VOLT_02_09";
BA_ "FlexKomComment" SG_ 1682 CELL_VOLT_02_09 "CELL_02 Voltage";
BA_ "FlexKomIsMotorola" SG_ 1682 CELL_VOLT_02_09 1;
BA_ "GenSigSendType" SG_ 1682 CELL_VOLT_01_09 0;
BA_ "GenSigCycleTime" SG_ 1682 CELL_VOLT_01_09 40;
BA_ "FlexKomSigStartValue" SG_ 1682 CELL_VOLT_01_09 "0000h";
BA_ "GenSigTimeout_BMU" SG_ 1682 CELL_VOLT_01_09 220;
BA_ "FlexKomSID" SG_ 1682 CELL_VOLT_01_09 1119;
BA_ "FlexKomSigStartPos" SG_ 1682 CELL_VOLT_01_09 7;
BA_ "FlexKomSigLaenge" SG_ 1682 CELL_VOLT_01_09 16;
BA_ "FlexKomSigName" SG_ 1682 CELL_VOLT_01_09 "CELL_VOLT_01_09";
BA_ "FlexKomComment" SG_ 1682 CELL_VOLT_01_09 "CELL_01 Voltage";
BA_ "FlexKomIsMotorola" SG_ 1682 CELL_VOLT_01_09 1;
BA_ "GenSigSendType" SG_ 1666 CELL_VOLT_04_08 0;
BA_ "GenSigCycleTime" SG_ 1666 CELL_VOLT_04_08 40;
BA_ "FlexKomSigStartValue" SG_ 1666 CELL_VOLT_04_08 "0000h";
BA_ "GenSigTimeout_BMU" SG_ 1666 CELL_VOLT_04_08 220;
BA_ "FlexKomSID" SG_ 1666 CELL_VOLT_04_08 1154;
BA_ "FlexKomSigStartPos" SG_ 1666 CELL_VOLT_04_08 55;
BA_ "FlexKomSigLaenge" SG_ 1666 CELL_VOLT_04_08 16;
BA_ "FlexKomSigName" SG_ 1666 CELL_VOLT_04_08 "CELL_VOLT_04_08";
BA_ "FlexKomComment" SG_ 1666 CELL_VOLT_04_08 "CELL_04 Voltage";
BA_ "FlexKomIsMotorola" SG_ 1666 CELL_VOLT_04_08 1;
BA_ "GenSigSendType" SG_ 1666 CELL_VOLT_03_08 0;
BA_ "GenSigCycleTime" SG_ 1666 CELL_VOLT_03_08 40;
BA_ "FlexKomSigStartValue" SG_ 1666 CELL_VOLT_03_08 "0000h";
BA_ "GenSigTimeout_BMU" SG_ 1666 CELL_VOLT_03_08 220;
BA_ "FlexKomSID" SG_ 1666 CELL_VOLT_03_08 1142;
BA_ "FlexKomSigStartPos" SG_ 1666 CELL_VOLT_03_08 39;
BA_ "FlexKomSigLaenge" SG_ 1666 CELL_VOLT_03_08 16;
BA_ "FlexKomSigName" SG_ 1666 CELL_VOLT_03_08 "CELL_VOLT_03_08";
BA_ "FlexKomComment" SG_ 1666 CELL_VOLT_03_08 "CELL_03 Voltage";
BA_ "FlexKomIsMotorola" SG_ 1666 CELL_VOLT_03_08 1;
BA_ "GenSigSendType" SG_ 1666 CELL_VOLT_02_08 0;
BA_ "GenSigCycleTime" SG_ 1666 CELL_VOLT_02_08 40;
BA_ "FlexKomSigStartValue" SG_ 1666 CELL_VOLT_02_08 "0000h";
BA_ "GenSigTimeout_BMU" SG_ 1666 CELL_VOLT_02_08 220;
BA_ "FlexKomSID" SG_ 1666 CELL_VOLT_02_08 1130;
BA_ "FlexKomSigStartPos" SG_ 1666 CELL_VOLT_02_08 23;
BA_ "FlexKomSigLaenge" SG_ 1666 CELL_VOLT_02_08 16;
BA_ "FlexKomSigName" SG_ 1666 CELL_VOLT_02_08 "CELL_VOLT_02_08";
BA_ "FlexKomComment" SG_ 1666 CELL_VOLT_02_08 "CELL_02 Voltage";
BA_ "FlexKomIsMotorola" SG_ 1666 CELL_VOLT_02_08 1;
BA_ "GenSigSendType" SG_ 1666 CELL_VOLT_01_08 0;
BA_ "GenSigCycleTime" SG_ 1666 CELL_VOLT_01_08 40;
BA_ "FlexKomSigStartValue" SG_ 1666 CELL_VOLT_01_08 "0000h";
BA_ "GenSigTimeout_BMU" SG_ 1666 CELL_VOLT_01_08 220;
BA_ "FlexKomSID" SG_ 1666 CELL_VOLT_01_08 1118;
BA_ "FlexKomSigStartPos" SG_ 1666 CELL_VOLT_01_08 7;
BA_ "FlexKomSigLaenge" SG_ 1666 CELL_VOLT_01_08 16;
BA_ "FlexKomSigName" SG_ 1666 CELL_VOLT_01_08 "CELL_VOLT_01_08";
BA_ "FlexKomComment" SG_ 1666 CELL_VOLT_01_08 "CELL_01 Voltage";
BA_ "FlexKomIsMotorola" SG_ 1666 CELL_VOLT_01_08 1;
BA_ "GenSigSendType" SG_ 1650 CELL_VOLT_04_07 0;
BA_ "GenSigCycleTime" SG_ 1650 CELL_VOLT_04_07 40;
BA_ "FlexKomSigStartValue" SG_ 1650 CELL_VOLT_04_07 "0000h";
BA_ "GenSigTimeout_BMU" SG_ 1650 CELL_VOLT_04_07 220;
BA_ "FlexKomSID" SG_ 1650 CELL_VOLT_04_07 1153;
BA_ "FlexKomSigStartPos" SG_ 1650 CELL_VOLT_04_07 55;
BA_ "FlexKomSigLaenge" SG_ 1650 CELL_VOLT_04_07 16;
BA_ "FlexKomSigName" SG_ 1650 CELL_VOLT_04_07 "CELL_VOLT_04_07";
BA_ "FlexKomComment" SG_ 1650 CELL_VOLT_04_07 "CELL_04 Voltage";
BA_ "FlexKomIsMotorola" SG_ 1650 CELL_VOLT_04_07 1;
BA_ "GenSigSendType" SG_ 1650 CELL_VOLT_03_07 0;
BA_ "GenSigCycleTime" SG_ 1650 CELL_VOLT_03_07 40;
BA_ "FlexKomSigStartValue" SG_ 1650 CELL_VOLT_03_07 "0000h";
BA_ "GenSigTimeout_BMU" SG_ 1650 CELL_VOLT_03_07 220;
BA_ "FlexKomSID" SG_ 1650 CELL_VOLT_03_07 1141;
BA_ "FlexKomSigStartPos" SG_ 1650 CELL_VOLT_03_07 39;
BA_ "FlexKomSigLaenge" SG_ 1650 CELL_VOLT_03_07 16;
BA_ "FlexKomSigName" SG_ 1650 CELL_VOLT_03_07 "CELL_VOLT_03_07";
BA_ "FlexKomComment" SG_ 1650 CELL_VOLT_03_07 "CELL_03 Voltage";
BA_ "FlexKomIsMotorola" SG_ 1650 CELL_VOLT_03_07 1;
BA_ "GenSigSendType" SG_ 1650 CELL_VOLT_02_07 0;
BA_ "GenSigCycleTime" SG_ 1650 CELL_VOLT_02_07 40;
BA_ "FlexKomSigStartValue" SG_ 1650 CELL_VOLT_02_07 "0000h";
BA_ "GenSigTimeout_BMU" SG_ 1650 CELL_VOLT_02_07 220;
BA_ "FlexKomSID" SG_ 1650 CELL_VOLT_02_07 1129;
BA_ "FlexKomSigStartPos" SG_ 1650 CELL_VOLT_02_07 23;
BA_ "FlexKomSigLaenge" SG_ 1650 CELL_VOLT_02_07 16;
BA_ "FlexKomSigName" SG_ 1650 CELL_VOLT_02_07 "CELL_VOLT_02_07";
BA_ "FlexKomComment" SG_ 1650 CELL_VOLT_02_07 "CELL_02 Voltage";
BA_ "FlexKomIsMotorola" SG_ 1650 CELL_VOLT_02_07 1;
BA_ "GenSigSendType" SG_ 1650 CELL_VOLT_01_07 0;
BA_ "GenSigCycleTime" SG_ 1650 CELL_VOLT_01_07 40;
BA_ "FlexKomSigStartValue" SG_ 1650 CELL_VOLT_01_07 "0000h";
BA_ "GenSigTimeout_BMU" SG_ 1650 CELL_VOLT_01_07 220;
BA_ "FlexKomSID" SG_ 1650 CELL_VOLT_01_07 1117;
BA_ "FlexKomSigStartPos" SG_ 1650 CELL_VOLT_01_07 7;
BA_ "FlexKomSigLaenge" SG_ 1650 CELL_VOLT_01_07 16;
BA_ "FlexKomSigName" SG_ 1650 CELL_VOLT_01_07 "CELL_VOLT_01_07";
BA_ "FlexKomComment" SG_ 1650 CELL_VOLT_01_07 "CELL_01 Voltage";
BA_ "FlexKomIsMotorola" SG_ 1650 CELL_VOLT_01_07 1;
BA_ "GenSigSendType" SG_ 1634 CELL_VOLT_04_06 0;
BA_ "GenSigCycleTime" SG_ 1634 CELL_VOLT_04_06 40;
BA_ "FlexKomSigStartValue" SG_ 1634 CELL_VOLT_04_06 "0000h";
BA_ "GenSigTimeout_BMU" SG_ 1634 CELL_VOLT_04_06 220;
BA_ "FlexKomSID" SG_ 1634 CELL_VOLT_04_06 1152;
BA_ "FlexKomSigStartPos" SG_ 1634 CELL_VOLT_04_06 55;
BA_ "FlexKomSigLaenge" SG_ 1634 CELL_VOLT_04_06 16;
BA_ "FlexKomSigName" SG_ 1634 CELL_VOLT_04_06 "CELL_VOLT_04_06";
BA_ "FlexKomComment" SG_ 1634 CELL_VOLT_04_06 "CELL_04 Voltage";
BA_ "FlexKomIsMotorola" SG_ 1634 CELL_VOLT_04_06 1;
BA_ "GenSigSendType" SG_ 1634 CELL_VOLT_03_06 0;
BA_ "GenSigCycleTime" SG_ 1634 CELL_VOLT_03_06 40;
BA_ "FlexKomSigStartValue" SG_ 1634 CELL_VOLT_03_06 "0000h";
BA_ "GenSigTimeout_BMU" SG_ 1634 CELL_VOLT_03_06 220;
BA_ "FlexKomSID" SG_ 1634 CELL_VOLT_03_06 1140;
BA_ "FlexKomSigStartPos" SG_ 1634 CELL_VOLT_03_06 39;
BA_ "FlexKomSigLaenge" SG_ 1634 CELL_VOLT_03_06 16;
BA_ "FlexKomSigName" SG_ 1634 CELL_VOLT_03_06 "CELL_VOLT_03_06";
BA_ "FlexKomComment" SG_ 1634 CELL_VOLT_03_06 "CELL_03 Voltage";
BA_ "FlexKomIsMotorola" SG_ 1634 CELL_VOLT_03_06 1;
BA_ "GenSigSendType" SG_ 1634 CELL_VOLT_02_06 0;
BA_ "GenSigCycleTime" SG_ 1634 CELL_VOLT_02_06 40;
BA_ "FlexKomSigStartValue" SG_ 1634 CELL_VOLT_02_06 "0000h";
BA_ "GenSigTimeout_BMU" SG_ 1634 CELL_VOLT_02_06 220;
BA_ "FlexKomSID" SG_ 1634 CELL_VOLT_02_06 1128;
BA_ "FlexKomSigStartPos" SG_ 1634 CELL_VOLT_02_06 23;
BA_ "FlexKomSigLaenge" SG_ 1634 CELL_VOLT_02_06 16;
BA_ "FlexKomSigName" SG_ 1634 CELL_VOLT_02_06 "CELL_VOLT_02_06";
BA_ "FlexKomComment" SG_ 1634 CELL_VOLT_02_06 "CELL_02 Voltage";
BA_ "FlexKomIsMotorola" SG_ 1634 CELL_VOLT_02_06 1;
BA_ "GenSigSendType" SG_ 1634 CELL_VOLT_01_06 0;
BA_ "GenSigCycleTime" SG_ 1634 CELL_VOLT_01_06 40;
BA_ "FlexKomSigStartValue" SG_ 1634 CELL_VOLT_01_06 "0000h";
BA_ "GenSigTimeout_BMU" SG_ 1634 CELL_VOLT_01_06 220;
BA_ "FlexKomSID" SG_ 1634 CELL_VOLT_01_06 1116;
BA_ "FlexKomSigStartPos" SG_ 1634 CELL_VOLT_01_06 7;
BA_ "FlexKomSigLaenge" SG_ 1634 CELL_VOLT_01_06 16;
BA_ "FlexKomSigName" SG_ 1634 CELL_VOLT_01_06 "CELL_VOLT_01_06";
BA_ "FlexKomComment" SG_ 1634 CELL_VOLT_01_06 "CELL_01 Voltage";
BA_ "FlexKomIsMotorola" SG_ 1634 CELL_VOLT_01_06 1;
BA_ "GenSigSendType" SG_ 1618 CELL_VOLT_04_05 0;
BA_ "GenSigCycleTime" SG_ 1618 CELL_VOLT_04_05 40;
BA_ "FlexKomSigStartValue" SG_ 1618 CELL_VOLT_04_05 "0000h";
BA_ "GenSigTimeout_BMU" SG_ 1618 CELL_VOLT_04_05 220;
BA_ "FlexKomSID" SG_ 1618 CELL_VOLT_04_05 1151;
BA_ "FlexKomSigStartPos" SG_ 1618 CELL_VOLT_04_05 55;
BA_ "FlexKomSigLaenge" SG_ 1618 CELL_VOLT_04_05 16;
BA_ "FlexKomSigName" SG_ 1618 CELL_VOLT_04_05 "CELL_VOLT_04_05";
BA_ "FlexKomComment" SG_ 1618 CELL_VOLT_04_05 "CELL_04 Voltage";
BA_ "FlexKomIsMotorola" SG_ 1618 CELL_VOLT_04_05 1;
BA_ "GenSigSendType" SG_ 1618 CELL_VOLT_03_05 0;
BA_ "GenSigCycleTime" SG_ 1618 CELL_VOLT_03_05 40;
BA_ "FlexKomSigStartValue" SG_ 1618 CELL_VOLT_03_05 "0000h";
BA_ "GenSigTimeout_BMU" SG_ 1618 CELL_VOLT_03_05 220;
BA_ "FlexKomSID" SG_ 1618 CELL_VOLT_03_05 1139;
BA_ "FlexKomSigStartPos" SG_ 1618 CELL_VOLT_03_05 39;
BA_ "FlexKomSigLaenge" SG_ 1618 CELL_VOLT_03_05 16;
BA_ "FlexKomSigName" SG_ 1618 CELL_VOLT_03_05 "CELL_VOLT_03_05";
BA_ "FlexKomComment" SG_ 1618 CELL_VOLT_03_05 "CELL_03 Voltage";
BA_ "FlexKomIsMotorola" SG_ 1618 CELL_VOLT_03_05 1;
BA_ "GenSigSendType" SG_ 1618 CELL_VOLT_02_05 0;
BA_ "GenSigCycleTime" SG_ 1618 CELL_VOLT_02_05 40;
BA_ "FlexKomSigStartValue" SG_ 1618 CELL_VOLT_02_05 "0000h";
BA_ "GenSigTimeout_BMU" SG_ 1618 CELL_VOLT_02_05 220;
BA_ "FlexKomSID" SG_ 1618 CELL_VOLT_02_05 1127;
BA_ "FlexKomSigStartPos" SG_ 1618 CELL_VOLT_02_05 23;
BA_ "FlexKomSigLaenge" SG_ 1618 CELL_VOLT_02_05 16;
BA_ "FlexKomSigName" SG_ 1618 CELL_VOLT_02_05 "CELL_VOLT_02_05";
BA_ "FlexKomComment" SG_ 1618 CELL_VOLT_02_05 "CELL_02 Voltage";
BA_ "FlexKomIsMotorola" SG_ 1618 CELL_VOLT_02_05 1;
BA_ "GenSigSendType" SG_ 1618 CELL_VOLT_01_05 0;
BA_ "GenSigCycleTime" SG_ 1618 CELL_VOLT_01_05 40;
BA_ "FlexKomSigStartValue" SG_ 1618 CELL_VOLT_01_05 "0000h";
BA_ "GenSigTimeout_BMU" SG_ 1618 CELL_VOLT_01_05 220;
BA_ "FlexKomSID" SG_ 1618 CELL_VOLT_01_05 1115;
BA_ "FlexKomSigStartPos" SG_ 1618 CELL_VOLT_01_05 7;
BA_ "FlexKomSigLaenge" SG_ 1618 CELL_VOLT_01_05 16;
BA_ "FlexKomSigName" SG_ 1618 CELL_VOLT_01_05 "CELL_VOLT_01_05";
BA_ "FlexKomComment" SG_ 1618 CELL_VOLT_01_05 "CELL_01 Voltage";
BA_ "FlexKomIsMotorola" SG_ 1618 CELL_VOLT_01_05 1;
BA_ "GenSigSendType" SG_ 1602 CELL_VOLT_04_04 0;
BA_ "GenSigCycleTime" SG_ 1602 CELL_VOLT_04_04 40;
BA_ "FlexKomSigStartValue" SG_ 1602 CELL_VOLT_04_04 "0000h";
BA_ "GenSigTimeout_BMU" SG_ 1602 CELL_VOLT_04_04 220;
BA_ "FlexKomSID" SG_ 1602 CELL_VOLT_04_04 1150;
BA_ "FlexKomSigStartPos" SG_ 1602 CELL_VOLT_04_04 55;
BA_ "FlexKomSigLaenge" SG_ 1602 CELL_VOLT_04_04 16;
BA_ "FlexKomSigName" SG_ 1602 CELL_VOLT_04_04 "CELL_VOLT_04_04";
BA_ "FlexKomComment" SG_ 1602 CELL_VOLT_04_04 "CELL_04 Voltage";
BA_ "FlexKomIsMotorola" SG_ 1602 CELL_VOLT_04_04 1;
BA_ "GenSigSendType" SG_ 1602 CELL_VOLT_03_04 0;
BA_ "GenSigCycleTime" SG_ 1602 CELL_VOLT_03_04 40;
BA_ "FlexKomSigStartValue" SG_ 1602 CELL_VOLT_03_04 "0000h";
BA_ "GenSigTimeout_BMU" SG_ 1602 CELL_VOLT_03_04 220;
BA_ "FlexKomSID" SG_ 1602 CELL_VOLT_03_04 1138;
BA_ "FlexKomSigStartPos" SG_ 1602 CELL_VOLT_03_04 39;
BA_ "FlexKomSigLaenge" SG_ 1602 CELL_VOLT_03_04 16;
BA_ "FlexKomSigName" SG_ 1602 CELL_VOLT_03_04 "CELL_VOLT_03_04";
BA_ "FlexKomComment" SG_ 1602 CELL_VOLT_03_04 "CELL_03 Voltage";
BA_ "FlexKomIsMotorola" SG_ 1602 CELL_VOLT_03_04 1;
BA_ "GenSigSendType" SG_ 1602 CELL_VOLT_02_04 0;
BA_ "GenSigCycleTime" SG_ 1602 CELL_VOLT_02_04 40;
BA_ "FlexKomSigStartValue" SG_ 1602 CELL_VOLT_02_04 "0000h";
BA_ "GenSigTimeout_BMU" SG_ 1602 CELL_VOLT_02_04 220;
BA_ "FlexKomSID" SG_ 1602 CELL_VOLT_02_04 1126;
BA_ "FlexKomSigStartPos" SG_ 1602 CELL_VOLT_02_04 23;
BA_ "FlexKomSigLaenge" SG_ 1602 CELL_VOLT_02_04 16;
BA_ "FlexKomSigName" SG_ 1602 CELL_VOLT_02_04 "CELL_VOLT_02_04";
BA_ "FlexKomComment" SG_ 1602 CELL_VOLT_02_04 "CELL_02 Voltage";
BA_ "FlexKomIsMotorola" SG_ 1602 CELL_VOLT_02_04 1;
BA_ "GenSigSendType" SG_ 1602 CELL_VOLT_01_04 0;
BA_ "GenSigCycleTime" SG_ 1602 CELL_VOLT_01_04 40;
BA_ "FlexKomSigStartValue" SG_ 1602 CELL_VOLT_01_04 "0000h";
BA_ "GenSigTimeout_BMU" SG_ 1602 CELL_VOLT_01_04 220;
BA_ "FlexKomSID" SG_ 1602 CELL_VOLT_01_04 1114;
BA_ "FlexKomSigStartPos" SG_ 1602 CELL_VOLT_01_04 7;
BA_ "FlexKomSigLaenge" SG_ 1602 CELL_VOLT_01_04 16;
BA_ "FlexKomSigName" SG_ 1602 CELL_VOLT_01_04 "CELL_VOLT_01_04";
BA_ "FlexKomComment" SG_ 1602 CELL_VOLT_01_04 "CELL_01 Voltage";
BA_ "FlexKomIsMotorola" SG_ 1602 CELL_VOLT_01_04 1;
BA_ "GenSigSendType" SG_ 1586 CELL_VOLT_04_03 0;
BA_ "GenSigCycleTime" SG_ 1586 CELL_VOLT_04_03 40;
BA_ "FlexKomSigStartValue" SG_ 1586 CELL_VOLT_04_03 "0000h";
BA_ "GenSigTimeout_BMU" SG_ 1586 CELL_VOLT_04_03 220;
BA_ "FlexKomSID" SG_ 1586 CELL_VOLT_04_03 1149;
BA_ "FlexKomSigStartPos" SG_ 1586 CELL_VOLT_04_03 55;
BA_ "FlexKomSigLaenge" SG_ 1586 CELL_VOLT_04_03 16;
BA_ "FlexKomSigName" SG_ 1586 CELL_VOLT_04_03 "CELL_VOLT_04_03";
BA_ "FlexKomComment" SG_ 1586 CELL_VOLT_04_03 "CELL_04 Voltage";
BA_ "FlexKomIsMotorola" SG_ 1586 CELL_VOLT_04_03 1;
BA_ "GenSigSendType" SG_ 1586 CELL_VOLT_03_03 0;
BA_ "GenSigCycleTime" SG_ 1586 CELL_VOLT_03_03 40;
BA_ "FlexKomSigStartValue" SG_ 1586 CELL_VOLT_03_03 "0000h";
BA_ "GenSigTimeout_BMU" SG_ 1586 CELL_VOLT_03_03 220;
BA_ "FlexKomSID" SG_ 1586 CELL_VOLT_03_03 1137;
BA_ "FlexKomSigStartPos" SG_ 1586 CELL_VOLT_03_03 39;
BA_ "FlexKomSigLaenge" SG_ 1586 CELL_VOLT_03_03 16;
BA_ "FlexKomSigName" SG_ 1586 CELL_VOLT_03_03 "CELL_VOLT_03_03";
BA_ "FlexKomComment" SG_ 1586 CELL_VOLT_03_03 "CELL_03 Voltage";
BA_ "FlexKomIsMotorola" SG_ 1586 CELL_VOLT_03_03 1;
BA_ "GenSigSendType" SG_ 1586 CELL_VOLT_02_03 0;
BA_ "GenSigCycleTime" SG_ 1586 CELL_VOLT_02_03 40;
BA_ "FlexKomSigStartValue" SG_ 1586 CELL_VOLT_02_03 "0000h";
BA_ "GenSigTimeout_BMU" SG_ 1586 CELL_VOLT_02_03 220;
BA_ "FlexKomSID" SG_ 1586 CELL_VOLT_02_03 1125;
BA_ "FlexKomSigStartPos" SG_ 1586 CELL_VOLT_02_03 23;
BA_ "FlexKomSigLaenge" SG_ 1586 CELL_VOLT_02_03 16;
BA_ "FlexKomSigName" SG_ 1586 CELL_VOLT_02_03 "CELL_VOLT_02_03";
BA_ "FlexKomComment" SG_ 1586 CELL_VOLT_02_03 "CELL_02 Voltage";
BA_ "FlexKomIsMotorola" SG_ 1586 CELL_VOLT_02_03 1;
BA_ "GenSigSendType" SG_ 1586 CELL_VOLT_01_03 0;
BA_ "GenSigCycleTime" SG_ 1586 CELL_VOLT_01_03 40;
BA_ "FlexKomSigStartValue" SG_ 1586 CELL_VOLT_01_03 "0000h";
BA_ "GenSigTimeout_BMU" SG_ 1586 CELL_VOLT_01_03 220;
BA_ "FlexKomSID" SG_ 1586 CELL_VOLT_01_03 1113;
BA_ "FlexKomSigStartPos" SG_ 1586 CELL_VOLT_01_03 7;
BA_ "FlexKomSigLaenge" SG_ 1586 CELL_VOLT_01_03 16;
BA_ "FlexKomSigName" SG_ 1586 CELL_VOLT_01_03 "CELL_VOLT_01_03";
BA_ "FlexKomComment" SG_ 1586 CELL_VOLT_01_03 "CELL_01 Voltage";
BA_ "FlexKomIsMotorola" SG_ 1586 CELL_VOLT_01_03 1;
BA_ "GenSigSendType" SG_ 1570 CELL_VOLT_04_02 0;
BA_ "GenSigCycleTime" SG_ 1570 CELL_VOLT_04_02 40;
BA_ "FlexKomSigStartValue" SG_ 1570 CELL_VOLT_04_02 "0000h";
BA_ "GenSigTimeout_BMU" SG_ 1570 CELL_VOLT_04_02 220;
BA_ "FlexKomSID" SG_ 1570 CELL_VOLT_04_02 1148;
BA_ "FlexKomSigStartPos" SG_ 1570 CELL_VOLT_04_02 55;
BA_ "FlexKomSigLaenge" SG_ 1570 CELL_VOLT_04_02 16;
BA_ "FlexKomSigName" SG_ 1570 CELL_VOLT_04_02 "CELL_VOLT_04_02";
BA_ "FlexKomComment" SG_ 1570 CELL_VOLT_04_02 "CELL_04 Voltage";
BA_ "FlexKomIsMotorola" SG_ 1570 CELL_VOLT_04_02 1;
BA_ "GenSigSendType" SG_ 1570 CELL_VOLT_03_02 0;
BA_ "GenSigCycleTime" SG_ 1570 CELL_VOLT_03_02 40;
BA_ "FlexKomSigStartValue" SG_ 1570 CELL_VOLT_03_02 "0000h";
BA_ "GenSigTimeout_BMU" SG_ 1570 CELL_VOLT_03_02 220;
BA_ "FlexKomSID" SG_ 1570 CELL_VOLT_03_02 1136;
BA_ "FlexKomSigStartPos" SG_ 1570 CELL_VOLT_03_02 39;
BA_ "FlexKomSigLaenge" SG_ 1570 CELL_VOLT_03_02 16;
BA_ "FlexKomSigName" SG_ 1570 CELL_VOLT_03_02 "CELL_VOLT_03_02";
BA_ "FlexKomComment" SG_ 1570 CELL_VOLT_03_02 "CELL_03 Voltage";
BA_ "FlexKomIsMotorola" SG_ 1570 CELL_VOLT_03_02 1;
BA_ "GenSigSendType" SG_ 1570 CELL_VOLT_02_02 0;
BA_ "GenSigCycleTime" SG_ 1570 CELL_VOLT_02_02 40;
BA_ "FlexKomSigStartValue" SG_ 1570 CELL_VOLT_02_02 "0000h";
BA_ "GenSigTimeout_BMU" SG_ 1570 CELL_VOLT_02_02 220;
BA_ "FlexKomSID" SG_ 1570 CELL_VOLT_02_02 1124;
BA_ "FlexKomSigStartPos" SG_ 1570 CELL_VOLT_02_02 23;
BA_ "FlexKomSigLaenge" SG_ 1570 CELL_VOLT_02_02 16;
BA_ "FlexKomSigName" SG_ 1570 CELL_VOLT_02_02 "CELL_VOLT_02_02";
BA_ "FlexKomComment" SG_ 1570 CELL_VOLT_02_02 "CELL_02 Voltage";
BA_ "FlexKomIsMotorola" SG_ 1570 CELL_VOLT_02_02 1;
BA_ "GenSigSendType" SG_ 1570 CELL_VOLT_01_02 0;
BA_ "GenSigCycleTime" SG_ 1570 CELL_VOLT_01_02 40;
BA_ "FlexKomSigStartValue" SG_ 1570 CELL_VOLT_01_02 "0000h";
BA_ "GenSigTimeout_BMU" SG_ 1570 CELL_VOLT_01_02 220;
BA_ "FlexKomSID" SG_ 1570 CELL_VOLT_01_02 1112;
BA_ "FlexKomSigStartPos" SG_ 1570 CELL_VOLT_01_02 7;
BA_ "FlexKomSigLaenge" SG_ 1570 CELL_VOLT_01_02 16;
BA_ "FlexKomSigName" SG_ 1570 CELL_VOLT_01_02 "CELL_VOLT_01_02";
BA_ "FlexKomComment" SG_ 1570 CELL_VOLT_01_02 "CELL_01 Voltage";
BA_ "FlexKomIsMotorola" SG_ 1570 CELL_VOLT_01_02 1;
BA_ "GenSigSendType" SG_ 1554 CELL_VOLT_04_01 0;
BA_ "GenSigCycleTime" SG_ 1554 CELL_VOLT_04_01 40;
BA_ "FlexKomSigStartValue" SG_ 1554 CELL_VOLT_04_01 "0000h";
BA_ "GenSigTimeout_BMU" SG_ 1554 CELL_VOLT_04_01 220;
BA_ "FlexKomSID" SG_ 1554 CELL_VOLT_04_01 1147;
BA_ "FlexKomSigStartPos" SG_ 1554 CELL_VOLT_04_01 55;
BA_ "FlexKomSigLaenge" SG_ 1554 CELL_VOLT_04_01 16;
BA_ "FlexKomSigName" SG_ 1554 CELL_VOLT_04_01 "CELL_VOLT_04_01";
BA_ "FlexKomComment" SG_ 1554 CELL_VOLT_04_01 "CELL_04 Voltage";
BA_ "FlexKomIsMotorola" SG_ 1554 CELL_VOLT_04_01 1;
BA_ "GenSigSendType" SG_ 1554 CELL_VOLT_03_01 0;
BA_ "GenSigCycleTime" SG_ 1554 CELL_VOLT_03_01 40;
BA_ "FlexKomSigStartValue" SG_ 1554 CELL_VOLT_03_01 "0000h";
BA_ "GenSigTimeout_BMU" SG_ 1554 CELL_VOLT_03_01 220;
BA_ "FlexKomSID" SG_ 1554 CELL_VOLT_03_01 1135;
BA_ "FlexKomSigStartPos" SG_ 1554 CELL_VOLT_03_01 39;
BA_ "FlexKomSigLaenge" SG_ 1554 CELL_VOLT_03_01 16;
BA_ "FlexKomSigName" SG_ 1554 CELL_VOLT_03_01 "CELL_VOLT_03_01";
BA_ "FlexKomComment" SG_ 1554 CELL_VOLT_03_01 "CELL_03 Voltage";
BA_ "FlexKomIsMotorola" SG_ 1554 CELL_VOLT_03_01 1;
BA_ "GenSigSendType" SG_ 1554 CELL_VOLT_02_01 0;
BA_ "GenSigCycleTime" SG_ 1554 CELL_VOLT_02_01 40;
BA_ "FlexKomSigStartValue" SG_ 1554 CELL_VOLT_02_01 "0000h";
BA_ "GenSigTimeout_BMU" SG_ 1554 CELL_VOLT_02_01 220;
BA_ "FlexKomSID" SG_ 1554 CELL_VOLT_02_01 1123;
BA_ "FlexKomSigStartPos" SG_ 1554 CELL_VOLT_02_01 23;
BA_ "FlexKomSigLaenge" SG_ 1554 CELL_VOLT_02_01 16;
BA_ "FlexKomSigName" SG_ 1554 CELL_VOLT_02_01 "CELL_VOLT_02_01";
BA_ "FlexKomComment" SG_ 1554 CELL_VOLT_02_01 "CELL_02 Voltage";
BA_ "FlexKomIsMotorola" SG_ 1554 CELL_VOLT_02_01 1;
BA_ "GenSigSendType" SG_ 1554 CELL_VOLT_01_01 0;
BA_ "GenSigCycleTime" SG_ 1554 CELL_VOLT_01_01 40;
BA_ "FlexKomSigStartValue" SG_ 1554 CELL_VOLT_01_01 "0000h";
BA_ "GenSigTimeout_BMU" SG_ 1554 CELL_VOLT_01_01 220;
BA_ "FlexKomSID" SG_ 1554 CELL_VOLT_01_01 1111;
BA_ "FlexKomSigStartPos" SG_ 1554 CELL_VOLT_01_01 7;
BA_ "FlexKomSigLaenge" SG_ 1554 CELL_VOLT_01_01 16;
BA_ "FlexKomSigName" SG_ 1554 CELL_VOLT_01_01 "CELL_VOLT_01_01";
BA_ "FlexKomComment" SG_ 1554 CELL_VOLT_01_01 "CELL_01 Voltage";
BA_ "FlexKomIsMotorola" SG_ 1554 CELL_VOLT_01_01 1;
BA_ "GenSigSendType" SG_ 1729 MODULE_TEMP_06_12 0;
BA_ "GenSigCycleTime" SG_ 1729 MODULE_TEMP_06_12 40;
BA_ "FlexKomSigStartValue" SG_ 1729 MODULE_TEMP_06_12 "00h";
BA_ "GenSigTimeout_BMU" SG_ 1729 MODULE_TEMP_06_12 220;
BA_ "FlexKomSID" SG_ 1729 MODULE_TEMP_06_12 1110;
BA_ "FlexKomSigStartPos" SG_ 1729 MODULE_TEMP_06_12 63;
BA_ "FlexKomSigLaenge" SG_ 1729 MODULE_TEMP_06_12 8;
BA_ "FlexKomSigName" SG_ 1729 MODULE_TEMP_06_12 "MODULE_TEMP_06_12";
BA_ "FlexKomComment" SG_ 1729 MODULE_TEMP_06_12 "Module temperature06";
BA_ "FlexKomIsMotorola" SG_ 1729 MODULE_TEMP_06_12 1;
BA_ "GenSigSendType" SG_ 1729 MODULE_TEMP_05_12 0;
BA_ "GenSigCycleTime" SG_ 1729 MODULE_TEMP_05_12 40;
BA_ "FlexKomSigStartValue" SG_ 1729 MODULE_TEMP_05_12 "00h";
BA_ "GenSigTimeout_BMU" SG_ 1729 MODULE_TEMP_05_12 220;
BA_ "FlexKomSID" SG_ 1729 MODULE_TEMP_05_12 1098;
BA_ "FlexKomSigStartPos" SG_ 1729 MODULE_TEMP_05_12 55;
BA_ "FlexKomSigLaenge" SG_ 1729 MODULE_TEMP_05_12 8;
BA_ "FlexKomSigName" SG_ 1729 MODULE_TEMP_05_12 "MODULE_TEMP_05_12";
BA_ "FlexKomComment" SG_ 1729 MODULE_TEMP_05_12 "Module temperature05";
BA_ "FlexKomIsMotorola" SG_ 1729 MODULE_TEMP_05_12 1;
BA_ "GenSigSendType" SG_ 1729 MODULE_TEMP_04_12 0;
BA_ "GenSigCycleTime" SG_ 1729 MODULE_TEMP_04_12 40;
BA_ "FlexKomSigStartValue" SG_ 1729 MODULE_TEMP_04_12 "00h";
BA_ "GenSigTimeout_BMU" SG_ 1729 MODULE_TEMP_04_12 220;
BA_ "FlexKomSID" SG_ 1729 MODULE_TEMP_04_12 1086;
BA_ "FlexKomSigStartPos" SG_ 1729 MODULE_TEMP_04_12 47;
BA_ "FlexKomSigLaenge" SG_ 1729 MODULE_TEMP_04_12 8;
BA_ "FlexKomSigName" SG_ 1729 MODULE_TEMP_04_12 "MODULE_TEMP_04_12";
BA_ "FlexKomComment" SG_ 1729 MODULE_TEMP_04_12 "Module temperature04";
BA_ "FlexKomIsMotorola" SG_ 1729 MODULE_TEMP_04_12 1;
BA_ "GenSigSendType" SG_ 1729 MODULE_TEMP_03_12 0;
BA_ "GenSigCycleTime" SG_ 1729 MODULE_TEMP_03_12 40;
BA_ "FlexKomSigStartValue" SG_ 1729 MODULE_TEMP_03_12 "00h";
BA_ "GenSigTimeout_BMU" SG_ 1729 MODULE_TEMP_03_12 220;
BA_ "FlexKomSID" SG_ 1729 MODULE_TEMP_03_12 1074;
BA_ "FlexKomSigStartPos" SG_ 1729 MODULE_TEMP_03_12 39;
BA_ "FlexKomSigLaenge" SG_ 1729 MODULE_TEMP_03_12 8;
BA_ "FlexKomSigName" SG_ 1729 MODULE_TEMP_03_12 "MODULE_TEMP_03_12";
BA_ "FlexKomComment" SG_ 1729 MODULE_TEMP_03_12 "Module temperature03";
BA_ "FlexKomIsMotorola" SG_ 1729 MODULE_TEMP_03_12 1;
BA_ "GenSigSendType" SG_ 1729 MODULE_TEMP_02_12 0;
BA_ "GenSigCycleTime" SG_ 1729 MODULE_TEMP_02_12 40;
BA_ "FlexKomSigStartValue" SG_ 1729 MODULE_TEMP_02_12 "00h";
BA_ "GenSigTimeout_BMU" SG_ 1729 MODULE_TEMP_02_12 220;
BA_ "FlexKomSID" SG_ 1729 MODULE_TEMP_02_12 1062;
BA_ "FlexKomSigStartPos" SG_ 1729 MODULE_TEMP_02_12 31;
BA_ "FlexKomSigLaenge" SG_ 1729 MODULE_TEMP_02_12 8;
BA_ "FlexKomSigName" SG_ 1729 MODULE_TEMP_02_12 "MODULE_TEMP_02_12";
BA_ "FlexKomComment" SG_ 1729 MODULE_TEMP_02_12 "Module temperature02";
BA_ "FlexKomIsMotorola" SG_ 1729 MODULE_TEMP_02_12 1;
BA_ "GenSigSendType" SG_ 1729 MODULE_TEMP_01_12 0;
BA_ "GenSigCycleTime" SG_ 1729 MODULE_TEMP_01_12 40;
BA_ "FlexKomSigStartValue" SG_ 1729 MODULE_TEMP_01_12 "00h";
BA_ "GenSigTimeout_BMU" SG_ 1729 MODULE_TEMP_01_12 220;
BA_ "FlexKomSID" SG_ 1729 MODULE_TEMP_01_12 1050;
BA_ "FlexKomSigStartPos" SG_ 1729 MODULE_TEMP_01_12 23;
BA_ "FlexKomSigLaenge" SG_ 1729 MODULE_TEMP_01_12 8;
BA_ "FlexKomSigName" SG_ 1729 MODULE_TEMP_01_12 "MODULE_TEMP_01_12";
BA_ "FlexKomComment" SG_ 1729 MODULE_TEMP_01_12 "Module temperature01";
BA_ "FlexKomIsMotorola" SG_ 1729 MODULE_TEMP_01_12 1;
BA_ "GenSigSendType" SG_ 1729 NUM_TABLE_VALUE_12 0;
BA_ "GenSigCycleTime" SG_ 1729 NUM_TABLE_VALUE_12 40;
BA_ "FlexKomSigStartValue" SG_ 1729 NUM_TABLE_VALUE_12 "0Fh";
BA_ "GenSigStartValue" SG_ 1729 NUM_TABLE_VALUE_12 15;
BA_ "GenSigTimeout_BMU" SG_ 1729 NUM_TABLE_VALUE_12 220;
BA_ "FlexKomSID" SG_ 1729 NUM_TABLE_VALUE_12 1038;
BA_ "FlexKomSigStartPos" SG_ 1729 NUM_TABLE_VALUE_12 15;
BA_ "FlexKomSigLaenge" SG_ 1729 NUM_TABLE_VALUE_12 4;
BA_ "FlexKomSigName" SG_ 1729 NUM_TABLE_VALUE_12 "NUM_TABLE_VALUE_12";
BA_ "FlexKomComment" SG_ 1729 NUM_TABLE_VALUE_12 "Stored Automatic numbering table";
BA_ "FlexKomIsMotorola" SG_ 1729 NUM_TABLE_VALUE_12 1;
BA_ "GenSigSendType" SG_ 1729 BLC_DRV_STAT_12_12 0;
BA_ "GenSigCycleTime" SG_ 1729 BLC_DRV_STAT_12_12 40;
BA_ "FlexKomSigStartValue" SG_ 1729 BLC_DRV_STAT_12_12 "0000h";
BA_ "GenSigTimeout_BMU" SG_ 1729 BLC_DRV_STAT_12_12 220;
BA_ "FlexKomSID" SG_ 1729 BLC_DRV_STAT_12_12 719;
BA_ "FlexKomSigStartPos" SG_ 1729 BLC_DRV_STAT_12_12 7;
BA_ "FlexKomSigLaenge" SG_ 1729 BLC_DRV_STAT_12_12 16;
BA_ "FlexKomSigName" SG_ 1729 BLC_DRV_STAT_12_12 "BLC_DRV_STAT_12";
BA_ "FlexKomComment" SG_ 1729 BLC_DRV_STAT_12_12 "Balancer drive status packet";
BA_ "FlexKomIsMotorola" SG_ 1729 BLC_DRV_STAT_12_12 1;
BA_ "GenSigSendType" SG_ 1729 BLC_DRV_STAT_11_12 0;
BA_ "GenSigCycleTime" SG_ 1729 BLC_DRV_STAT_11_12 40;
BA_ "FlexKomSigStartValue" SG_ 1729 BLC_DRV_STAT_11_12 "0000h";
BA_ "GenSigTimeout_BMU" SG_ 1729 BLC_DRV_STAT_11_12 220;
BA_ "FlexKomSID" SG_ 1729 BLC_DRV_STAT_11_12 719;
BA_ "FlexKomSigStartPos" SG_ 1729 BLC_DRV_STAT_11_12 7;
BA_ "FlexKomSigLaenge" SG_ 1729 BLC_DRV_STAT_11_12 16;
BA_ "FlexKomSigName" SG_ 1729 BLC_DRV_STAT_11_12 "BLC_DRV_STAT_12";
BA_ "FlexKomComment" SG_ 1729 BLC_DRV_STAT_11_12 "Balancer drive status packet";
BA_ "FlexKomIsMotorola" SG_ 1729 BLC_DRV_STAT_11_12 1;
BA_ "GenSigSendType" SG_ 1729 BLC_DRV_STAT_10_12 0;
BA_ "GenSigCycleTime" SG_ 1729 BLC_DRV_STAT_10_12 40;
BA_ "FlexKomSigStartValue" SG_ 1729 BLC_DRV_STAT_10_12 "0000h";
BA_ "GenSigTimeout_BMU" SG_ 1729 BLC_DRV_STAT_10_12 220;
BA_ "FlexKomSID" SG_ 1729 BLC_DRV_STAT_10_12 719;
BA_ "FlexKomSigStartPos" SG_ 1729 BLC_DRV_STAT_10_12 7;
BA_ "FlexKomSigLaenge" SG_ 1729 BLC_DRV_STAT_10_12 16;
BA_ "FlexKomSigName" SG_ 1729 BLC_DRV_STAT_10_12 "BLC_DRV_STAT_12";
BA_ "FlexKomComment" SG_ 1729 BLC_DRV_STAT_10_12 "Balancer drive status packet";
BA_ "FlexKomIsMotorola" SG_ 1729 BLC_DRV_STAT_10_12 1;
BA_ "GenSigSendType" SG_ 1729 BLC_DRV_STAT_09_12 0;
BA_ "GenSigCycleTime" SG_ 1729 BLC_DRV_STAT_09_12 40;
BA_ "FlexKomSigStartValue" SG_ 1729 BLC_DRV_STAT_09_12 "0000h";
BA_ "GenSigTimeout_BMU" SG_ 1729 BLC_DRV_STAT_09_12 220;
BA_ "FlexKomSID" SG_ 1729 BLC_DRV_STAT_09_12 719;
BA_ "FlexKomSigStartPos" SG_ 1729 BLC_DRV_STAT_09_12 7;
BA_ "FlexKomSigLaenge" SG_ 1729 BLC_DRV_STAT_09_12 16;
BA_ "FlexKomSigName" SG_ 1729 BLC_DRV_STAT_09_12 "BLC_DRV_STAT_12";
BA_ "FlexKomComment" SG_ 1729 BLC_DRV_STAT_09_12 "Balancer drive status packet";
BA_ "FlexKomIsMotorola" SG_ 1729 BLC_DRV_STAT_09_12 1;
BA_ "GenSigSendType" SG_ 1729 BLC_DRV_STAT_08_12 0;
BA_ "GenSigCycleTime" SG_ 1729 BLC_DRV_STAT_08_12 40;
BA_ "FlexKomSigStartValue" SG_ 1729 BLC_DRV_STAT_08_12 "0000h";
BA_ "GenSigTimeout_BMU" SG_ 1729 BLC_DRV_STAT_08_12 220;
BA_ "FlexKomSID" SG_ 1729 BLC_DRV_STAT_08_12 719;
BA_ "FlexKomSigStartPos" SG_ 1729 BLC_DRV_STAT_08_12 7;
BA_ "FlexKomSigLaenge" SG_ 1729 BLC_DRV_STAT_08_12 16;
BA_ "FlexKomSigName" SG_ 1729 BLC_DRV_STAT_08_12 "BLC_DRV_STAT_12";
BA_ "FlexKomComment" SG_ 1729 BLC_DRV_STAT_08_12 "Balancer drive status packet";
BA_ "FlexKomIsMotorola" SG_ 1729 BLC_DRV_STAT_08_12 1;
BA_ "GenSigSendType" SG_ 1729 BLC_DRV_STAT_07_12 0;
BA_ "GenSigCycleTime" SG_ 1729 BLC_DRV_STAT_07_12 40;
BA_ "FlexKomSigStartValue" SG_ 1729 BLC_DRV_STAT_07_12 "0000h";
BA_ "GenSigTimeout_BMU" SG_ 1729 BLC_DRV_STAT_07_12 220;
BA_ "FlexKomSID" SG_ 1729 BLC_DRV_STAT_07_12 719;
BA_ "FlexKomSigStartPos" SG_ 1729 BLC_DRV_STAT_07_12 7;
BA_ "FlexKomSigLaenge" SG_ 1729 BLC_DRV_STAT_07_12 16;
BA_ "FlexKomSigName" SG_ 1729 BLC_DRV_STAT_07_12 "BLC_DRV_STAT_12";
BA_ "FlexKomComment" SG_ 1729 BLC_DRV_STAT_07_12 "Balancer drive status packet";
BA_ "FlexKomIsMotorola" SG_ 1729 BLC_DRV_STAT_07_12 1;
BA_ "GenSigSendType" SG_ 1729 BLC_DRV_STAT_06_12 0;
BA_ "GenSigCycleTime" SG_ 1729 BLC_DRV_STAT_06_12 40;
BA_ "FlexKomSigStartValue" SG_ 1729 BLC_DRV_STAT_06_12 "0000h";
BA_ "GenSigTimeout_BMU" SG_ 1729 BLC_DRV_STAT_06_12 220;
BA_ "FlexKomSID" SG_ 1729 BLC_DRV_STAT_06_12 719;
BA_ "FlexKomSigStartPos" SG_ 1729 BLC_DRV_STAT_06_12 7;
BA_ "FlexKomSigLaenge" SG_ 1729 BLC_DRV_STAT_06_12 16;
BA_ "FlexKomSigName" SG_ 1729 BLC_DRV_STAT_06_12 "BLC_DRV_STAT_12";
BA_ "FlexKomComment" SG_ 1729 BLC_DRV_STAT_06_12 "Balancer drive status packet";
BA_ "FlexKomIsMotorola" SG_ 1729 BLC_DRV_STAT_06_12 1;
BA_ "GenSigSendType" SG_ 1729 BLC_DRV_STAT_05_12 0;
BA_ "GenSigCycleTime" SG_ 1729 BLC_DRV_STAT_05_12 40;
BA_ "FlexKomSigStartValue" SG_ 1729 BLC_DRV_STAT_05_12 "0000h";
BA_ "GenSigTimeout_BMU" SG_ 1729 BLC_DRV_STAT_05_12 220;
BA_ "FlexKomSID" SG_ 1729 BLC_DRV_STAT_05_12 719;
BA_ "FlexKomSigStartPos" SG_ 1729 BLC_DRV_STAT_05_12 7;
BA_ "FlexKomSigLaenge" SG_ 1729 BLC_DRV_STAT_05_12 16;
BA_ "FlexKomSigName" SG_ 1729 BLC_DRV_STAT_05_12 "BLC_DRV_STAT_12";
BA_ "FlexKomComment" SG_ 1729 BLC_DRV_STAT_05_12 "Balancer drive status packet";
BA_ "FlexKomIsMotorola" SG_ 1729 BLC_DRV_STAT_05_12 1;
BA_ "GenSigSendType" SG_ 1729 BLC_DRV_STAT_04_12 0;
BA_ "GenSigCycleTime" SG_ 1729 BLC_DRV_STAT_04_12 40;
BA_ "FlexKomSigStartValue" SG_ 1729 BLC_DRV_STAT_04_12 "0000h";
BA_ "GenSigTimeout_BMU" SG_ 1729 BLC_DRV_STAT_04_12 220;
BA_ "FlexKomSID" SG_ 1729 BLC_DRV_STAT_04_12 719;
BA_ "FlexKomSigStartPos" SG_ 1729 BLC_DRV_STAT_04_12 7;
BA_ "FlexKomSigLaenge" SG_ 1729 BLC_DRV_STAT_04_12 16;
BA_ "FlexKomSigName" SG_ 1729 BLC_DRV_STAT_04_12 "BLC_DRV_STAT_12";
BA_ "FlexKomComment" SG_ 1729 BLC_DRV_STAT_04_12 "Balancer drive status packet";
BA_ "FlexKomIsMotorola" SG_ 1729 BLC_DRV_STAT_04_12 1;
BA_ "GenSigSendType" SG_ 1729 BLC_DRV_STAT_03_12 0;
BA_ "GenSigCycleTime" SG_ 1729 BLC_DRV_STAT_03_12 40;
BA_ "FlexKomSigStartValue" SG_ 1729 BLC_DRV_STAT_03_12 "0000h";
BA_ "GenSigTimeout_BMU" SG_ 1729 BLC_DRV_STAT_03_12 220;
BA_ "FlexKomSID" SG_ 1729 BLC_DRV_STAT_03_12 719;
BA_ "FlexKomSigStartPos" SG_ 1729 BLC_DRV_STAT_03_12 7;
BA_ "FlexKomSigLaenge" SG_ 1729 BLC_DRV_STAT_03_12 16;
BA_ "FlexKomSigName" SG_ 1729 BLC_DRV_STAT_03_12 "BLC_DRV_STAT_12";
BA_ "FlexKomComment" SG_ 1729 BLC_DRV_STAT_03_12 "Balancer drive status packet";
BA_ "FlexKomIsMotorola" SG_ 1729 BLC_DRV_STAT_03_12 1;
BA_ "GenSigSendType" SG_ 1729 BLC_DRV_STAT_02_12 0;
BA_ "GenSigCycleTime" SG_ 1729 BLC_DRV_STAT_02_12 40;
BA_ "FlexKomSigStartValue" SG_ 1729 BLC_DRV_STAT_02_12 "0000h";
BA_ "GenSigTimeout_BMU" SG_ 1729 BLC_DRV_STAT_02_12 220;
BA_ "FlexKomSID" SG_ 1729 BLC_DRV_STAT_02_12 719;
BA_ "FlexKomSigStartPos" SG_ 1729 BLC_DRV_STAT_02_12 7;
BA_ "FlexKomSigLaenge" SG_ 1729 BLC_DRV_STAT_02_12 16;
BA_ "FlexKomSigName" SG_ 1729 BLC_DRV_STAT_02_12 "BLC_DRV_STAT_12";
BA_ "FlexKomComment" SG_ 1729 BLC_DRV_STAT_02_12 "Balancer drive status packet";
BA_ "FlexKomIsMotorola" SG_ 1729 BLC_DRV_STAT_02_12 1;
BA_ "GenSigSendType" SG_ 1729 BLC_DRV_STAT_01_12 0;
BA_ "GenSigCycleTime" SG_ 1729 BLC_DRV_STAT_01_12 40;
BA_ "FlexKomSigStartValue" SG_ 1729 BLC_DRV_STAT_01_12 "0000h";
BA_ "GenSigTimeout_BMU" SG_ 1729 BLC_DRV_STAT_01_12 220;
BA_ "FlexKomSID" SG_ 1729 BLC_DRV_STAT_01_12 719;
BA_ "FlexKomSigStartPos" SG_ 1729 BLC_DRV_STAT_01_12 7;
BA_ "FlexKomSigLaenge" SG_ 1729 BLC_DRV_STAT_01_12 16;
BA_ "FlexKomSigName" SG_ 1729 BLC_DRV_STAT_01_12 "BLC_DRV_STAT_12";
BA_ "FlexKomComment" SG_ 1729 BLC_DRV_STAT_01_12 "Balancer drive status packet";
BA_ "FlexKomIsMotorola" SG_ 1729 BLC_DRV_STAT_01_12 1;
VAL_ 1770 CSCNT_DEV_10 65535 "SNA" ;
VAL_ 1770 CRRLTIN_YY_10 255 "SNA" ;
VAL_ 1770 CELL_RSIST_YY_10 65535 "SNA" ;
VAL_ 1770 FRAME_NO_YY_10 255 "SNA" ;
VAL_ 1771 CSCNT_DEV_11 65535 "SNA" ;
VAL_ 1771 CRRLTIN_YY_11 255 "SNA" ;
VAL_ 1771 CELL_RSIST_YY_11 65535 "SNA" ;
VAL_ 1771 FRAME_NO_YY_11 255 "SNA" ;
VAL_ 1763 CSCNT_DEV_03 65535 "SNA" ;
VAL_ 1763 CRRLTIN_YY_03 255 "SNA" ;
VAL_ 1763 CELL_RSIST_YY_03 65535 "SNA" ;
VAL_ 1763 FRAME_NO_YY_03 255 "SNA" ;
VAL_ 1769 CSCNT_DEV_09 65535 "SNA" ;
VAL_ 1769 CRRLTIN_YY_09 255 "SNA" ;
VAL_ 1769 CELL_RSIST_YY_09 65535 "SNA" ;
VAL_ 1769 FRAME_NO_YY_09 255 "SNA" ;
VAL_ 1762 CSCNT_DEV_02 65535 "SNA" ;
VAL_ 1762 CRRLTIN_YY_02 255 "SNA" ;
VAL_ 1762 CELL_RSIST_YY_02 65535 "SNA" ;
VAL_ 1762 FRAME_NO_YY_02 255 "SNA" ;
VAL_ 1768 CSCNT_DEV_08 65535 "SNA" ;
VAL_ 1768 CRRLTIN_YY_08 255 "SNA" ;
VAL_ 1768 CELL_RSIST_YY_08 65535 "SNA" ;
VAL_ 1768 FRAME_NO_YY_08 255 "SNA" ;
VAL_ 1765 CSCNT_DEV_05 65535 "SNA" ;
VAL_ 1765 CRRLTIN_YY_05 255 "SNA" ;
VAL_ 1765 CELL_RSIST_YY_05 65535 "SNA" ;
VAL_ 1765 FRAME_NO_YY_05 255 "SNA" ;
VAL_ 1761 CSCNT_DEV_01 65535 "SNA" ;
VAL_ 1761 CRRLTIN_YY_01 255 "SNA" ;
VAL_ 1761 CELL_RSIST_YY_01 65535 "SNA" ;
VAL_ 1761 FRAME_NO_YY_01 255 "SNA" ;
VAL_ 1767 CSCNT_DEV_07 65535 "SNA" ;
VAL_ 1767 CRRLTIN_YY_07 255 "SNA" ;
VAL_ 1767 CELL_RSIST_YY_07 65535 "SNA" ;
VAL_ 1767 FRAME_NO_YY_07 255 "SNA" ;
VAL_ 1764 CSCNT_DEV_04 65535 "SNA" ;
VAL_ 1764 CRRLTIN_YY_04 255 "SNA" ;
VAL_ 1764 CELL_RSIST_YY_04 65535 "SNA" ;
VAL_ 1764 FRAME_NO_YY_04 255 "SNA" ;
VAL_ 962 CSM_BATT_CURRENT -1 "SNA" ;
VAL_ 1732 CELL_VOLT_12_12 65535 "SNA" ;
VAL_ 1732 CELL_VOLT_11_12 65535 "SNA" ;
VAL_ 1732 CELL_VOLT_10_12 65535 "SNA" ;
VAL_ 1732 CELL_VOLT_09_12 65535 "SNA" ;
VAL_ 1716 CELL_VOLT_12_11 65535 "SNA" ;
VAL_ 1716 CELL_VOLT_11_11 65535 "SNA" ;
VAL_ 1716 CELL_VOLT_10_11 65535 "SNA" ;
VAL_ 1716 CELL_VOLT_09_11 65535 "SNA" ;
VAL_ 1700 CELL_VOLT_12_10 65535 "SNA" ;
VAL_ 1700 CELL_VOLT_11_10 65535 "SNA" ;
VAL_ 1700 CELL_VOLT_10_10 65535 "SNA" ;
VAL_ 1700 CELL_VOLT_09_10 65535 "SNA" ;
VAL_ 1684 CELL_VOLT_12_09 65535 "SNA" ;
VAL_ 1684 CELL_VOLT_11_09 65535 "SNA" ;
VAL_ 1684 CELL_VOLT_10_09 65535 "SNA" ;
VAL_ 1684 CELL_VOLT_09_09 65535 "SNA" ;
VAL_ 1668 CELL_VOLT_12_08 65535 "SNA" ;
VAL_ 1668 CELL_VOLT_11_08 65535 "SNA" ;
VAL_ 1668 CELL_VOLT_10_08 65535 "SNA" ;
VAL_ 1668 CELL_VOLT_09_08 65535 "SNA" ;
VAL_ 1652 CELL_VOLT_12_07 65535 "SNA" ;
VAL_ 1652 CELL_VOLT_11_07 65535 "SNA" ;
VAL_ 1652 CELL_VOLT_10_07 65535 "SNA" ;
VAL_ 1652 CELL_VOLT_09_07 65535 "SNA" ;
VAL_ 1636 CELL_VOLT_12_06 65535 "SNA" ;
VAL_ 1636 CELL_VOLT_11_06 65535 "SNA" ;
VAL_ 1636 CELL_VOLT_10_06 65535 "SNA" ;
VAL_ 1636 CELL_VOLT_09_06 65535 "SNA" ;
VAL_ 1620 CELL_VOLT_12_05 65535 "SNA" ;
VAL_ 1620 CELL_VOLT_11_05 65535 "SNA" ;
VAL_ 1620 CELL_VOLT_10_05 65535 "SNA" ;
VAL_ 1620 CELL_VOLT_09_05 65535 "SNA" ;
VAL_ 1604 CELL_VOLT_12_04 65535 "SNA" ;
VAL_ 1604 CELL_VOLT_11_04 65535 "SNA" ;
VAL_ 1604 CELL_VOLT_10_04 65535 "SNA" ;
VAL_ 1604 CELL_VOLT_09_04 65535 "SNA" ;
VAL_ 1588 CELL_VOLT_12_03 65535 "SNA" ;
VAL_ 1588 CELL_VOLT_11_03 65535 "SNA" ;
VAL_ 1588 CELL_VOLT_10_03 65535 "SNA" ;
VAL_ 1588 CELL_VOLT_09_03 65535 "SNA" ;
VAL_ 1572 CELL_VOLT_12_02 65535 "SNA" ;
VAL_ 1572 CELL_VOLT_11_02 65535 "SNA" ;
VAL_ 1572 CELL_VOLT_10_02 65535 "SNA" ;
VAL_ 1572 CELL_VOLT_09_02 65535 "SNA" ;
VAL_ 1556 CELL_VOLT_12_01 65535 "SNA" ;
VAL_ 1556 CELL_VOLT_11_01 65535 "SNA" ;
VAL_ 1556 CELL_VOLT_10_01 65535 "SNA" ;
VAL_ 1556 CELL_VOLT_09_01 65535 "SNA" ;
VAL_ 1731 CELL_VOLT_08_12 65535 "SNA" ;
VAL_ 1731 CELL_VOLT_07_12 65535 "SNA" ;
VAL_ 1731 CELL_VOLT_06_12 65535 "SNA" ;
VAL_ 1731 CELL_VOLT_05_12 65535 "SNA" ;
VAL_ 1715 CELL_VOLT_08_11 65535 "SNA" ;
VAL_ 1715 CELL_VOLT_07_11 65535 "SNA" ;
VAL_ 1715 CELL_VOLT_06_11 65535 "SNA" ;
VAL_ 1715 CELL_VOLT_05_11 65535 "SNA" ;
VAL_ 1699 CELL_VOLT_08_10 65535 "SNA" ;
VAL_ 1699 CELL_VOLT_07_10 65535 "SNA" ;
VAL_ 1699 CELL_VOLT_06_10 65535 "SNA" ;
VAL_ 1699 CELL_VOLT_05_10 65535 "SNA" ;
VAL_ 1683 CELL_VOLT_08_09 65535 "SNA" ;
VAL_ 1683 CELL_VOLT_07_09 65535 "SNA" ;
VAL_ 1683 CELL_VOLT_06_09 65535 "SNA" ;
VAL_ 1683 CELL_VOLT_05_09 65535 "SNA" ;
VAL_ 1667 CELL_VOLT_08_08 65535 "SNA" ;
VAL_ 1667 CELL_VOLT_07_08 65535 "SNA" ;
VAL_ 1667 CELL_VOLT_06_08 65535 "SNA" ;
VAL_ 1667 CELL_VOLT_05_08 65535 "SNA" ;
VAL_ 1651 CELL_VOLT_08_07 65535 "SNA" ;
VAL_ 1651 CELL_VOLT_07_07 65535 "SNA" ;
VAL_ 1651 CELL_VOLT_06_07 65535 "SNA" ;
VAL_ 1651 CELL_VOLT_05_07 65535 "SNA" ;
VAL_ 1635 CELL_VOLT_08_06 65535 "SNA" ;
VAL_ 1635 CELL_VOLT_07_06 65535 "SNA" ;
VAL_ 1635 CELL_VOLT_06_06 65535 "SNA" ;
VAL_ 1635 CELL_VOLT_05_06 65535 "SNA" ;
VAL_ 1619 CELL_VOLT_08_05 65535 "SNA" ;
VAL_ 1619 CELL_VOLT_07_05 65535 "SNA" ;
VAL_ 1619 CELL_VOLT_06_05 65535 "SNA" ;
VAL_ 1619 CELL_VOLT_05_05 65535 "SNA" ;
VAL_ 1603 CELL_VOLT_08_04 65535 "SNA" ;
VAL_ 1603 CELL_VOLT_07_04 65535 "SNA" ;
VAL_ 1603 CELL_VOLT_06_04 65535 "SNA" ;
VAL_ 1603 CELL_VOLT_05_04 65535 "SNA" ;
VAL_ 1587 CELL_VOLT_08_03 65535 "SNA" ;
VAL_ 1587 CELL_VOLT_07_03 65535 "SNA" ;
VAL_ 1587 CELL_VOLT_06_03 65535 "SNA" ;
VAL_ 1587 CELL_VOLT_05_03 65535 "SNA" ;
VAL_ 1571 CELL_VOLT_08_02 65535 "SNA" ;
VAL_ 1571 CELL_VOLT_07_02 65535 "SNA" ;
VAL_ 1571 CELL_VOLT_06_02 65535 "SNA" ;
VAL_ 1571 CELL_VOLT_05_02 65535 "SNA" ;
VAL_ 1555 CELL_VOLT_08_01 65535 "SNA" ;
VAL_ 1555 CELL_VOLT_07_01 65535 "SNA" ;
VAL_ 1555 CELL_VOLT_06_01 65535 "SNA" ;
VAL_ 1555 CELL_VOLT_05_01 65535 "SNA" ;
VAL_ 1730 CELL_VOLT_04_12 65535 "SNA" ;
VAL_ 1730 CELL_VOLT_03_12 65535 "SNA" ;
VAL_ 1730 CELL_VOLT_02_12 65535 "SNA" ;
VAL_ 1730 CELL_VOLT_01_12 65535 "SNA" ;
VAL_ 1714 CELL_VOLT_04_11 65535 "SNA" ;
VAL_ 1714 CELL_VOLT_03_11 65535 "SNA" ;
VAL_ 1714 CELL_VOLT_02_11 65535 "SNA" ;
VAL_ 1714 CELL_VOLT_01_11 65535 "SNA" ;
VAL_ 1698 CELL_VOLT_04_10 65535 "SNA" ;
VAL_ 1698 CELL_VOLT_03_10 65535 "SNA" ;
VAL_ 1698 CELL_VOLT_02_10 65535 "SNA" ;
VAL_ 1698 CELL_VOLT_01_10 65535 "SNA" ;
VAL_ 1682 CELL_VOLT_04_09 65535 "SNA" ;
VAL_ 1682 CELL_VOLT_03_09 65535 "SNA" ;
VAL_ 1682 CELL_VOLT_02_09 65535 "SNA" ;
VAL_ 1682 CELL_VOLT_01_09 65535 "SNA" ;
VAL_ 1666 CELL_VOLT_04_08 65535 "SNA" ;
VAL_ 1666 CELL_VOLT_03_08 65535 "SNA" ;
VAL_ 1666 CELL_VOLT_02_08 65535 "SNA" ;
VAL_ 1666 CELL_VOLT_01_08 65535 "SNA" ;
VAL_ 1650 CELL_VOLT_04_07 65535 "SNA" ;
VAL_ 1650 CELL_VOLT_03_07 65535 "SNA" ;
VAL_ 1650 CELL_VOLT_02_07 65535 "SNA" ;
VAL_ 1650 CELL_VOLT_01_07 65535 "SNA" ;
VAL_ 1634 CELL_VOLT_04_06 65535 "SNA" ;
VAL_ 1634 CELL_VOLT_03_06 65535 "SNA" ;
VAL_ 1634 CELL_VOLT_02_06 65535 "SNA" ;
VAL_ 1634 CELL_VOLT_01_06 65535 "SNA" ;
VAL_ 1618 CELL_VOLT_04_05 65535 "SNA" ;
VAL_ 1618 CELL_VOLT_03_05 65535 "SNA" ;
VAL_ 1618 CELL_VOLT_02_05 65535 "SNA" ;
VAL_ 1618 CELL_VOLT_01_05 65535 "SNA" ;
VAL_ 1602 CELL_VOLT_04_04 65535 "SNA" ;
VAL_ 1602 CELL_VOLT_03_04 65535 "SNA" ;
VAL_ 1602 CELL_VOLT_02_04 65535 "SNA" ;
VAL_ 1602 CELL_VOLT_01_04 65535 "SNA" ;
VAL_ 1586 CELL_VOLT_04_03 65535 "SNA" ;
VAL_ 1586 CELL_VOLT_03_03 65535 "SNA" ;
VAL_ 1586 CELL_VOLT_02_03 65535 "SNA" ;
VAL_ 1586 CELL_VOLT_01_03 65535 "SNA" ;
VAL_ 1570 CELL_VOLT_04_02 65535 "SNA" ;
VAL_ 1570 CELL_VOLT_03_02 65535 "SNA" ;
VAL_ 1570 CELL_VOLT_02_02 65535 "SNA" ;
VAL_ 1570 CELL_VOLT_01_02 65535 "SNA" ;
VAL_ 1554 CELL_VOLT_04_01 65535 "SNA" ;
VAL_ 1554 CELL_VOLT_03_01 65535 "SNA" ;
VAL_ 1554 CELL_VOLT_02_01 65535 "SNA" ;
VAL_ 1554 CELL_VOLT_01_01 65535 "SNA" ;
VAL_ 1729 MODULE_TEMP_06_12 255 "SNA" ;
VAL_ 1729 MODULE_TEMP_05_12 255 "SNA" ;
VAL_ 1729 MODULE_TEMP_04_12 255 "SNA" ;
VAL_ 1729 MODULE_TEMP_03_12 255 "SNA" ;
VAL_ 1729 MODULE_TEMP_02_12 255 "SNA" ;
VAL_ 1729 MODULE_TEMP_01_12 255 "SNA" ;
VAL_ 1729 NUM_TABLE_VALUE_12 15 "SIGNAL_DEFAULT" 14 "BATTERY_PACK_TYPE_14" 13 "BATTERY_PACK_TYPE_13" 12 "BATTERY_PACK_TYPE_12" 11 "BATTERY_PACK_TYPE_11" 10 "BATTERY_PACK_TYPE_10" 9 "BATTERY_PACK_TYPE_9" 8 "BATTERY_PACK_TYPE_8" 7 "BATTERY_PACK_TYPE_7" 6 "BATTERY_PACK_TYPE_6" 5 "BATTERY_PACK_TYPE_5" 4 "BATTERY_PACK_TYPE_4" 3 "BATTERY_PACK_TYPE_3" 2 "BATTERY_PACK_TYPE_2" 1 "BATTERY_PACK_TYPE_1" 0 "BATTERY_PACK_TYPE_0" ;
SIG_GROUP_ 1761 New_Signal_Group_2 1 :;
